VERSION ""

NS_ :

BS_:

BU_: AHLM ASBS CADM CBC DIAGNOST DPDM DTCM ECM EHPS ESC ESL ESM ETM EVCU2 GPF IC IRCM LTM OCM ORC PTS RF_HUB SCCM SGW TBM TCM

BO_ 315 HCP_C1: 8 EVCU2
 SG_ MIL_OnRq_HCP : 6|1@1+ (1,0) [0|0] ""  ECM,ETM,SGW,TBM
 SG_ HybSysEmsMlfAtv : 7|1@1+ (1,0) [0|0] ""  SGW
 SG_ HCPPopUpMessage1 : 8|1@1+ (1,0) [0|0] ""  IC,SGW
 SG_ HCPPopUpMessage2 : 9|1@1+ (1,0) [0|0] ""  IC,SGW
 SG_ HCPPopUpMessage3 : 10|1@1+ (1,0) [0|0] ""  IC,SGW
 SG_ HCPPopUpMessage4 : 11|1@1+ (1,0) [0|0] ""  IC,SGW
 SG_ HCPPopUpMessage5 : 12|1@1+ (1,0) [0|0] ""  IC,SGW
 SG_ HCPPopUpMessage6 : 13|1@1+ (1,0) [0|0] ""  IC,SGW
 SG_ HCPPopUpMessage7 : 14|1@1+ (1,0) [0|0] ""  IC,SGW
 SG_ HCPOutputPwrV : 29|1@1+ (1,0) [0|0] ""  IC,SGW
 SG_ HCPCoachDispV : 30|1@1+ (1,0) [0|0] ""  IC,SGW
 SG_ HCPOutputPwr : 32|8@1+ (1,-100) [-100|100] "%"  IC,SGW
 SG_ HCPCoachDisp : 40|8@1+ (1,-100) [-100|100] "%"  IC,SGW
 SG_ HCPPopUpMessage8 : 15|1@1+ (1,0) [0|0] ""  IC,SGW
 SG_ HCPPopUpMessage9 : 0|1@1+ (1,0) [0|0] ""  IC,SGW
 SG_ HCPPopUpMessage10 : 24|1@1+ (1,0) [0|0] ""  IC,SGW
 SG_ DriveMdstat : 48|4@1+ (1,0) [0|0] ""  CBC,ECM,ETM,IC,LTM,SGW
 SG_ DrvMode_PopUpRqst : 25|4@1+ (1,0) [0|0] ""  IC,SGW
 SG_ GrShiftIndication : 1|2@1+ (1,0) [0|0] ""  IC,SGW
 SG_ HCPPopUpMessage12 : 3|2@1+ (1,0) [0|0] ""  IC,SGW
 SG_ MaxRegenTelltale : 16|2@1+ (1,0) [0|0] ""  IC,SGW
 SG_ MC_HCP_C1 : 52|4@1+ (1,0) [0|15] ""  ECM,IC,SGW,TCM
 SG_ CRC_HCP_C1 : 56|8@1+ (1,0) [0|0] ""  ECM,IC,SGW,TCM
 SG_ ThermalRunaway_LampReq : 18|1@1+ (1,0) [0|0] ""  IC,SGW

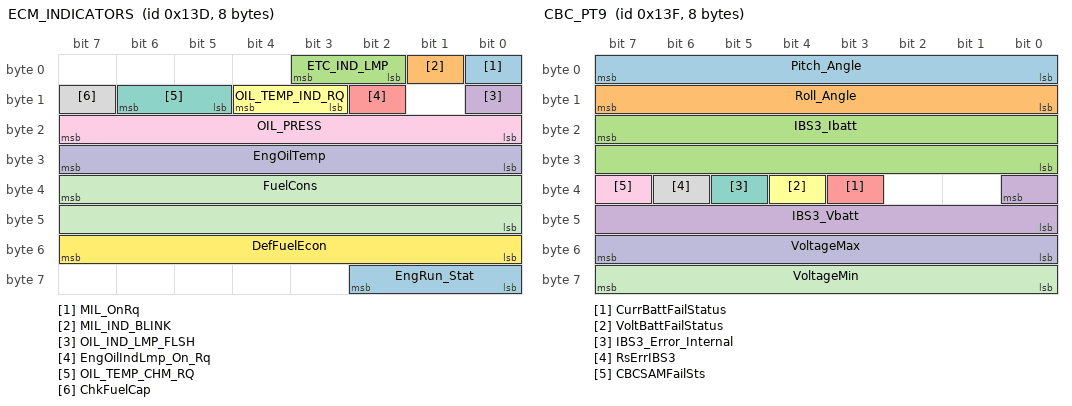
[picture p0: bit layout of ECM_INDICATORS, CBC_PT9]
BO_ 317 ECM_INDICATORS: 8 ECM
 SG_ MIL_OnRq : 0|1@1+ (1,0) [0|0] ""  CBC,ETM,EVCU2,IC,ORC,SGW,TBM
 SG_ MIL_IND_BLINK : 1|1@1+ (1,0) [0|0] ""  CBC,EVCU2,IC,ORC,SGW
 SG_ ETC_IND_LMP : 2|2@1+ (1,0) [0|0] ""  CBC,ETM,IC,SGW,TBM
 SG_ OIL_IND_LMP_FLSH : 8|1@1+ (1,0) [0|0] ""  ETM,IC,SGW,TBM
 SG_ EngOilIndLmp_On_Rq : 10|1@1+ (1,0) [0|0] ""  CBC,ETM,IC,SGW,TBM
 SG_ OIL_TEMP_IND_RQ : 11|2@1+ (1,0) [0|0] ""  ETM,IC,SGW,TBM
 SG_ OIL_TEMP_CHM_RQ : 13|2@1+ (1,0) [0|0] ""  SGW
 SG_ ChkFuelCap : 15|1@1+ (1,0) [0|0] ""  ETM,IC,SGW,TBM
 SG_ OIL_PRESS : 16|8@1+ (4,0) [0|1016] "kPaG"  ETM,IC,SGW,TBM
 SG_ EngOilTemp : 24|8@1+ (1,-40) [-40|160] "∞C"  ETM,IC,SGW,TBM,TCM
 SG_ FuelCons : 39|16@0+ (0.21668,0) [0|14200] "µl/100ms"  ETM,EVCU2,IC,SGW,TBM
 SG_ DefFuelEcon : 48|8@1+ (0.2,0) [0|50] "kmpl"  ETM,IC,SGW,TBM
 SG_ EngRun_Stat : 56|3@1+ (1,0) [0|0] ""  CBC,DTCM,ESC,EVCU2,IC,RF_HUB,SGW,TCM

BO_ 319 CBC_PT9: 8 CBC
 SG_ Pitch_Angle : 0|8@1+ (1,-90) [-90|90] "∞"  IC,SGW
 SG_ Roll_Angle : 8|8@1+ (1,-90) [-90|90] "∞"  IC,SGW
 SG_ IBS3_Ibatt : 23|16@0+ (0.02,-1000) [-1000|310.68] "A"  ECM,ETM,EVCU2,SGW,TBM
 SG_ IBS3_Vbatt : 32|9@0+ (0.025,5) [5|17.75] "V"  ECM,ETM,EVCU2,ORC,SGW,TBM
 SG_ CurrBattFailStatus : 35|1@1+ (1,0) [0|0] ""  ECM,EVCU2,SGW
 SG_ VoltBattFailStatus : 36|1@1+ (1,0) [0|0] ""  ECM,EVCU2,SGW
 SG_ IBS3_Error_Internal : 37|1@1+ (1,0) [0|0] ""  ECM,SGW
 SG_ RsErrIBS3 : 38|1@1+ (1,0) [0|0] ""  ECM,SGW
 SG_ CBCSAMFailSts : 39|1@1+ (1,0) [0|0] ""  ECM,SGW
 SG_ VoltageMax : 48|8@1+ (0.025,10.6) [10.6|16.975] "Volts"  ECM,SGW
 SG_ VoltageMin : 56|8@1+ (0.025,10.6) [10.6|16.975] "Volts"  ECM,SGW

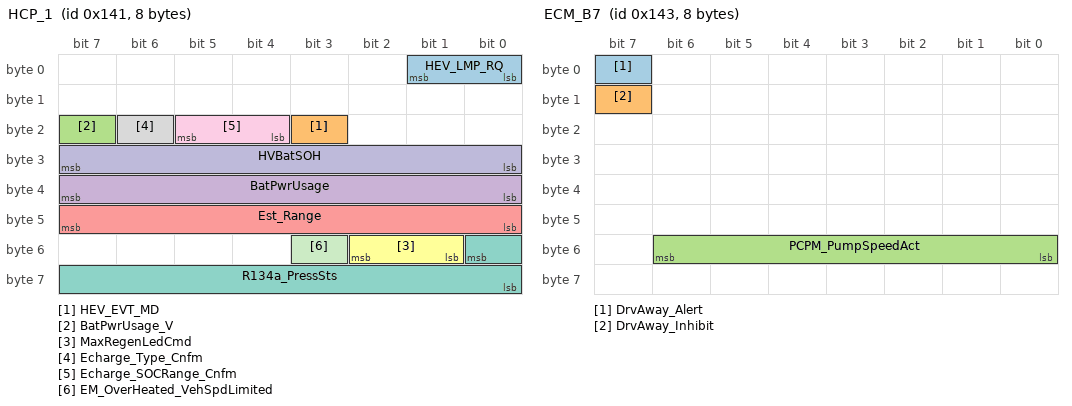
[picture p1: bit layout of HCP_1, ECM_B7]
BO_ 321 HCP_1: 8 EVCU2
 SG_ HEV_LMP_RQ : 0|2@1+ (1,0) [0|0] ""  ETM,IC,ORC,SGW,TBM
 SG_ HEV_EVT_MD : 19|1@1+ (1,0) [0|0] ""  CADM,CBC,ETM,IC,IRCM,SGW,TBM
 SG_ BatPwrUsage_V : 23|1@1+ (1,0) [0|0] ""  SGW
 SG_ BatPwrUsage : 32|8@1+ (1,-125) [-125|130] "kW"  IC,SGW
 SG_ Est_Range : 40|8@1+ (1,0) [0|254] "km"  ETM,IC,SGW,TBM
 SG_ MaxRegenLedCmd : 49|2@1+ (1,0) [0|0] ""  CBC,SGW
 SG_ R134a_PressSts : 48|9@0+ (0.1,0) [0|40] "bar"  CBC,SGW
 SG_ Echarge_Type_Cnfm : 22|1@1+ (1,0) [0|0] ""  CBC,SGW
 SG_ Echarge_SOCRange_Cnfm : 20|2@1+ (1,0) [0|0] ""  CBC,SGW
 SG_ HVBatSOH : 24|8@1+ (0.2,50) [50|100] "%"  ETM,SGW,TBM
 SG_ EM_OverHeated_VehSpdLimited : 51|1@1+ (1,0) [0|0] ""  IC,SGW

BO_ 323 ECM_B7: 8 ECM
 SG_ DrvAway_Alert : 7|1@1+ (1,0) [0|0] ""  IC,ORC,SGW
 SG_ DrvAway_Inhibit : 15|1@1+ (1,0) [0|0] ""  IC,PTS,SGW
 SG_ PCPM_PumpSpeedAct : 48|7@1+ (1,0) [0|100] "%"  SGW

BO_ 327 ESP_B2: 8 ESC
 SG_ MIL_OnRq_ESC : 2|1@1+ (1,0) [0|0] ""  ECM,ETM,SGW,TBM
 SG_ ESCSysEmsMlfAtv : 18|1@1+ (1,0) [0|0] ""  EVCU2,SGW

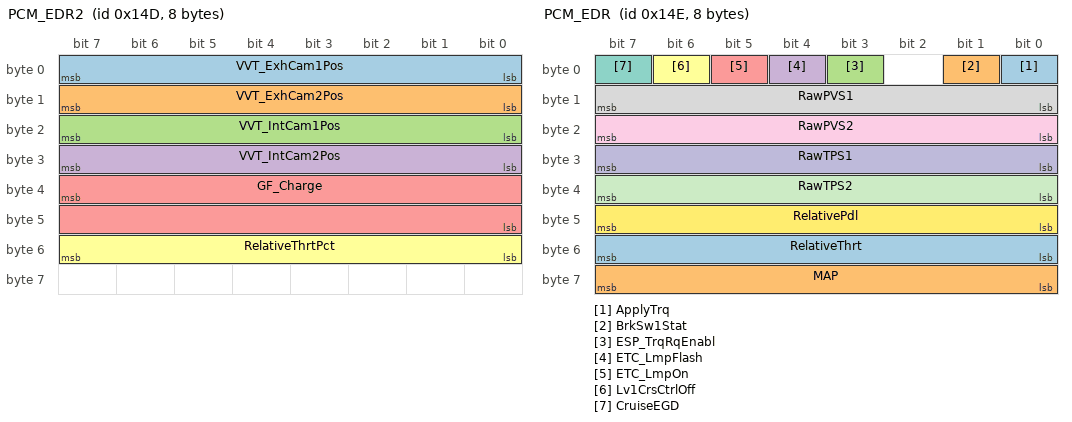
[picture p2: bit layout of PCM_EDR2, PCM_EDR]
BO_ 333 PCM_EDR2: 8 ECM
 SG_ VVT_ExhCam1Pos : 0|8@1+ (1,0) [1|255] "Degrees"  SGW
 SG_ VVT_ExhCam2Pos : 8|8@1+ (1,0) [1|255] "Degrees"  SGW
 SG_ VVT_IntCam1Pos : 16|8@1+ (1,0) [1|255] "Degrees"  SGW
 SG_ VVT_IntCam2Pos : 24|8@1+ (1,0) [1|255] "Degrees"  SGW
 SG_ GF_Charge : 39|16@0+ (0.2,0) [0|13106.8] "mg/cycle/cyl"  ETM,ORC,SGW,TBM
 SG_ RelativeThrtPct : 48|8@1+ (0.4,0) [0|100] "%"  ORC,SGW

BO_ 334 PCM_EDR: 8 ECM
 SG_ ApplyTrq : 0|1@1+ (1,0) [0|0] ""  SGW
 SG_ BrkSw1Stat : 1|1@1+ (1,0) [0|0] ""  ETM,SGW,TBM
 SG_ ESP_TrqRqEnabl : 3|1@1+ (1,0) [0|0] ""  ORC,SGW
 SG_ ETC_LmpFlash : 4|1@1+ (1,0) [0|0] ""  ORC,SGW
 SG_ ETC_LmpOn : 5|1@1+ (1,0) [0|0] ""  ORC,SGW
 SG_ Lv1CrsCtrlOff : 6|1@1+ (1,0) [0|0] ""  ORC,SGW
 SG_ CruiseEGD : 7|1@1+ (1,0) [0|0] ""  SGW
 SG_ RawPVS1 : 8|8@1+ (0.019607843,0) [0|4.98] "Volts"  ORC,SGW
 SG_ RawPVS2 : 16|8@1+ (0.019607843,0) [0|4.98] "Volts"  ORC,SGW
 SG_ RawTPS1 : 24|8@1+ (0.019607843,0) [0|4.98] "Volts"  ORC,SGW
 SG_ RawTPS2 : 32|8@1+ (0.019607843,0) [0|4.98] "Volts"  ORC,SGW
 SG_ RelativePdl : 40|8@1+ (0.019607843,0) [0|4.98] "Volts"  SGW
 SG_ RelativeThrt : 48|8@1+ (0.019607843,0) [0|4.98] "Volts"  SGW
 SG_ MAP : 56|8@1+ (0.8,0) [0|203.2] "kPa"  ESC,SGW

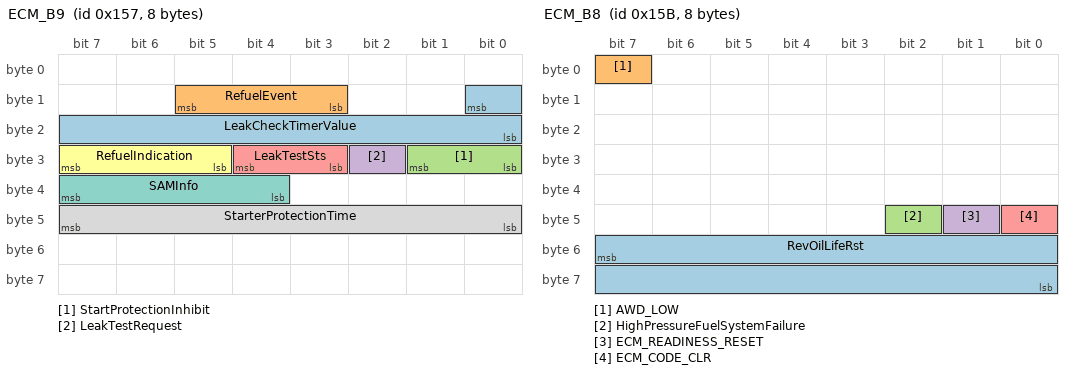
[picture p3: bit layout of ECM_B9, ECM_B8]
BO_ 343 ECM_B9: 8 ECM
 SG_ LeakCheckTimerValue : 8|9@0+ (1,0) [0|510] "min"  CBC,SGW
 SG_ RefuelEvent : 11|3@1+ (1,0) [0|0] ""  CBC,SGW
 SG_ StartProtectionInhibit : 24|2@1+ (1,0) [0|0] ""  IC,SGW
 SG_ LeakTestRequest : 26|1@1+ (1,0) [0|0] ""  CBC,SGW
 SG_ LeakTestSts : 27|2@1+ (1,0) [0|0] ""  CBC,SGW
 SG_ RefuelIndication : 29|3@1+ (1,0) [0|0] ""  IC,SGW
 SG_ SAMInfo : 36|4@1+ (1,0) [0|0] ""  CBC,SGW
 SG_ StarterProtectionTime : 40|8@1+ (1,0) [0|254] "sec"  IC,SGW

BO_ 347 ECM_B8: 8 ECM
 SG_ RevOilLifeRst : 55|16@0+ (1000,0) [0|65534000] "Rev's"  CBC,SGW
 SG_ AWD_LOW : 7|1@1+ (1,0) [0|0] ""  SGW
 SG_ HighPressureFuelSystemFailure : 42|1@1+ (1,0) [0|0] ""  IC,SGW
 SG_ ECM_READINESS_RESET : 41|1@1+ (1,0) [0|0] ""  ESC,EVCU2,SGW,TCM
 SG_ ECM_CODE_CLR : 40|1@1+ (1,0) [0|0] ""  ESC,EVCU2,SGW,TCM

BO_ 423 STATUS_C_ESL: 2 ESL
 SG_ ESLSts : 12|3@1+ (1,0) [0|0] ""  SGW
 SG_ KeyOffWithHighSpeedSts : 15|1@1+ (1,0) [0|0] ""  CBC,SGW

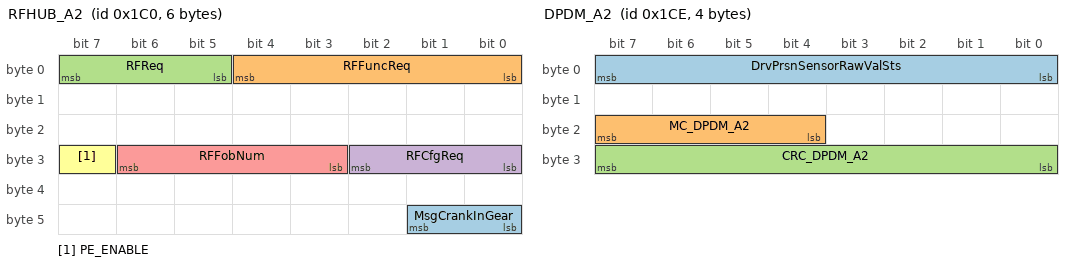
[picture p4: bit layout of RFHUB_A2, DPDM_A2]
BO_ 448 RFHUB_A2: 6 RF_HUB
 SG_ MsgCrankInGear : 40|2@1+ (1,0) [0|0] ""  IC,SGW
 SG_ RFFuncReq : 0|5@1+ (1,0) [0|0] ""  CBC,IC,SGW,TBM
 SG_ RFReq : 5|3@1+ (1,0) [0|0] ""  CBC,ETM,IC,SGW,TBM
 SG_ RFCfgReq : 24|3@1+ (1,0) [0|0] ""  CBC,SGW
 SG_ RFFobNum : 27|4@1+ (1,0) [0|0] ""  CBC,SGW
 SG_ PE_ENABLE : 31|1@1+ (1,0) [0|0] ""  CBC,SGW

BO_ 456 CBC_VTA: 4 CBC
 SG_ VTA_STAT : 0|3@1+ (1,0) [0|0] ""  ETM,RF_HUB,SGW,TBM
 SG_ FOA_Msg_Req : 24|3@1+ (1,0) [0|0] ""  IC,SGW

BO_ 462 DPDM_A2: 4 DPDM
 SG_ DrvPrsnSensorRawValSts : 0|8@1+ (1,0) [0|255] ""  ECM,SGW
 SG_ MC_DPDM_A2 : 20|4@1+ (1,0) [0|15] ""  ECM,SGW
 SG_ CRC_DPDM_A2 : 24|8@1+ (1,0) [0|0] ""  ECM,SGW

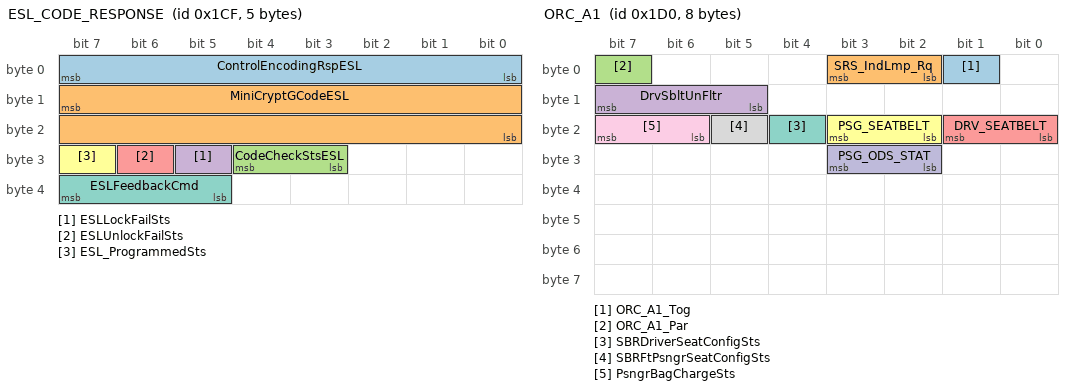
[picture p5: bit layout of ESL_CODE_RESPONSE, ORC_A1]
BO_ 463 ESL_CODE_RESPONSE: 5 ESL
 SG_ ControlEncodingRspESL : 0|8@1+ (1,0) [0|0] ""  CBC,SGW
 SG_ MiniCryptGCodeESL : 15|16@0+ (1,0) [0|0] ""  CBC,SGW
 SG_ CodeCheckStsESL : 27|2@1+ (1,0) [0|0] ""  CBC,SGW
 SG_ ESLLockFailSts : 29|1@1+ (1,0) [0|0] ""  CBC,SGW
 SG_ ESLUnlockFailSts : 30|1@1+ (1,0) [0|0] ""  CBC,SGW
 SG_ ESL_ProgrammedSts : 31|1@1+ (1,0) [0|0] ""  SGW
 SG_ ESLFeedbackCmd : 37|3@1+ (1,0) [0|0] ""  CBC,SGW

BO_ 464 ORC_A1: 8 ORC
 SG_ ORC_A1_Tog : 1|1@1+ (1,0) [0|0] ""  CADM,IRCM,SGW
 SG_ SRS_IndLmp_Rq : 2|2@1+ (1,0) [0|0] ""  ETM,IC,SGW,TBM
 SG_ ORC_A1_Par : 7|1@1+ (1,0) [0|0] ""  CADM,IRCM,SGW
 SG_ DrvSbltUnFltr : 13|3@1+ (1,0) [0|0] ""  ECM,SGW,TCM
 SG_ DRV_SEATBELT : 16|2@1+ (1,0) [0|0] ""  CADM,ECM,ESC,ETM,EVCU2,IC,IRCM,SGW,TBM
 SG_ PSG_SEATBELT : 18|2@1+ (1,0) [0|0] ""  ESC,ETM,IC,OCM,SGW,TBM
 SG_ SBRDriverSeatConfigSts : 20|1@1+ (1,0) [0|0] ""  IC,SGW
 SG_ SBRFtPsngrSeatConfigSts : 21|1@1+ (1,0) [0|0] ""  IC,SGW
 SG_ PsngrBagChargeSts : 22|2@1+ (1,0) [0|0] ""  IC,SGW
 SG_ PSG_ODS_STAT : 26|2@1+ (1,0) [0|0] ""  ETM,IC,RF_HUB,SGW,TBM

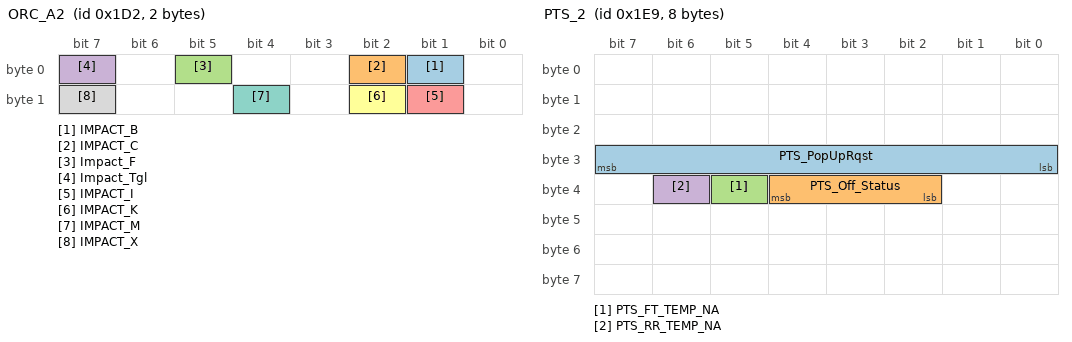
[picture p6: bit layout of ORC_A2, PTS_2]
BO_ 466 ORC_A2: 2 ORC
 SG_ IMPACT_B : 1|1@1+ (1,0) [0|0] ""  ETM,SGW,TBM
 SG_ IMPACT_C : 2|1@1+ (1,0) [0|0] ""  ETM,SGW,TBM
 SG_ Impact_F : 5|1@1+ (1,0) [0|0] ""  ETM,SGW,TBM
 SG_ Impact_Tgl : 7|1@1+ (1,0) [0|0] ""  CBC,ECM,ETM,EVCU2,OCM,SGW,TBM
 SG_ IMPACT_I : 9|1@1+ (1,0) [0|0] ""  ETM,SGW,TBM
 SG_ IMPACT_K : 10|1@1+ (1,0) [0|0] ""  ETM,SGW,TBM
 SG_ IMPACT_M : 12|1@1+ (1,0) [0|0] ""  ETM,SGW,TBM
 SG_ IMPACT_X : 15|1@1+ (1,0) [0|0] ""  CBC,ECM,ETM,EVCU2,OCM,SGW,TBM

BO_ 469 ORC_A4: 8 ORC
 SG_ ORC_Health : 23|1@1+ (1,0) [0|0] ""  EVCU2,SGW

BO_ 489 PTS_2: 8 PTS
 SG_ PTS_PopUpRqst : 24|8@1+ (1,0) [0|0] ""  IC,SGW
 SG_ PTS_Off_Status : 34|3@1+ (1,0) [0|0] ""  IC,SGW
 SG_ PTS_FT_TEMP_NA : 37|1@1+ (1,0) [0|0] ""  IC,SGW
 SG_ PTS_RR_TEMP_NA : 38|1@1+ (1,0) [0|0] ""  IC,SGW

BO_ 491 STATUS_C_PTS: 8 PTS
 SG_ PTS_DBD : 16|1@1+ (1,0) [0|0] ""  IC,SGW

BO_ 502 PTS_1: 8 PTS
 SG_ PTS_CFG_STAT : 1|2@1+ (1,0) [0|0] ""  CBC,SGW
 SG_ PTS_FT_NA : 3|1@1+ (1,0) [0|0] ""  IC,SGW
 SG_ PTS_RR_NA : 4|1@1+ (1,0) [0|0] ""  IC,SGW
 SG_ PTS_SRV_RQ : 5|1@1+ (1,0) [0|0] ""  IC,SGW
 SG_ PTS_AlrFL : 8|4@1+ (1,0) [0|0] ""  IC,SGW
 SG_ PTS_GraphicFL : 14|2@1+ (1,0) [0|0] ""  IC,SGW
 SG_ PTS_AlrFR : 16|4@1+ (1,0) [0|0] ""  IC,SGW
 SG_ PTS_GraphicFR : 22|2@1+ (1,0) [0|0] ""  IC,SGW
 SG_ PTS_AlrRL : 24|4@1+ (1,0) [0|0] ""  CBC,IC,SGW
 SG_ PTS_GraphicRL : 30|2@1+ (1,0) [0|0] ""  IC,SGW
 SG_ PTS_AlrRR : 32|4@1+ (1,0) [0|0] ""  CBC,IC,SGW
 SG_ PTS_GraphicRR : 38|2@1+ (1,0) [0|0] ""  IC,SGW
 SG_ PTS_AlrFC : 40|4@1+ (1,0) [0|0] ""  IC,SGW
 SG_ PTS_GraphicFC : 46|2@1+ (1,0) [0|0] ""  IC,SGW
 SG_ PTS_AlrRC : 48|4@1+ (1,0) [0|0] ""  CBC,IC,SGW
 SG_ PTS_GraphicRC : 54|2@1+ (1,0) [0|0] ""  IC,SGW
 SG_ PTS_FT_SRV : 58|1@1+ (1,0) [0|0] ""  ETM,IC,SGW,TBM
 SG_ PTS_RR_SRV : 59|1@1+ (1,0) [0|0] ""  ETM,IC,SGW,TBM
 SG_ PTS_STAT : 60|2@1+ (1,0) [0|0] ""  CBC,SGW

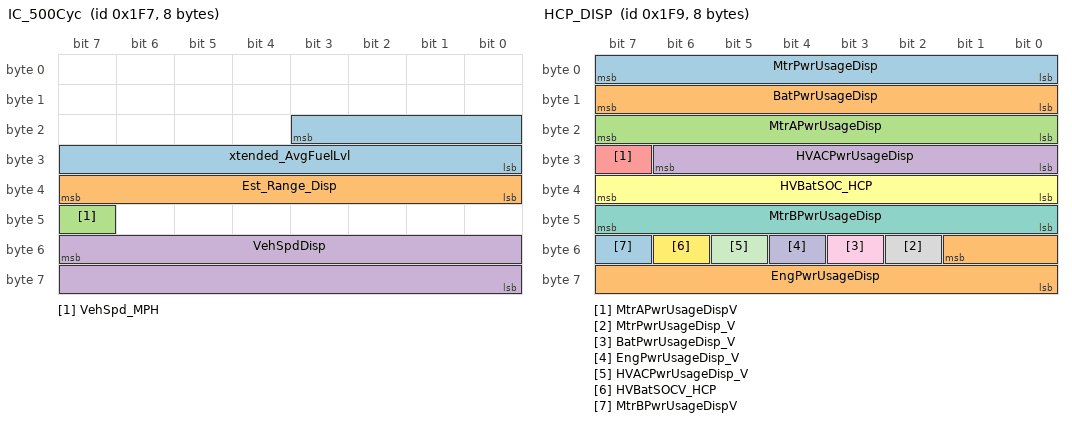
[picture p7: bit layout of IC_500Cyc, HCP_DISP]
BO_ 503 IC_500Cyc: 8 IC
 SG_ xtended_AvgFuelLvl : 19|12@0+ (0.5,0) [0|2047] "liters"  CBC,ECM,SGW
 SG_ Est_Range_Disp : 32|8@1+ (1,0) [0|254] ""  CBC,ETM,SGW,TBM
 SG_ VehSpd_MPH : 47|1@1+ (1,0) [0|0] ""  CBC,SGW
 SG_ VehSpdDisp : 55|16@0+ (1,0) [0|65534] ""  CBC,SGW

BO_ 505 HCP_DISP: 8 EVCU2
 SG_ MtrPwrUsageDisp : 0|8@1+ (1,-125) [-125|130] "kW"  IC,SGW
 SG_ BatPwrUsageDisp : 8|8@1+ (1,-125) [-125|130] "kW"  CBC,ETM,SGW,TBM
 SG_ MtrAPwrUsageDisp : 16|8@1+ (1,-125) [-125|130] "kW"  CBC,ETM,SGW
 SG_ HVACPwrUsageDisp : 24|7@1+ (1,0) [0|127] "kW"  CBC,ETM,SGW,TBM
 SG_ MtrAPwrUsageDispV : 31|1@1+ (1,0) [0|0] ""  CBC,ETM,SGW
 SG_ HVBatSOC_HCP : 32|8@1+ (0.3922,0) [0|100] "%"  CBC,ETM,IC,SGW,TBM
 SG_ MtrBPwrUsageDisp : 40|8@1+ (1,-125) [-125|130] "kW"  CBC,ETM,SGW
 SG_ MtrPwrUsageDisp_V : 50|1@1+ (1,0) [0|0] ""  IC,SGW
 SG_ BatPwrUsageDisp_V : 51|1@1+ (1,0) [0|0] ""  CBC,ETM,SGW
 SG_ EngPwrUsageDisp_V : 52|1@1+ (1,0) [0|0] ""  CBC,ETM,IC,SGW
 SG_ HVACPwrUsageDisp_V : 53|1@1+ (1,0) [0|0] ""  CBC,ETM,SGW
 SG_ HVBatSOCV_HCP : 54|1@1+ (1,0) [0|0] ""  CBC,ETM,IC,SGW,TBM
 SG_ MtrBPwrUsageDispV : 55|1@1+ (1,0) [0|0] ""  CBC,ETM,SGW
 SG_ EngPwrUsageDisp : 49|10@0+ (1,0) [0|1023] "kW"  CBC,ETM,IC,SGW

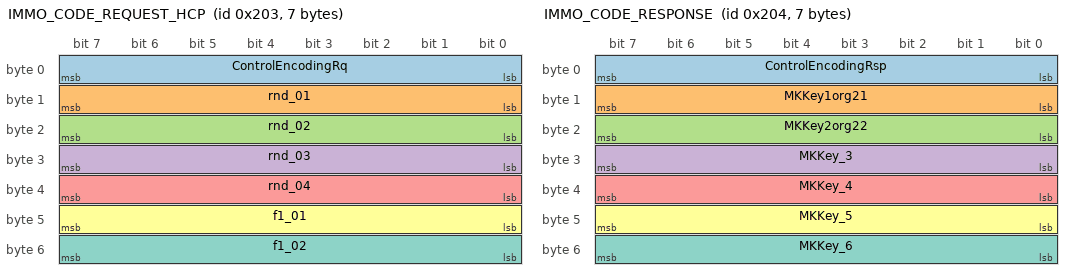
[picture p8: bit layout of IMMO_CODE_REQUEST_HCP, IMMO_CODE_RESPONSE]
BO_ 515 IMMO_CODE_REQUEST_HCP: 7 EVCU2
 SG_ ControlEncodingRq : 0|8@1+ (1,0) [0|0] ""  CBC,SGW
 SG_ rnd_01 : 8|8@1+ (1,0) [0|255] ""  CBC,SGW
 SG_ rnd_02 : 16|8@1+ (1,0) [0|255] ""  CBC,SGW
 SG_ rnd_03 : 24|8@1+ (1,0) [0|255] ""  CBC,SGW
 SG_ rnd_04 : 32|8@1+ (1,0) [0|255] ""  CBC,SGW
 SG_ f1_01 : 40|8@1+ (1,0) [0|255] ""  CBC,SGW
 SG_ f1_02 : 48|8@1+ (1,0) [0|255] ""  CBC,SGW

BO_ 516 IMMO_CODE_RESPONSE: 7 CBC
 SG_ ControlEncodingRsp : 0|8@1+ (1,0) [0|0] ""  ECM,SGW
 SG_ MKKey1org21 : 8|8@1+ (1,0) [0|255] ""  ECM,SGW
 SG_ MKKey2org22 : 16|8@1+ (1,0) [0|255] ""  ECM,SGW
 SG_ MKKey_3 : 24|8@1+ (1,0) [0|255] ""  ECM,SGW
 SG_ MKKey_4 : 32|8@1+ (1,0) [0|255] ""  ECM,SGW
 SG_ MKKey_5 : 40|8@1+ (1,0) [0|255] ""  ECM,SGW
 SG_ MKKey_6 : 48|8@1+ (1,0) [0|255] ""  ECM,SGW

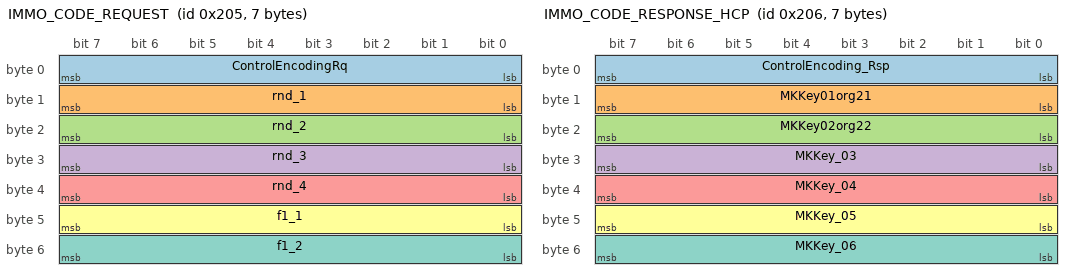
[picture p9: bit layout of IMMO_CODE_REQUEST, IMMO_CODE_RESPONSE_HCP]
BO_ 517 IMMO_CODE_REQUEST: 7 ECM
 SG_ ControlEncodingRq : 0|8@1+ (1,0) [0|0] ""  CBC,SGW
 SG_ rnd_1 : 8|8@1+ (1,0) [0|255] ""  CBC,SGW
 SG_ rnd_2 : 16|8@1+ (1,0) [0|255] ""  CBC,SGW
 SG_ rnd_3 : 24|8@1+ (1,0) [0|255] ""  CBC,SGW
 SG_ rnd_4 : 32|8@1+ (1,0) [0|255] ""  CBC,SGW
 SG_ f1_1 : 40|8@1+ (1,0) [0|255] ""  CBC,SGW
 SG_ f1_2 : 48|8@1+ (1,0) [0|255] ""  CBC,SGW

BO_ 518 IMMO_CODE_RESPONSE_HCP: 7 CBC
 SG_ ControlEncoding_Rsp : 0|8@1+ (1,0) [0|0] ""  EVCU2,SGW
 SG_ MKKey01org21 : 8|8@1+ (1,0) [0|255] ""  EVCU2,SGW
 SG_ MKKey02org22 : 16|8@1+ (1,0) [0|255] ""  EVCU2,SGW
 SG_ MKKey_03 : 24|8@1+ (1,0) [0|255] ""  EVCU2,SGW
 SG_ MKKey_04 : 32|8@1+ (1,0) [0|255] ""  EVCU2,SGW
 SG_ MKKey_05 : 40|8@1+ (1,0) [0|255] ""  EVCU2,SGW
 SG_ MKKey_06 : 48|8@1+ (1,0) [0|255] ""  EVCU2,SGW

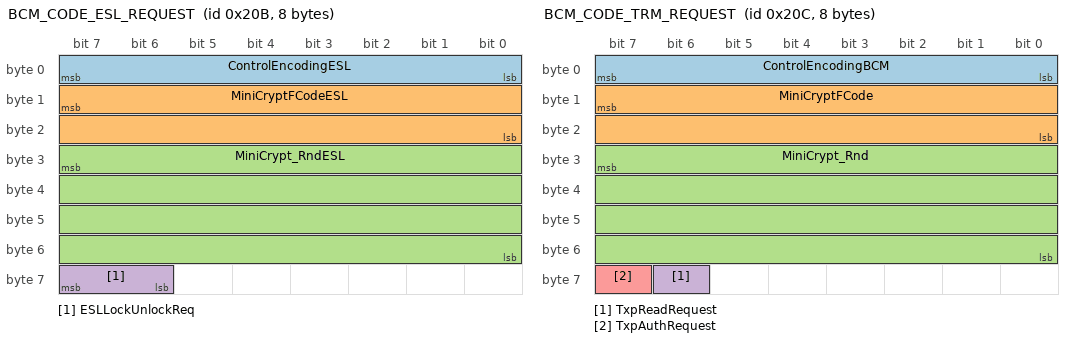
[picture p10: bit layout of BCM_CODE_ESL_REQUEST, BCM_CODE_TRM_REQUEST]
BO_ 523 BCM_CODE_ESL_REQUEST: 8 CBC
 SG_ ControlEncodingESL : 0|8@1+ (1,0) [0|0] ""  ESL,SGW
 SG_ MiniCryptFCodeESL : 15|16@0+ (1,0) [0|0] ""  ESL,SGW
 SG_ MiniCrypt_RndESL : 31|32@0+ (1,0) [0|0] ""  ESL,SGW
 SG_ ESLLockUnlockReq : 62|2@1+ (1,0) [0|0] ""  ESL,SGW

BO_ 524 BCM_CODE_TRM_REQUEST: 8 CBC
 SG_ ControlEncodingBCM : 0|8@1+ (1,0) [0|0] ""  RF_HUB,SGW
 SG_ MiniCryptFCode : 15|16@0+ (1,0) [0|0] ""  RF_HUB,SGW
 SG_ MiniCrypt_Rnd : 31|32@0+ (1,0) [0|0] ""  RF_HUB,SGW
 SG_ TxpReadRequest : 62|1@1+ (1,0) [0|0] ""  RF_HUB,SGW
 SG_ TxpAuthRequest : 63|1@1+ (1,0) [0|0] ""  RF_HUB,SGW

BO_ 525 BCM_MINICRYPT_ACK: 1 CBC
 SG_ MinicryptReceptionSts : 7|1@1+ (1,0) [0|0] ""  RF_HUB,SGW

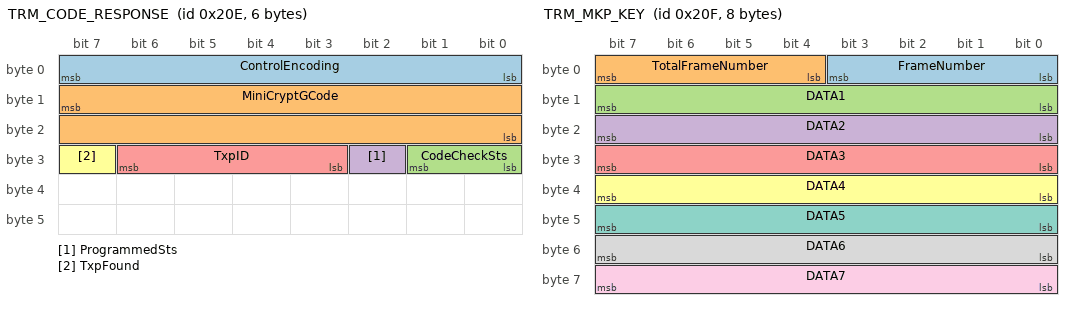
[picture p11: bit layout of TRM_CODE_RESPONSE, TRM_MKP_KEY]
BO_ 526 TRM_CODE_RESPONSE: 6 RF_HUB
 SG_ ControlEncoding : 0|8@1+ (1,0) [0|0] ""  CBC,SGW
 SG_ MiniCryptGCode : 15|16@0+ (1,0) [0|0] ""  CBC,SGW
 SG_ CodeCheckSts : 24|2@1+ (1,0) [0|0] ""  CBC,SGW
 SG_ ProgrammedSts : 26|1@1+ (1,0) [0|0] ""  CBC,SGW
 SG_ TxpID : 27|4@1+ (1,0) [0|0] ""  CBC,SGW
 SG_ TxpFound : 31|1@1+ (1,0) [0|0] ""  CBC,SGW

BO_ 527 TRM_MKP_KEY: 8 RF_HUB
 SG_ FrameNumber : 0|4@1+ (1,0) [0|0] ""  CBC,SGW
 SG_ TotalFrameNumber : 4|4@1+ (1,0) [0|0] ""  CBC,SGW
 SG_ DATA1 : 8|8@1+ (1,0) [0|0] ""  CBC,SGW
 SG_ DATA2 : 16|8@1+ (1,0) [0|0] ""  CBC,SGW
 SG_ DATA3 : 24|8@1+ (1,0) [0|0] ""  CBC,SGW
 SG_ DATA4 : 32|8@1+ (1,0) [0|0] ""  CBC,SGW
 SG_ DATA5 : 40|8@1+ (1,0) [0|0] ""  CBC,SGW
 SG_ DATA6 : 48|8@1+ (1,0) [0|0] ""  CBC,SGW
 SG_ DATA7 : 56|8@1+ (1,0) [0|0] ""  CBC,SGW

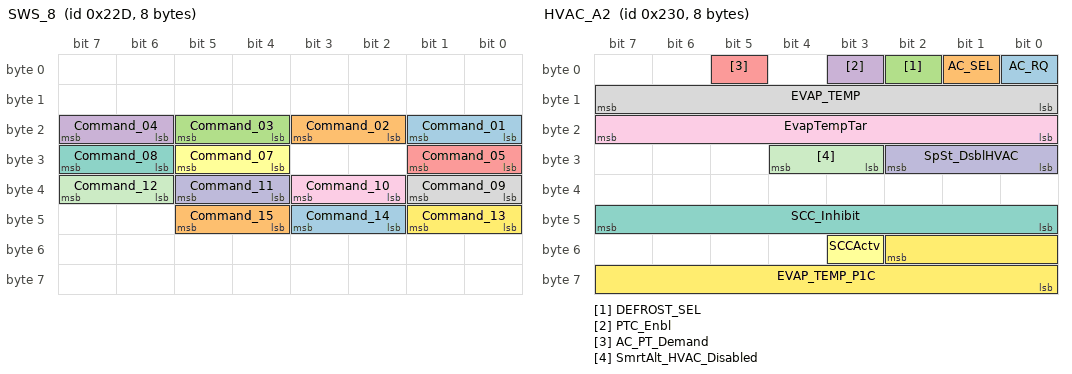
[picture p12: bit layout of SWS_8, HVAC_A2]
BO_ 557 SWS_8: 8 CBC
 SG_ Command_01 : 16|2@1+ (1,0) [0|0] ""  CADM,SGW
 SG_ Command_02 : 18|2@1+ (1,0) [0|0] ""  CADM,SGW
 SG_ Command_03 : 20|2@1+ (1,0) [0|0] ""  CADM,SGW
 SG_ Command_04 : 22|2@1+ (1,0) [0|0] ""  CADM,SGW
 SG_ Command_05 : 24|2@1+ (1,0) [0|0] ""  CADM,SGW
 SG_ Command_07 : 28|2@1+ (1,0) [0|0] ""  CADM,SGW
 SG_ Command_08 : 30|2@1+ (1,0) [0|0] ""  CADM,SGW
 SG_ Command_09 : 32|2@1+ (1,0) [0|0] ""  CADM,SGW
 SG_ Command_10 : 34|2@1+ (1,0) [0|0] ""  CADM,SGW
 SG_ Command_11 : 36|2@1+ (1,0) [0|0] ""  CADM,ETM,IC,SGW,TBM
 SG_ Command_12 : 38|2@1+ (1,0) [0|0] ""  CADM,ETM,IC,SGW,TBM
 SG_ Command_13 : 40|2@1+ (1,0) [0|0] ""  CADM,ETM,IC,SGW,TBM
 SG_ Command_14 : 42|2@1+ (1,0) [0|0] ""  CADM,ETM,IC,SGW,TBM
 SG_ Command_15 : 44|2@1+ (1,0) [0|0] ""  CADM,ETM,IC,SGW,TBM

BO_ 560 HVAC_A2: 8 CBC
 SG_ AC_RQ : 0|1@1+ (1,0) [0|0] ""  ECM,EVCU2,SGW
 SG_ AC_SEL : 1|1@1+ (1,0) [0|0] ""  ECM,SGW
 SG_ DEFROST_SEL : 2|1@1+ (1,0) [0|0] ""  ECM,EVCU2,SGW
 SG_ PTC_Enbl : 3|1@1+ (1,0) [0|0] ""  ECM,SGW
 SG_ AC_PT_Demand : 5|1@1+ (1,0) [0|0] ""  ECM,SGW
 SG_ SCCActv : 51|1@1+ (1,0) [0|0] ""  EVCU2,IC,SGW
 SG_ SCC_Inhibit : 40|8@1+ (1,0) [0|0] ""  IC,SGW
 SG_ EVAP_TEMP : 8|8@1+ (0.5,-20) [-20|107] "∞C"  ECM,SGW
 SG_ EvapTempTar : 16|8@1+ (0.5,-20) [-20|107] "∞C"  ECM,EVCU2,SGW
 SG_ SpSt_DsblHVAC : 24|3@1+ (1,0) [0|0] ""  ECM,SGW
 SG_ SmrtAlt_HVAC_Disabled : 27|2@1+ (1,0) [0|0] ""  SGW
 SG_ EVAP_TEMP_P1C : 50|11@0+ (0.1,-40) [-40|85] "∞C"  EVCU2,SGW

BO_ 584 PN14_STAT: 8 CBC
 SG_ PN14_LS_Actv : 0|1@1+ (1,0) [0|0] ""  IC,SGW
 SG_ Batt_ST_Crit : 42|1@1+ (1,0) [0|0] ""  IC,SGW

CM_ SG_ 584 Batt_ST_Crit "Battery reached critical state";
BA_DEF_ BO_  "App-Botschaft" ENUM  "nein","ja";
BA_DEF_ BO_  "CanMsgMinLen" INT 0 8;
BA_DEF_ BO_  "DiagRequest" ENUM  "nein","ja";
BA_DEF_ BO_  "DiagResponse" ENUM  "nein","ja";
BA_DEF_ BO_  "DiagState" ENUM  "nein","ja";
BA_DEF_ BO_  "GenMsgCycleTime" INT 0 65535;
BA_DEF_ BO_  "GenMsgCycleTimeActive" INT 0 65535;
BA_DEF_ BO_  "GenMsgDelayTime" INT 0 65535;
BA_DEF_ BO_  "GenMsgNrOfRepetitions" INT 0 65535;
BA_DEF_ BO_  "GenMsgSendType" ENUM  "cyclicX","spontanX","cyclicIfActiveX","spontanWithDelay","cyclicAndSpontanX","cyclicAndSpontanWithDelay","spontanWithRepitition","cyclicIfActiveAndSpontanWD","cyclicIfActiveFast","cyclicWithRepeatOnDemand","none";
BA_DEF_ BO_  "GenMsgStartDelayTime" INT 0 65535;
BA_DEF_ BO_  "GenMsgStartValue" STRING ;
BA_DEF_ BO_  "NWM-Botschaft" ENUM  "nein","ja";
BA_DEF_ BO_  "TpTxIndex" INT 0 99;
BA_DEF_ SG_  "FlexKomComment" STRING ;
BA_DEF_ SG_  "FlexKomIsMotorola" ENUM  "nein","ja";
BA_DEF_ SG_  "FlexKomSID" INT 0 2147483647;
BA_DEF_ SG_  "FlexKomSigLaenge" INT 0 64;
BA_DEF_ SG_  "FlexKomSigName" STRING ;
BA_DEF_ SG_  "FlexKomSigStartPos" INT 0 63;
BA_DEF_ SG_  "FlexKomSigStartValue" STRING ;
BA_DEF_ SG_  "GenSigCycleTime" INT 0 65535;
BA_DEF_ SG_  "GenSigCycleTimeActive" INT 0 65535;
BA_DEF_ SG_  "GenSigSendType" ENUM  "cyclicX","spontanX","cyclicIfActiveX","spontanWithDelay","cyclicAndSpontanX","cyclicAndSpontanWithDelay","spontanWithRepitition","cyclicIfActiveAndSpontanWD","cyclicIfActiveFast","cyclicWithRepeatOnDemand","none";
BA_DEF_ SG_  "GenSigSNA" STRING ;
BA_DEF_ SG_  "GenSigStartValue" HEX 0 2147483648;
BA_DEF_ SG_  "GenSigTimeout_AHLM" INT 0 65535;
BA_DEF_ SG_  "GenSigTimeout_ASBS" INT 0 65535;
BA_DEF_ SG_  "GenSigTimeout_CBC" INT 0 65535;
BA_DEF_ SG_  "GenSigTimeout_DPDM" INT 0 65535;
BA_DEF_ SG_  "GenSigTimeout_DTCM" INT 0 65535;
BA_DEF_ SG_  "GenSigTimeout_EHPS" INT 0 65535;
BA_DEF_ SG_  "GenSigTimeout_ESC" INT 0 65535;
BA_DEF_ SG_  "GenSigTimeout_ESL" INT 0 65535;
BA_DEF_ SG_  "GenSigTimeout_ESM" INT 0 65535;
BA_DEF_ SG_  "GenSigTimeout_ETM" INT 0 65535;
BA_DEF_ SG_  "GenSigTimeout_IC" INT 0 65535;
BA_DEF_ SG_  "GenSigTimeout_OCM" INT 0 65535;
BA_DEF_ SG_  "GenSigTimeout_ORC" INT 0 65535;
BA_DEF_ SG_  "GenSigTimeout_PTS" INT 0 65535;
BA_DEF_ SG_  "GenSigTimeout_RF_HUB" INT 0 65535;
BA_DEF_ SG_  "GenSigTimeout_SCCM" INT 0 65535;
BA_DEF_ SG_  "GenSigTimeout_TBM" INT 0 65535;
BA_DEF_ SG_  "GenSigTimeout_TCM" INT 0 65535;
BA_DEF_ SG_  "GenSigTimeout_TPM" INT 0 65535;
BA_DEF_ SG_  "RID" STRING ;
BA_DEF_ SG_  "SystemSignalLongSymbol" STRING ;
BA_DEF_DEF_  "App-Botschaft" "nein";
BA_DEF_DEF_  "CanMsgMinLen" 0;
BA_DEF_DEF_  "DiagRequest" "nein";
BA_DEF_DEF_  "DiagResponse" "nein";
BA_DEF_DEF_  "DiagState" "nein";
BA_DEF_DEF_  "GenMsgCycleTime" 0;
BA_DEF_DEF_  "GenMsgCycleTimeActive" 0;
BA_DEF_DEF_  "GenMsgDelayTime" 0;
BA_DEF_DEF_  "GenMsgNrOfRepetitions" 0;
BA_DEF_DEF_  "GenMsgSendType" "cyclicX";
BA_DEF_DEF_  "GenMsgStartDelayTime" 0;
BA_DEF_DEF_  "GenMsgStartValue" "";
BA_DEF_DEF_  "NWM-Botschaft" "nein";
BA_DEF_DEF_  "TpTxIndex" 0;
BA_DEF_DEF_  "FlexKomComment" "";
BA_DEF_DEF_  "FlexKomIsMotorola" "nein";
BA_DEF_DEF_  "FlexKomSID" 0;
BA_DEF_DEF_  "FlexKomSigLaenge" 0;
BA_DEF_DEF_  "FlexKomSigName" "";
BA_DEF_DEF_  "FlexKomSigStartPos" 0;
BA_DEF_DEF_  "FlexKomSigStartValue" "";
BA_DEF_DEF_  "GenSigCycleTime" 0;
BA_DEF_DEF_  "GenSigCycleTimeActive" 0;
BA_DEF_DEF_  "GenSigSendType" "cyclicX";
BA_DEF_DEF_  "GenSigSNA" "";
BA_DEF_DEF_  "GenSigStartValue" 0;
BA_DEF_DEF_  "GenSigTimeout_AHLM" 0;
BA_DEF_DEF_  "GenSigTimeout_ASBS" 0;
BA_DEF_DEF_  "GenSigTimeout_CBC" 0;
BA_DEF_DEF_  "GenSigTimeout_DPDM" 0;
BA_DEF_DEF_  "GenSigTimeout_DTCM" 0;
BA_DEF_DEF_  "GenSigTimeout_EHPS" 0;
BA_DEF_DEF_  "GenSigTimeout_ESC" 0;
BA_DEF_DEF_  "GenSigTimeout_ESL" 0;
BA_DEF_DEF_  "GenSigTimeout_ESM" 0;
BA_DEF_DEF_  "GenSigTimeout_ETM" 0;
BA_DEF_DEF_  "GenSigTimeout_IC" 0;
BA_DEF_DEF_  "GenSigTimeout_OCM" 0;
BA_DEF_DEF_  "GenSigTimeout_ORC" 0;
BA_DEF_DEF_  "GenSigTimeout_PTS" 0;
BA_DEF_DEF_  "GenSigTimeout_RF_HUB" 0;
BA_DEF_DEF_  "GenSigTimeout_SCCM" 0;
BA_DEF_DEF_  "GenSigTimeout_TBM" 0;
BA_DEF_DEF_  "GenSigTimeout_TCM" 0;
BA_DEF_DEF_  "GenSigTimeout_TPM" 0;
BA_DEF_DEF_  "RID" "";
BA_DEF_DEF_  "SystemSignalLongSymbol" "";
BA_ "GenMsgStartValue" BO_ 315 "00000000646400FFh";
BA_ "GenMsgNrOfRepetitions" BO_ 315 2;
BA_ "GenMsgDelayTime" BO_ 315 20;
BA_ "GenMsgCycleTime" BO_ 315 100;
BA_ "GenMsgStartValue" BO_ 317 "6000FFFFFFFFFF07h";
BA_ "GenMsgNrOfRepetitions" BO_ 317 2;
BA_ "GenMsgDelayTime" BO_ 317 20;
BA_ "GenMsgCycleTime" BO_ 317 100;
BA_ "GenMsgStartValue" BO_ 319 "5A5AFFFF01FF0000h";
BA_ "GenMsgStartDelayTime" BO_ 319 30;
BA_ "GenMsgNrOfRepetitions" BO_ 319 2;
BA_ "GenMsgDelayTime" BO_ 319 20;
BA_ "GenMsgCycleTime" BO_ 319 100;
BA_ "GenMsgStartValue" BO_ 321 "03000E0000FF01FFh";
BA_ "GenMsgNrOfRepetitions" BO_ 321 2;
BA_ "GenMsgDelayTime" BO_ 321 20;
BA_ "GenMsgCycleTime" BO_ 321 100;
BA_ "GenMsgStartValue" BO_ 323 "7F0FFF0000000000h";
BA_ "GenMsgNrOfRepetitions" BO_ 323 2;
BA_ "GenMsgDelayTime" BO_ 323 20;
BA_ "GenMsgCycleTime" BO_ 323 100;
BA_ "GenMsgStartValue" BO_ 327 "C1FE01FE00000000h";
BA_ "GenMsgNrOfRepetitions" BO_ 327 2;
BA_ "GenMsgDelayTime" BO_ 327 20;
BA_ "GenMsgCycleTime" BO_ 327 100;
BA_ "GenMsgStartValue" BO_ 333 "FFFFFFFF0000FF00h";
BA_ "GenMsgNrOfRepetitions" BO_ 333 2;
BA_ "GenMsgDelayTime" BO_ 333 20;
BA_ "GenMsgCycleTime" BO_ 333 100;
BA_ "GenMsgStartValue" BO_ 334 "00FFFFFFFFFFFFFFh";
BA_ "GenMsgNrOfRepetitions" BO_ 334 2;
BA_ "GenMsgDelayTime" BO_ 334 20;
BA_ "GenMsgCycleTime" BO_ 334 100;
BA_ "GenMsgStartValue" BO_ 343 "00000000F00000FFh";
BA_ "GenMsgNrOfRepetitions" BO_ 343 2;
BA_ "GenMsgDelayTime" BO_ 343 20;
BA_ "GenMsgCycleTime" BO_ 343 100;
BA_ "GenMsgStartValue" BO_ 347 "000000000000FFFFh";
BA_ "GenMsgNrOfRepetitions" BO_ 347 2;
BA_ "GenMsgDelayTime" BO_ 347 20;
BA_ "GenMsgCycleTime" BO_ 347 100;
BA_ "GenMsgStartValue" BO_ 423 "0000h";
BA_ "GenMsgNrOfRepetitions" BO_ 423 2;
BA_ "GenMsgDelayTime" BO_ 423 20;
BA_ "GenMsgCycleTime" BO_ 423 250;
BA_ "GenMsgStartValue" BO_ 448 "000000000000h";
BA_ "GenMsgSendType" BO_ 448 5;
BA_ "GenMsgNrOfRepetitions" BO_ 448 2;
BA_ "GenMsgDelayTime" BO_ 448 20;
BA_ "GenMsgCycleTime" BO_ 448 200;
BA_ "GenMsgStartValue" BO_ 456 "00000000h";
BA_ "GenMsgStartDelayTime" BO_ 456 30;
BA_ "GenMsgSendType" BO_ 456 5;
BA_ "GenMsgNrOfRepetitions" BO_ 456 2;
BA_ "GenMsgDelayTime" BO_ 456 20;
BA_ "GenMsgCycleTime" BO_ 456 500;
BA_ "GenMsgStartValue" BO_ 462 "FF0000FFh";
BA_ "GenMsgNrOfRepetitions" BO_ 462 2;
BA_ "GenMsgDelayTime" BO_ 462 20;
BA_ "GenMsgCycleTime" BO_ 462 50;
BA_ "GenMsgStartValue" BO_ 463 "0000000000h";
BA_ "GenMsgSendType" BO_ 463 1;
BA_ "GenMsgNrOfRepetitions" BO_ 463 2;
BA_ "GenMsgDelayTime" BO_ 463 20;
BA_ "GenMsgStartValue" BO_ 464 "44E70F0F00070000h";
BA_ "GenMsgSendType" BO_ 464 5;
BA_ "GenMsgNrOfRepetitions" BO_ 464 2;
BA_ "GenMsgDelayTime" BO_ 464 20;
BA_ "GenMsgCycleTime" BO_ 464 1000;
BA_ "GenMsgStartValue" BO_ 466 "0000h";
BA_ "GenMsgSendType" BO_ 466 2;
BA_ "GenMsgNrOfRepetitions" BO_ 466 2;
BA_ "GenMsgDelayTime" BO_ 466 20;
BA_ "GenMsgCycleTimeActive" BO_ 466 20;
BA_ "GenMsgStartValue" BO_ 469 "0000000000000000h";
BA_ "GenMsgSendType" BO_ 469 5;
BA_ "GenMsgNrOfRepetitions" BO_ 469 2;
BA_ "GenMsgDelayTime" BO_ 469 20;
BA_ "GenMsgCycleTime" BO_ 469 250;
BA_ "GenMsgStartValue" BO_ 489 "FF001400000004FFh";
BA_ "GenMsgSendType" BO_ 489 5;
BA_ "GenMsgNrOfRepetitions" BO_ 489 2;
BA_ "GenMsgDelayTime" BO_ 489 20;
BA_ "GenMsgCycleTime" BO_ 489 500;
BA_ "GenMsgStartValue" BO_ 491 "0000000000000000h";
BA_ "GenMsgSendType" BO_ 491 5;
BA_ "GenMsgNrOfRepetitions" BO_ 491 2;
BA_ "GenMsgDelayTime" BO_ 491 20;
BA_ "GenMsgCycleTime" BO_ 491 500;
BA_ "GenMsgStartValue" BO_ 502 "00F0F0F0F0F0F000h";
BA_ "GenMsgSendType" BO_ 502 5;
BA_ "GenMsgNrOfRepetitions" BO_ 502 2;
BA_ "GenMsgDelayTime" BO_ 502 20;
BA_ "GenMsgCycleTime" BO_ 502 500;
BA_ "GenMsgStartValue" BO_ 503 "FFFF0FFF0000FFFFh";
BA_ "GenMsgNrOfRepetitions" BO_ 503 2;
BA_ "GenMsgDelayTime" BO_ 503 20;
BA_ "GenMsgCycleTime" BO_ 503 500;
BA_ "GenMsgStartValue" BO_ 505 "0000000000000000h";
BA_ "GenMsgNrOfRepetitions" BO_ 505 2;
BA_ "GenMsgDelayTime" BO_ 505 20;
BA_ "GenMsgCycleTime" BO_ 505 500;
BA_ "GenMsgStartValue" BO_ 515 "00000000000000h";
BA_ "GenMsgSendType" BO_ 515 1;
BA_ "GenMsgNrOfRepetitions" BO_ 515 2;
BA_ "GenMsgDelayTime" BO_ 515 20;
BA_ "GenMsgStartValue" BO_ 516 "00000000000000h";
BA_ "GenMsgSendType" BO_ 516 1;
BA_ "GenMsgNrOfRepetitions" BO_ 516 2;
BA_ "GenMsgDelayTime" BO_ 516 20;
BA_ "GenMsgStartValue" BO_ 517 "00000000000000h";
BA_ "GenMsgSendType" BO_ 517 1;
BA_ "GenMsgNrOfRepetitions" BO_ 517 2;
BA_ "GenMsgDelayTime" BO_ 517 20;
BA_ "GenMsgStartValue" BO_ 518 "00000000000000h";
BA_ "GenMsgSendType" BO_ 518 1;
BA_ "GenMsgNrOfRepetitions" BO_ 518 2;
BA_ "GenMsgDelayTime" BO_ 518 20;
BA_ "GenMsgStartValue" BO_ 523 "0000000000000000h";
BA_ "GenMsgSendType" BO_ 523 1;
BA_ "GenMsgNrOfRepetitions" BO_ 523 2;
BA_ "GenMsgDelayTime" BO_ 523 20;
BA_ "GenMsgStartValue" BO_ 524 "0000000000000000h";
BA_ "GenMsgSendType" BO_ 524 1;
BA_ "GenMsgNrOfRepetitions" BO_ 524 2;
BA_ "GenMsgDelayTime" BO_ 524 20;
BA_ "GenMsgStartValue" BO_ 525 "00h";
BA_ "GenMsgSendType" BO_ 525 1;
BA_ "GenMsgNrOfRepetitions" BO_ 525 2;
BA_ "GenMsgDelayTime" BO_ 525 20;
BA_ "GenMsgStartValue" BO_ 526 "000000800000h";
BA_ "GenMsgSendType" BO_ 526 1;
BA_ "GenMsgNrOfRepetitions" BO_ 526 2;
BA_ "GenMsgDelayTime" BO_ 526 20;
BA_ "GenMsgStartValue" BO_ 527 "0000000000000000h";
BA_ "GenMsgSendType" BO_ 527 1;
BA_ "GenMsgNrOfRepetitions" BO_ 527 2;
BA_ "GenMsgDelayTime" BO_ 527 20;
BA_ "GenMsgStartValue" BO_ 557 "FF0000000000FF00h";
BA_ "GenMsgStartDelayTime" BO_ 557 110;
BA_ "GenMsgSendType" BO_ 557 5;
BA_ "GenMsgNrOfRepetitions" BO_ 557 2;
BA_ "GenMsgDelayTime" BO_ 557 20;
BA_ "GenMsgCycleTime" BO_ 557 1000;
BA_ "GenMsgStartValue" BO_ 560 "0800000000000000h";
BA_ "GenMsgSendType" BO_ 560 5;
BA_ "GenMsgNrOfRepetitions" BO_ 560 2;
BA_ "GenMsgDelayTime" BO_ 560 20;
BA_ "GenMsgCycleTime" BO_ 560 500;
BA_ "GenMsgStartValue" BO_ 584 "0000FFFFFF03FFFFh";
BA_ "GenMsgStartDelayTime" BO_ 584 70;
BA_ "GenMsgSendType" BO_ 584 5;
BA_ "GenMsgNrOfRepetitions" BO_ 584 2;
BA_ "GenMsgDelayTime" BO_ 584 20;
BA_ "GenMsgCycleTime" BO_ 584 500;
BA_ "GenSigSNA" SG_ 315 MIL_OnRq_HCP "0h";
BA_ "GenSigCycleTime" SG_ 315 MIL_OnRq_HCP 100;
BA_ "FlexKomSigStartValue" SG_ 315 MIL_OnRq_HCP "00000000646400FFh";
BA_ "FlexKomSigStartPos" SG_ 315 MIL_OnRq_HCP 7;
BA_ "FlexKomSigName" SG_ 315 MIL_OnRq_HCP "HCP_C1_Pkt";
BA_ "FlexKomSigLaenge" SG_ 315 MIL_OnRq_HCP 64;
BA_ "FlexKomSID" SG_ 315 MIL_OnRq_HCP 2374;
BA_ "FlexKomIsMotorola" SG_ 315 MIL_OnRq_HCP 1;
BA_ "FlexKomComment" SG_ 315 MIL_OnRq_HCP "HCP_C1_Pkt message packet";
BA_ "GenSigSNA" SG_ 315 HybSysEmsMlfAtv "0h";
BA_ "GenSigCycleTime" SG_ 315 HybSysEmsMlfAtv 100;
BA_ "FlexKomSigStartValue" SG_ 315 HybSysEmsMlfAtv "00000000646400FFh";
BA_ "FlexKomSigStartPos" SG_ 315 HybSysEmsMlfAtv 7;
BA_ "FlexKomSigName" SG_ 315 HybSysEmsMlfAtv "HCP_C1_Pkt";
BA_ "FlexKomSigLaenge" SG_ 315 HybSysEmsMlfAtv 64;
BA_ "FlexKomSID" SG_ 315 HybSysEmsMlfAtv 2374;
BA_ "FlexKomIsMotorola" SG_ 315 HybSysEmsMlfAtv 1;
BA_ "FlexKomComment" SG_ 315 HybSysEmsMlfAtv "HCP_C1_Pkt message packet";
BA_ "GenSigTimeout_IC" SG_ 315 HCPPopUpMessage1 1050;
BA_ "GenSigSNA" SG_ 315 HCPPopUpMessage1 "0h";
BA_ "GenSigCycleTime" SG_ 315 HCPPopUpMessage1 100;
BA_ "FlexKomSigStartValue" SG_ 315 HCPPopUpMessage1 "00000000646400FFh";
BA_ "FlexKomSigStartPos" SG_ 315 HCPPopUpMessage1 7;
BA_ "FlexKomSigName" SG_ 315 HCPPopUpMessage1 "HCP_C1_Pkt";
BA_ "FlexKomSigLaenge" SG_ 315 HCPPopUpMessage1 64;
BA_ "FlexKomSID" SG_ 315 HCPPopUpMessage1 2374;
BA_ "FlexKomIsMotorola" SG_ 315 HCPPopUpMessage1 1;
BA_ "FlexKomComment" SG_ 315 HCPPopUpMessage1 "HCP_C1_Pkt message packet";
BA_ "GenSigTimeout_IC" SG_ 315 HCPPopUpMessage2 1050;
BA_ "GenSigSNA" SG_ 315 HCPPopUpMessage2 "0h";
BA_ "GenSigCycleTime" SG_ 315 HCPPopUpMessage2 100;
BA_ "FlexKomSigStartValue" SG_ 315 HCPPopUpMessage2 "00000000646400FFh";
BA_ "FlexKomSigStartPos" SG_ 315 HCPPopUpMessage2 7;
BA_ "FlexKomSigName" SG_ 315 HCPPopUpMessage2 "HCP_C1_Pkt";
BA_ "FlexKomSigLaenge" SG_ 315 HCPPopUpMessage2 64;
BA_ "FlexKomSID" SG_ 315 HCPPopUpMessage2 2374;
BA_ "FlexKomIsMotorola" SG_ 315 HCPPopUpMessage2 1;
BA_ "FlexKomComment" SG_ 315 HCPPopUpMessage2 "HCP_C1_Pkt message packet";
BA_ "GenSigTimeout_IC" SG_ 315 HCPPopUpMessage3 1050;
BA_ "GenSigSNA" SG_ 315 HCPPopUpMessage3 "0h";
BA_ "GenSigCycleTime" SG_ 315 HCPPopUpMessage3 100;
BA_ "FlexKomSigStartValue" SG_ 315 HCPPopUpMessage3 "00000000646400FFh";
BA_ "FlexKomSigStartPos" SG_ 315 HCPPopUpMessage3 7;
BA_ "FlexKomSigName" SG_ 315 HCPPopUpMessage3 "HCP_C1_Pkt";
BA_ "FlexKomSigLaenge" SG_ 315 HCPPopUpMessage3 64;
BA_ "FlexKomSID" SG_ 315 HCPPopUpMessage3 2374;
BA_ "FlexKomIsMotorola" SG_ 315 HCPPopUpMessage3 1;
BA_ "FlexKomComment" SG_ 315 HCPPopUpMessage3 "HCP_C1_Pkt message packet";
BA_ "GenSigTimeout_IC" SG_ 315 HCPPopUpMessage4 1050;
BA_ "GenSigSNA" SG_ 315 HCPPopUpMessage4 "0h";
BA_ "GenSigCycleTime" SG_ 315 HCPPopUpMessage4 100;
BA_ "FlexKomSigStartValue" SG_ 315 HCPPopUpMessage4 "00000000646400FFh";
BA_ "FlexKomSigStartPos" SG_ 315 HCPPopUpMessage4 7;
BA_ "FlexKomSigName" SG_ 315 HCPPopUpMessage4 "HCP_C1_Pkt";
BA_ "FlexKomSigLaenge" SG_ 315 HCPPopUpMessage4 64;
BA_ "FlexKomSID" SG_ 315 HCPPopUpMessage4 2374;
BA_ "FlexKomIsMotorola" SG_ 315 HCPPopUpMessage4 1;
BA_ "FlexKomComment" SG_ 315 HCPPopUpMessage4 "HCP_C1_Pkt message packet";
BA_ "GenSigTimeout_IC" SG_ 315 HCPPopUpMessage5 1050;
BA_ "GenSigSNA" SG_ 315 HCPPopUpMessage5 "0h";
BA_ "GenSigCycleTime" SG_ 315 HCPPopUpMessage5 100;
BA_ "FlexKomSigStartValue" SG_ 315 HCPPopUpMessage5 "00000000646400FFh";
BA_ "FlexKomSigStartPos" SG_ 315 HCPPopUpMessage5 7;
BA_ "FlexKomSigName" SG_ 315 HCPPopUpMessage5 "HCP_C1_Pkt";
BA_ "FlexKomSigLaenge" SG_ 315 HCPPopUpMessage5 64;
BA_ "FlexKomSID" SG_ 315 HCPPopUpMessage5 2374;
BA_ "FlexKomIsMotorola" SG_ 315 HCPPopUpMessage5 1;
BA_ "FlexKomComment" SG_ 315 HCPPopUpMessage5 "HCP_C1_Pkt message packet";
BA_ "GenSigTimeout_IC" SG_ 315 HCPPopUpMessage6 1050;
BA_ "GenSigSNA" SG_ 315 HCPPopUpMessage6 "0h";
BA_ "GenSigCycleTime" SG_ 315 HCPPopUpMessage6 100;
BA_ "FlexKomSigStartValue" SG_ 315 HCPPopUpMessage6 "00000000646400FFh";
BA_ "FlexKomSigStartPos" SG_ 315 HCPPopUpMessage6 7;
BA_ "FlexKomSigName" SG_ 315 HCPPopUpMessage6 "HCP_C1_Pkt";
BA_ "FlexKomSigLaenge" SG_ 315 HCPPopUpMessage6 64;
BA_ "FlexKomSID" SG_ 315 HCPPopUpMessage6 2374;
BA_ "FlexKomIsMotorola" SG_ 315 HCPPopUpMessage6 1;
BA_ "FlexKomComment" SG_ 315 HCPPopUpMessage6 "HCP_C1_Pkt message packet";
BA_ "GenSigTimeout_IC" SG_ 315 HCPPopUpMessage7 1050;
BA_ "GenSigSNA" SG_ 315 HCPPopUpMessage7 "0h";
BA_ "GenSigCycleTime" SG_ 315 HCPPopUpMessage7 100;
BA_ "FlexKomSigStartValue" SG_ 315 HCPPopUpMessage7 "00000000646400FFh";
BA_ "FlexKomSigStartPos" SG_ 315 HCPPopUpMessage7 7;
BA_ "FlexKomSigName" SG_ 315 HCPPopUpMessage7 "HCP_C1_Pkt";
BA_ "FlexKomSigLaenge" SG_ 315 HCPPopUpMessage7 64;
BA_ "FlexKomSID" SG_ 315 HCPPopUpMessage7 2374;
BA_ "FlexKomIsMotorola" SG_ 315 HCPPopUpMessage7 1;
BA_ "FlexKomComment" SG_ 315 HCPPopUpMessage7 "HCP_C1_Pkt message packet";
BA_ "GenSigTimeout_IC" SG_ 315 HCPOutputPwrV 1050;
BA_ "GenSigSNA" SG_ 315 HCPOutputPwrV "0h";
BA_ "GenSigCycleTime" SG_ 315 HCPOutputPwrV 100;
BA_ "FlexKomSigStartValue" SG_ 315 HCPOutputPwrV "00000000646400FFh";
BA_ "FlexKomSigStartPos" SG_ 315 HCPOutputPwrV 7;
BA_ "FlexKomSigName" SG_ 315 HCPOutputPwrV "HCP_C1_Pkt";
BA_ "FlexKomSigLaenge" SG_ 315 HCPOutputPwrV 64;
BA_ "FlexKomSID" SG_ 315 HCPOutputPwrV 2374;
BA_ "FlexKomIsMotorola" SG_ 315 HCPOutputPwrV 1;
BA_ "FlexKomComment" SG_ 315 HCPOutputPwrV "HCP_C1_Pkt message packet";
BA_ "GenSigTimeout_IC" SG_ 315 HCPCoachDispV 1050;
BA_ "GenSigSNA" SG_ 315 HCPCoachDispV "0h";
BA_ "GenSigCycleTime" SG_ 315 HCPCoachDispV 100;
BA_ "FlexKomSigStartValue" SG_ 315 HCPCoachDispV "00000000646400FFh";
BA_ "FlexKomSigStartPos" SG_ 315 HCPCoachDispV 7;
BA_ "FlexKomSigName" SG_ 315 HCPCoachDispV "HCP_C1_Pkt";
BA_ "FlexKomSigLaenge" SG_ 315 HCPCoachDispV 64;
BA_ "FlexKomSID" SG_ 315 HCPCoachDispV 2374;
BA_ "FlexKomIsMotorola" SG_ 315 HCPCoachDispV 1;
BA_ "FlexKomComment" SG_ 315 HCPCoachDispV "HCP_C1_Pkt message packet";
BA_ "GenSigTimeout_IC" SG_ 315 HCPOutputPwr 1050;
BA_ "GenSigStartValue" SG_ 315 HCPOutputPwr 100;
BA_ "GenSigSNA" SG_ 315 HCPOutputPwr "64h";
BA_ "GenSigCycleTime" SG_ 315 HCPOutputPwr 100;
BA_ "FlexKomSigStartValue" SG_ 315 HCPOutputPwr "00000000646400FFh";
BA_ "FlexKomSigStartPos" SG_ 315 HCPOutputPwr 7;
BA_ "FlexKomSigName" SG_ 315 HCPOutputPwr "HCP_C1_Pkt";
BA_ "FlexKomSigLaenge" SG_ 315 HCPOutputPwr 64;
BA_ "FlexKomSID" SG_ 315 HCPOutputPwr 2374;
BA_ "FlexKomIsMotorola" SG_ 315 HCPOutputPwr 1;
BA_ "FlexKomComment" SG_ 315 HCPOutputPwr "HCP_C1_Pkt message packet";
BA_ "GenSigTimeout_IC" SG_ 315 HCPCoachDisp 1050;
BA_ "GenSigStartValue" SG_ 315 HCPCoachDisp 100;
BA_ "GenSigSNA" SG_ 315 HCPCoachDisp "64h";
BA_ "GenSigCycleTime" SG_ 315 HCPCoachDisp 100;
BA_ "FlexKomSigStartValue" SG_ 315 HCPCoachDisp "00000000646400FFh";
BA_ "FlexKomSigStartPos" SG_ 315 HCPCoachDisp 7;
BA_ "FlexKomSigName" SG_ 315 HCPCoachDisp "HCP_C1_Pkt";
BA_ "FlexKomSigLaenge" SG_ 315 HCPCoachDisp 64;
BA_ "FlexKomSID" SG_ 315 HCPCoachDisp 2374;
BA_ "FlexKomIsMotorola" SG_ 315 HCPCoachDisp 1;
BA_ "FlexKomComment" SG_ 315 HCPCoachDisp "HCP_C1_Pkt message packet";
BA_ "GenSigTimeout_IC" SG_ 315 HCPPopUpMessage8 1050;
BA_ "GenSigSNA" SG_ 315 HCPPopUpMessage8 "0h";
BA_ "GenSigCycleTime" SG_ 315 HCPPopUpMessage8 100;
BA_ "FlexKomSigStartValue" SG_ 315 HCPPopUpMessage8 "00000000646400FFh";
BA_ "FlexKomSigStartPos" SG_ 315 HCPPopUpMessage8 7;
BA_ "FlexKomSigName" SG_ 315 HCPPopUpMessage8 "HCP_C1_Pkt";
BA_ "FlexKomSigLaenge" SG_ 315 HCPPopUpMessage8 64;
BA_ "FlexKomSID" SG_ 315 HCPPopUpMessage8 2374;
BA_ "FlexKomIsMotorola" SG_ 315 HCPPopUpMessage8 1;
BA_ "FlexKomComment" SG_ 315 HCPPopUpMessage8 "HCP_C1_Pkt message packet";
BA_ "GenSigTimeout_IC" SG_ 315 HCPPopUpMessage9 1050;
BA_ "GenSigSNA" SG_ 315 HCPPopUpMessage9 "0h";
BA_ "GenSigCycleTime" SG_ 315 HCPPopUpMessage9 100;
BA_ "FlexKomSigStartValue" SG_ 315 HCPPopUpMessage9 "00000000646400FFh";
BA_ "FlexKomSigStartPos" SG_ 315 HCPPopUpMessage9 7;
BA_ "FlexKomSigName" SG_ 315 HCPPopUpMessage9 "HCP_C1_Pkt";
BA_ "FlexKomSigLaenge" SG_ 315 HCPPopUpMessage9 64;
BA_ "FlexKomSID" SG_ 315 HCPPopUpMessage9 2374;
BA_ "FlexKomIsMotorola" SG_ 315 HCPPopUpMessage9 1;
BA_ "FlexKomComment" SG_ 315 HCPPopUpMessage9 "HCP_C1_Pkt message packet";
BA_ "GenSigTimeout_IC" SG_ 315 HCPPopUpMessage10 1050;
BA_ "GenSigSNA" SG_ 315 HCPPopUpMessage10 "0h";
BA_ "GenSigCycleTime" SG_ 315 HCPPopUpMessage10 100;
BA_ "FlexKomSigStartValue" SG_ 315 HCPPopUpMessage10 "00000000646400FFh";
BA_ "FlexKomSigStartPos" SG_ 315 HCPPopUpMessage10 7;
BA_ "FlexKomSigName" SG_ 315 HCPPopUpMessage10 "HCP_C1_Pkt";
BA_ "FlexKomSigLaenge" SG_ 315 HCPPopUpMessage10 64;
BA_ "FlexKomSID" SG_ 315 HCPPopUpMessage10 2374;
BA_ "FlexKomIsMotorola" SG_ 315 HCPPopUpMessage10 1;
BA_ "FlexKomComment" SG_ 315 HCPPopUpMessage10 "HCP_C1_Pkt message packet";
BA_ "GenSigTimeout_IC" SG_ 315 DriveMdstat 1050;
BA_ "GenSigTimeout_CBC" SG_ 315 DriveMdstat 1050;
BA_ "GenSigSNA" SG_ 315 DriveMdstat "Fh";
BA_ "GenSigCycleTime" SG_ 315 DriveMdstat 100;
BA_ "FlexKomSigStartValue" SG_ 315 DriveMdstat "00000000646400FFh";
BA_ "FlexKomSigStartPos" SG_ 315 DriveMdstat 7;
BA_ "FlexKomSigName" SG_ 315 DriveMdstat "HCP_C1_Pkt";
BA_ "FlexKomSigLaenge" SG_ 315 DriveMdstat 64;
BA_ "FlexKomSID" SG_ 315 DriveMdstat 2374;
BA_ "FlexKomIsMotorola" SG_ 315 DriveMdstat 1;
BA_ "FlexKomComment" SG_ 315 DriveMdstat "HCP_C1_Pkt message packet";
BA_ "GenSigTimeout_IC" SG_ 315 DrvMode_PopUpRqst 1050;
BA_ "GenSigTimeout_CBC" SG_ 315 DrvMode_PopUpRqst 1050;
BA_ "GenSigSNA" SG_ 315 DrvMode_PopUpRqst "Fh";
BA_ "GenSigCycleTime" SG_ 315 DrvMode_PopUpRqst 100;
BA_ "FlexKomSigStartValue" SG_ 315 DrvMode_PopUpRqst "00000000646400FFh";
BA_ "FlexKomSigStartPos" SG_ 315 DrvMode_PopUpRqst 7;
BA_ "FlexKomSigName" SG_ 315 DrvMode_PopUpRqst "HCP_C1_Pkt";
BA_ "FlexKomSigLaenge" SG_ 315 DrvMode_PopUpRqst 64;
BA_ "FlexKomSID" SG_ 315 DrvMode_PopUpRqst 2374;
BA_ "FlexKomIsMotorola" SG_ 315 DrvMode_PopUpRqst 1;
BA_ "FlexKomComment" SG_ 315 DrvMode_PopUpRqst "HCP_C1_Pkt message packet";
BA_ "GenSigSNA" SG_ 315 GrShiftIndication "3h";
BA_ "GenSigCycleTime" SG_ 315 GrShiftIndication 100;
BA_ "FlexKomSigStartValue" SG_ 315 GrShiftIndication "00000000646400FFh";
BA_ "FlexKomSigStartPos" SG_ 315 GrShiftIndication 7;
BA_ "FlexKomSigName" SG_ 315 GrShiftIndication "HCP_C1_Pkt";
BA_ "FlexKomSigLaenge" SG_ 315 GrShiftIndication 64;
BA_ "FlexKomSID" SG_ 315 GrShiftIndication 2374;
BA_ "FlexKomIsMotorola" SG_ 315 GrShiftIndication 1;
BA_ "FlexKomComment" SG_ 315 GrShiftIndication "HCP_C1_Pkt message packet";
BA_ "GenSigTimeout_IC" SG_ 315 HCPPopUpMessage12 1050;
BA_ "GenSigSNA" SG_ 315 HCPPopUpMessage12 "0h";
BA_ "GenSigCycleTime" SG_ 315 HCPPopUpMessage12 100;
BA_ "FlexKomSigStartValue" SG_ 315 HCPPopUpMessage12 "00000000646400FFh";
BA_ "FlexKomSigStartPos" SG_ 315 HCPPopUpMessage12 7;
BA_ "FlexKomSigName" SG_ 315 HCPPopUpMessage12 "HCP_C1_Pkt";
BA_ "FlexKomSigLaenge" SG_ 315 HCPPopUpMessage12 64;
BA_ "FlexKomSID" SG_ 315 HCPPopUpMessage12 2374;
BA_ "FlexKomIsMotorola" SG_ 315 HCPPopUpMessage12 1;
BA_ "FlexKomComment" SG_ 315 HCPPopUpMessage12 "HCP_C1_Pkt message packet";
BA_ "GenSigSNA" SG_ 315 MaxRegenTelltale "0h";
BA_ "GenSigCycleTime" SG_ 315 MaxRegenTelltale 100;
BA_ "FlexKomSigStartValue" SG_ 315 MaxRegenTelltale "00000000646400FFh";
BA_ "FlexKomSigStartPos" SG_ 315 MaxRegenTelltale 7;
BA_ "FlexKomSigName" SG_ 315 MaxRegenTelltale "HCP_C1_Pkt";
BA_ "FlexKomSigLaenge" SG_ 315 MaxRegenTelltale 64;
BA_ "FlexKomSID" SG_ 315 MaxRegenTelltale 2374;
BA_ "FlexKomIsMotorola" SG_ 315 MaxRegenTelltale 1;
BA_ "FlexKomComment" SG_ 315 MaxRegenTelltale "HCP_C1_Pkt message packet";
BA_ "GenSigSNA" SG_ 315 MC_HCP_C1 "0h";
BA_ "GenSigCycleTime" SG_ 315 MC_HCP_C1 100;
BA_ "FlexKomSigStartValue" SG_ 315 MC_HCP_C1 "00000000646400FFh";
BA_ "FlexKomSigStartPos" SG_ 315 MC_HCP_C1 7;
BA_ "FlexKomSigName" SG_ 315 MC_HCP_C1 "HCP_C1_Pkt";
BA_ "FlexKomSigLaenge" SG_ 315 MC_HCP_C1 64;
BA_ "FlexKomSID" SG_ 315 MC_HCP_C1 2374;
BA_ "FlexKomIsMotorola" SG_ 315 MC_HCP_C1 1;
BA_ "FlexKomComment" SG_ 315 MC_HCP_C1 "HCP_C1_Pkt message packet";
BA_ "GenSigStartValue" SG_ 315 CRC_HCP_C1 255;
BA_ "GenSigSNA" SG_ 315 CRC_HCP_C1 "FFh";
BA_ "GenSigCycleTime" SG_ 315 CRC_HCP_C1 100;
BA_ "FlexKomSigStartValue" SG_ 315 CRC_HCP_C1 "00000000646400FFh";
BA_ "FlexKomSigStartPos" SG_ 315 CRC_HCP_C1 7;
BA_ "FlexKomSigName" SG_ 315 CRC_HCP_C1 "HCP_C1_Pkt";
BA_ "FlexKomSigLaenge" SG_ 315 CRC_HCP_C1 64;
BA_ "FlexKomSID" SG_ 315 CRC_HCP_C1 2374;
BA_ "FlexKomIsMotorola" SG_ 315 CRC_HCP_C1 1;
BA_ "FlexKomComment" SG_ 315 CRC_HCP_C1 "HCP_C1_Pkt message packet";
BA_ "GenSigSNA" SG_ 315 ThermalRunaway_LampReq "0h";
BA_ "GenSigCycleTime" SG_ 315 ThermalRunaway_LampReq 100;
BA_ "FlexKomSigStartValue" SG_ 315 ThermalRunaway_LampReq "00000000646400FFh";
BA_ "FlexKomSigStartPos" SG_ 315 ThermalRunaway_LampReq 7;
BA_ "FlexKomSigName" SG_ 315 ThermalRunaway_LampReq "HCP_C1_Pkt";
BA_ "FlexKomSigLaenge" SG_ 315 ThermalRunaway_LampReq 64;
BA_ "FlexKomSID" SG_ 315 ThermalRunaway_LampReq 2374;
BA_ "FlexKomIsMotorola" SG_ 315 ThermalRunaway_LampReq 1;
BA_ "FlexKomComment" SG_ 315 ThermalRunaway_LampReq "HCP_C1_Pkt message packet";
BA_ "RID" SG_ 317 MIL_OnRq "1210 6543";
BA_ "GenSigTimeout_ORC" SG_ 317 MIL_OnRq 350;
BA_ "GenSigTimeout_IC" SG_ 317 MIL_OnRq 1050;
BA_ "GenSigSNA" SG_ 317 MIL_OnRq "0h";
BA_ "GenSigCycleTime" SG_ 317 MIL_OnRq 100;
BA_ "FlexKomSigStartValue" SG_ 317 MIL_OnRq "00h";
BA_ "FlexKomSigName" SG_ 317 MIL_OnRq "MIL_OnRq";
BA_ "FlexKomSigLaenge" SG_ 317 MIL_OnRq 1;
BA_ "FlexKomSID" SG_ 317 MIL_OnRq 714;
BA_ "FlexKomIsMotorola" SG_ 317 MIL_OnRq 1;
BA_ "FlexKomComment" SG_ 317 MIL_OnRq "MIL on request from the engine";
BA_ "GenSigTimeout_ORC" SG_ 317 MIL_IND_BLINK 350;
BA_ "GenSigTimeout_IC" SG_ 317 MIL_IND_BLINK 1050;
BA_ "GenSigSNA" SG_ 317 MIL_IND_BLINK "0h";
BA_ "GenSigCycleTime" SG_ 317 MIL_IND_BLINK 100;
BA_ "FlexKomSigStartValue" SG_ 317 MIL_IND_BLINK "00h";
BA_ "FlexKomSigStartPos" SG_ 317 MIL_IND_BLINK 1;
BA_ "FlexKomSigName" SG_ 317 MIL_IND_BLINK "MIL_IND_BLINK";
BA_ "FlexKomSigLaenge" SG_ 317 MIL_IND_BLINK 1;
BA_ "FlexKomSID" SG_ 317 MIL_IND_BLINK 713;
BA_ "FlexKomIsMotorola" SG_ 317 MIL_IND_BLINK 1;
BA_ "FlexKomComment" SG_ 317 MIL_IND_BLINK "Request MIL blink (OBD II)";
BA_ "RID" SG_ 317 ETC_IND_LMP "6544";
BA_ "GenSigTimeout_TBM" SG_ 317 ETC_IND_LMP 1050;
BA_ "GenSigTimeout_IC" SG_ 317 ETC_IND_LMP 1050;
BA_ "GenSigTimeout_ETM" SG_ 317 ETC_IND_LMP 1050;
BA_ "GenSigSNA" SG_ 317 ETC_IND_LMP "3h";
BA_ "GenSigCycleTime" SG_ 317 ETC_IND_LMP 100;
BA_ "FlexKomSigStartValue" SG_ 317 ETC_IND_LMP "00h";
BA_ "FlexKomSigStartPos" SG_ 317 ETC_IND_LMP 3;
BA_ "FlexKomSigName" SG_ 317 ETC_IND_LMP "ETC_IND_LMP";
BA_ "FlexKomSigLaenge" SG_ 317 ETC_IND_LMP 2;
BA_ "FlexKomSID" SG_ 317 ETC_IND_LMP 712;
BA_ "FlexKomIsMotorola" SG_ 317 ETC_IND_LMP 1;
BA_ "FlexKomComment" SG_ 317 ETC_IND_LMP "ETC faulty, indicator lamp request";
BA_ "GenSigTimeout_IC" SG_ 317 OIL_IND_LMP_FLSH 1050;
BA_ "GenSigSNA" SG_ 317 OIL_IND_LMP_FLSH "0h";
BA_ "GenSigCycleTime" SG_ 317 OIL_IND_LMP_FLSH 100;
BA_ "FlexKomSigStartValue" SG_ 317 OIL_IND_LMP_FLSH "00h";
BA_ "FlexKomSigStartPos" SG_ 317 OIL_IND_LMP_FLSH 8;
BA_ "FlexKomSigName" SG_ 317 OIL_IND_LMP_FLSH "OIL_IND_LMP_FLSH";
BA_ "FlexKomSigLaenge" SG_ 317 OIL_IND_LMP_FLSH 1;
BA_ "FlexKomSID" SG_ 317 OIL_IND_LMP_FLSH 716;
BA_ "FlexKomIsMotorola" SG_ 317 OIL_IND_LMP_FLSH 1;
BA_ "FlexKomComment" SG_ 317 OIL_IND_LMP_FLSH "Oil indicator lamp flash (for in plant use)";
BA_ "RID" SG_ 317 EngOilIndLmp_On_Rq "6552";
BA_ "GenSigTimeout_TBM" SG_ 317 EngOilIndLmp_On_Rq 1050;
BA_ "GenSigTimeout_IC" SG_ 317 EngOilIndLmp_On_Rq 1050;
BA_ "GenSigTimeout_ETM" SG_ 317 EngOilIndLmp_On_Rq 1050;
BA_ "GenSigSNA" SG_ 317 EngOilIndLmp_On_Rq "1h";
BA_ "GenSigCycleTime" SG_ 317 EngOilIndLmp_On_Rq 100;
BA_ "FlexKomSigStartValue" SG_ 317 EngOilIndLmp_On_Rq "00h";
BA_ "FlexKomSigStartPos" SG_ 317 EngOilIndLmp_On_Rq 10;
BA_ "FlexKomSigName" SG_ 317 EngOilIndLmp_On_Rq "EngOilIndLmp_On_Rq";
BA_ "FlexKomSigLaenge" SG_ 317 EngOilIndLmp_On_Rq 1;
BA_ "FlexKomSID" SG_ 317 EngOilIndLmp_On_Rq 1080;
BA_ "FlexKomIsMotorola" SG_ 317 EngOilIndLmp_On_Rq 1;
BA_ "FlexKomComment" SG_ 317 EngOilIndLmp_On_Rq "Request oil level/oil pressure indicator lamp";
BA_ "RID" SG_ 317 OIL_TEMP_IND_RQ "6551";
BA_ "GenSigTimeout_TBM" SG_ 317 OIL_TEMP_IND_RQ 1050;
BA_ "GenSigTimeout_IC" SG_ 317 OIL_TEMP_IND_RQ 1050;
BA_ "GenSigTimeout_ETM" SG_ 317 OIL_TEMP_IND_RQ 1050;
BA_ "GenSigSNA" SG_ 317 OIL_TEMP_IND_RQ "3h";
BA_ "GenSigCycleTime" SG_ 317 OIL_TEMP_IND_RQ 100;
BA_ "FlexKomSigStartValue" SG_ 317 OIL_TEMP_IND_RQ "00h";
BA_ "FlexKomSigStartPos" SG_ 317 OIL_TEMP_IND_RQ 14;
BA_ "FlexKomSigName" SG_ 317 OIL_TEMP_IND_RQ "OIL_TEMP_RQ";
BA_ "FlexKomSigLaenge" SG_ 317 OIL_TEMP_IND_RQ 4;
BA_ "FlexKomSID" SG_ 317 OIL_TEMP_IND_RQ 718;
BA_ "FlexKomIsMotorola" SG_ 317 OIL_TEMP_IND_RQ 1;
BA_ "FlexKomComment" SG_ 317 OIL_TEMP_IND_RQ "Engine oil overtemp. indicator/chime request";
BA_ "GenSigTimeout_IC" SG_ 317 OIL_TEMP_CHM_RQ 1050;
BA_ "GenSigSNA" SG_ 317 OIL_TEMP_CHM_RQ "0h";
BA_ "GenSigCycleTime" SG_ 317 OIL_TEMP_CHM_RQ 100;
BA_ "FlexKomSigStartValue" SG_ 317 OIL_TEMP_CHM_RQ "00h";
BA_ "FlexKomSigStartPos" SG_ 317 OIL_TEMP_CHM_RQ 14;
BA_ "FlexKomSigName" SG_ 317 OIL_TEMP_CHM_RQ "OIL_TEMP_RQ";
BA_ "FlexKomSigLaenge" SG_ 317 OIL_TEMP_CHM_RQ 4;
BA_ "FlexKomSID" SG_ 317 OIL_TEMP_CHM_RQ 718;
BA_ "FlexKomIsMotorola" SG_ 317 OIL_TEMP_CHM_RQ 1;
BA_ "FlexKomComment" SG_ 317 OIL_TEMP_CHM_RQ "Engine oil overtemp. indicator/chime request";
BA_ "RID" SG_ 317 ChkFuelCap "6545";
BA_ "GenSigTimeout_TBM" SG_ 317 ChkFuelCap 1050;
BA_ "GenSigTimeout_IC" SG_ 317 ChkFuelCap 1050;
BA_ "GenSigTimeout_ETM" SG_ 317 ChkFuelCap 1050;
BA_ "GenSigSNA" SG_ 317 ChkFuelCap "0h";
BA_ "GenSigCycleTime" SG_ 317 ChkFuelCap 100;
BA_ "FlexKomSigStartValue" SG_ 317 ChkFuelCap "00h";
BA_ "FlexKomSigStartPos" SG_ 317 ChkFuelCap 15;
BA_ "FlexKomSigName" SG_ 317 ChkFuelCap "ChkFuelCap";
BA_ "FlexKomSigLaenge" SG_ 317 ChkFuelCap 1;
BA_ "FlexKomSID" SG_ 317 ChkFuelCap 1082;
BA_ "FlexKomIsMotorola" SG_ 317 ChkFuelCap 1;
BA_ "FlexKomComment" SG_ 317 ChkFuelCap "Check fuel cap";
BA_ "RID" SG_ 317 OIL_PRESS "1183";
BA_ "GenSigTimeout_TBM" SG_ 317 OIL_PRESS 1050;
BA_ "GenSigTimeout_IC" SG_ 317 OIL_PRESS 1050;
BA_ "GenSigTimeout_CBC" SG_ 317 OIL_PRESS 1050;
BA_ "GenSigStartValue" SG_ 317 OIL_PRESS 255;
BA_ "GenSigSNA" SG_ 317 OIL_PRESS "FFh";
BA_ "GenSigCycleTime" SG_ 317 OIL_PRESS 100;
BA_ "FlexKomSigStartValue" SG_ 317 OIL_PRESS "FFh";
BA_ "FlexKomSigStartPos" SG_ 317 OIL_PRESS 23;
BA_ "FlexKomSigName" SG_ 317 OIL_PRESS "OIL_PRESS";
BA_ "FlexKomSigLaenge" SG_ 317 OIL_PRESS 8;
BA_ "FlexKomSID" SG_ 317 OIL_PRESS 717;
BA_ "FlexKomIsMotorola" SG_ 317 OIL_PRESS 1;
BA_ "FlexKomComment" SG_ 317 OIL_PRESS "Oil pressure";
BA_ "RID" SG_ 317 EngOilTemp "1200";
BA_ "GenSigTimeout_TBM" SG_ 317 EngOilTemp 1050;
BA_ "GenSigTimeout_IC" SG_ 317 EngOilTemp 1050;
BA_ "GenSigTimeout_CBC" SG_ 317 EngOilTemp 1050;
BA_ "GenSigStartValue" SG_ 317 EngOilTemp 255;
BA_ "GenSigSNA" SG_ 317 EngOilTemp "FFh";
BA_ "GenSigCycleTime" SG_ 317 EngOilTemp 100;
BA_ "FlexKomSigStartValue" SG_ 317 EngOilTemp "FFh";
BA_ "FlexKomSigStartPos" SG_ 317 EngOilTemp 31;
BA_ "FlexKomSigName" SG_ 317 EngOilTemp "EngOilTemp";
BA_ "FlexKomSigLaenge" SG_ 317 EngOilTemp 8;
BA_ "FlexKomSID" SG_ 317 EngOilTemp 440;
BA_ "FlexKomIsMotorola" SG_ 317 EngOilTemp 1;
BA_ "FlexKomComment" SG_ 317 EngOilTemp "Oil temperature";
BA_ "RID" SG_ 317 FuelCons "1818";
BA_ "GenSigTimeout_IC" SG_ 317 FuelCons 1050;
BA_ "GenSigTimeout_CBC" SG_ 317 FuelCons 1050;
BA_ "GenSigStartValue" SG_ 317 FuelCons 65535;
BA_ "GenSigSNA" SG_ 317 FuelCons "FFFFh";
BA_ "GenSigCycleTime" SG_ 317 FuelCons 100;
BA_ "FlexKomSigStartValue" SG_ 317 FuelCons "FFFFh";
BA_ "FlexKomSigStartPos" SG_ 317 FuelCons 39;
BA_ "FlexKomSigName" SG_ 317 FuelCons "FuelCons";
BA_ "FlexKomSigLaenge" SG_ 317 FuelCons 16;
BA_ "FlexKomSID" SG_ 317 FuelCons 443;
BA_ "FlexKomIsMotorola" SG_ 317 FuelCons 1;
BA_ "FlexKomComment" SG_ 317 FuelCons "Fuel consumption";
BA_ "GenSigTimeout_IC" SG_ 317 DefFuelEcon 1050;
BA_ "GenSigStartValue" SG_ 317 DefFuelEcon 255;
BA_ "GenSigSNA" SG_ 317 DefFuelEcon "FFh";
BA_ "GenSigCycleTime" SG_ 317 DefFuelEcon 100;
BA_ "FlexKomSigStartValue" SG_ 317 DefFuelEcon "FFh";
BA_ "FlexKomSigStartPos" SG_ 317 DefFuelEcon 55;
BA_ "FlexKomSigName" SG_ 317 DefFuelEcon "DefFuelEcon";
BA_ "FlexKomSigLaenge" SG_ 317 DefFuelEcon 8;
BA_ "FlexKomSID" SG_ 317 DefFuelEcon 709;
BA_ "FlexKomIsMotorola" SG_ 317 DefFuelEcon 1;
BA_ "FlexKomComment" SG_ 317 DefFuelEcon "Default fuel economy";
BA_ "RID" SG_ 317 EngRun_Stat "2093";
BA_ "GenSigTimeout_IC" SG_ 317 EngRun_Stat 1050;
BA_ "GenSigTimeout_DTCM" SG_ 317 EngRun_Stat 1050;
BA_ "GenSigTimeout_CBC" SG_ 317 EngRun_Stat 1050;
BA_ "GenSigStartValue" SG_ 317 EngRun_Stat 7;
BA_ "GenSigSNA" SG_ 317 EngRun_Stat "7h";
BA_ "GenSigCycleTime" SG_ 317 EngRun_Stat 100;
BA_ "FlexKomSigStartValue" SG_ 317 EngRun_Stat "07h";
BA_ "FlexKomSigStartPos" SG_ 317 EngRun_Stat 58;
BA_ "FlexKomSigName" SG_ 317 EngRun_Stat "EngRun_Stat";
BA_ "FlexKomSigLaenge" SG_ 317 EngRun_Stat 3;
BA_ "FlexKomSID" SG_ 317 EngRun_Stat 1081;
BA_ "FlexKomIsMotorola" SG_ 317 EngRun_Stat 1;
BA_ "FlexKomComment" SG_ 317 EngRun_Stat "Engine running state";
BA_ "GenSigTimeout_IC" SG_ 319 Pitch_Angle 1050;
BA_ "GenSigStartValue" SG_ 319 Pitch_Angle 90;
BA_ "GenSigSNA" SG_ 319 Pitch_Angle "FFh";
BA_ "GenSigCycleTime" SG_ 319 Pitch_Angle 100;
BA_ "FlexKomSigStartValue" SG_ 319 Pitch_Angle "5Ah";
BA_ "FlexKomSigStartPos" SG_ 319 Pitch_Angle 7;
BA_ "FlexKomSigName" SG_ 319 Pitch_Angle "Pitch_Angle";
BA_ "FlexKomSigLaenge" SG_ 319 Pitch_Angle 8;
BA_ "FlexKomSID" SG_ 319 Pitch_Angle 1963;
BA_ "FlexKomIsMotorola" SG_ 319 Pitch_Angle 1;
BA_ "FlexKomComment" SG_ 319 Pitch_Angle "Pitch angle; Disable = [FE]";
BA_ "GenSigTimeout_IC" SG_ 319 Roll_Angle 1050;
BA_ "GenSigStartValue" SG_ 319 Roll_Angle 90;
BA_ "GenSigSNA" SG_ 319 Roll_Angle "FFh";
BA_ "GenSigCycleTime" SG_ 319 Roll_Angle 100;
BA_ "FlexKomSigStartValue" SG_ 319 Roll_Angle "5Ah";
BA_ "FlexKomSigStartPos" SG_ 319 Roll_Angle 15;
BA_ "FlexKomSigName" SG_ 319 Roll_Angle "Roll_Angle";
BA_ "FlexKomSigLaenge" SG_ 319 Roll_Angle 8;
BA_ "FlexKomSID" SG_ 319 Roll_Angle 1962;
BA_ "FlexKomIsMotorola" SG_ 319 Roll_Angle 1;
BA_ "FlexKomComment" SG_ 319 Roll_Angle "Roll angle";
BA_ "RID" SG_ 319 IBS3_Ibatt "5110";
BA_ "GenSigStartValue" SG_ 319 IBS3_Ibatt 65535;
BA_ "GenSigSNA" SG_ 319 IBS3_Ibatt "FFFFh";
BA_ "GenSigCycleTime" SG_ 319 IBS3_Ibatt 100;
BA_ "FlexKomSigStartValue" SG_ 319 IBS3_Ibatt "FFFFh";
BA_ "FlexKomSigStartPos" SG_ 319 IBS3_Ibatt 23;
BA_ "FlexKomSigName" SG_ 319 IBS3_Ibatt "IBS3_Ibatt";
BA_ "FlexKomSigLaenge" SG_ 319 IBS3_Ibatt 16;
BA_ "FlexKomSID" SG_ 319 IBS3_Ibatt 2650;
BA_ "FlexKomIsMotorola" SG_ 319 IBS3_Ibatt 1;
BA_ "FlexKomComment" SG_ 319 IBS3_Ibatt "Battery current";
BA_ "RID" SG_ 319 IBS3_Vbatt "5106";
BA_ "GenSigStartValue" SG_ 319 IBS3_Vbatt 511;
BA_ "GenSigSNA" SG_ 319 IBS3_Vbatt "1FFh";
BA_ "GenSigCycleTime" SG_ 319 IBS3_Vbatt 100;
BA_ "FlexKomSigStartValue" SG_ 319 IBS3_Vbatt "01FFh";
BA_ "FlexKomSigStartPos" SG_ 319 IBS3_Vbatt 39;
BA_ "FlexKomSigName" SG_ 319 IBS3_Vbatt "IBS3_Vbatt";
BA_ "FlexKomSigLaenge" SG_ 319 IBS3_Vbatt 16;
BA_ "FlexKomSID" SG_ 319 IBS3_Vbatt 2651;
BA_ "FlexKomIsMotorola" SG_ 319 IBS3_Vbatt 1;
BA_ "FlexKomComment" SG_ 319 IBS3_Vbatt "Battery voltage measured at the terminals";
BA_ "RID" SG_ 319 CurrBattFailStatus "5107";
BA_ "GenSigSNA" SG_ 319 CurrBattFailStatus "0h";
BA_ "GenSigCycleTime" SG_ 319 CurrBattFailStatus 100;
BA_ "FlexKomSigStartValue" SG_ 319 CurrBattFailStatus "00h";
BA_ "FlexKomSigStartPos" SG_ 319 CurrBattFailStatus 35;
BA_ "FlexKomSigName" SG_ 319 CurrBattFailStatus "CurrBattFailStatus";
BA_ "FlexKomSigLaenge" SG_ 319 CurrBattFailStatus 1;
BA_ "FlexKomSID" SG_ 319 CurrBattFailStatus 2655;
BA_ "FlexKomIsMotorola" SG_ 319 CurrBattFailStatus 1;
BA_ "FlexKomComment" SG_ 319 CurrBattFailStatus "Failure Status of Current meas. (internal defect)";
BA_ "RID" SG_ 319 VoltBattFailStatus "5083";
BA_ "GenSigSNA" SG_ 319 VoltBattFailStatus "0h";
BA_ "GenSigCycleTime" SG_ 319 VoltBattFailStatus 100;
BA_ "FlexKomSigStartValue" SG_ 319 VoltBattFailStatus "00h";
BA_ "FlexKomSigStartPos" SG_ 319 VoltBattFailStatus 36;
BA_ "FlexKomSigName" SG_ 319 VoltBattFailStatus "VoltBattFailStatus";
BA_ "FlexKomSigLaenge" SG_ 319 VoltBattFailStatus 1;
BA_ "FlexKomSID" SG_ 319 VoltBattFailStatus 2654;
BA_ "FlexKomIsMotorola" SG_ 319 VoltBattFailStatus 1;
BA_ "FlexKomComment" SG_ 319 VoltBattFailStatus "Failure Status of Voltage meas. (internal defect)";
BA_ "RID" SG_ 319 IBS3_Error_Internal "5130";
BA_ "GenSigSNA" SG_ 319 IBS3_Error_Internal "0h";
BA_ "GenSigCycleTime" SG_ 319 IBS3_Error_Internal 100;
BA_ "FlexKomSigStartValue" SG_ 319 IBS3_Error_Internal "00h";
BA_ "FlexKomSigStartPos" SG_ 319 IBS3_Error_Internal 37;
BA_ "FlexKomSigName" SG_ 319 IBS3_Error_Internal "IBS3_Error_Internal";
BA_ "FlexKomSigLaenge" SG_ 319 IBS3_Error_Internal 1;
BA_ "FlexKomSID" SG_ 319 IBS3_Error_Internal 2653;
BA_ "FlexKomIsMotorola" SG_ 319 IBS3_Error_Internal 1;
BA_ "FlexKomComment" SG_ 319 IBS3_Error_Internal "Error in IBS calibration data; No Error = [0], Err";
BA_ "RID" SG_ 319 RsErrIBS3 "5135";
BA_ "GenSigSNA" SG_ 319 RsErrIBS3 "0h";
BA_ "GenSigCycleTime" SG_ 319 RsErrIBS3 100;
BA_ "FlexKomSigStartValue" SG_ 319 RsErrIBS3 "00h";
BA_ "FlexKomSigStartPos" SG_ 319 RsErrIBS3 38;
BA_ "FlexKomSigName" SG_ 319 RsErrIBS3 "RsErrIBS3";
BA_ "FlexKomSigLaenge" SG_ 319 RsErrIBS3 1;
BA_ "FlexKomSID" SG_ 319 RsErrIBS3 2652;
BA_ "FlexKomIsMotorola" SG_ 319 RsErrIBS3 1;
BA_ "FlexKomComment" SG_ 319 RsErrIBS3 "Response Error IBS; Error=[1]";
BA_ "GenSigSNA" SG_ 319 CBCSAMFailSts "0h";
BA_ "GenSigCycleTime" SG_ 319 CBCSAMFailSts 100;
BA_ "FlexKomSigStartValue" SG_ 319 CBCSAMFailSts "00h";
BA_ "FlexKomSigStartPos" SG_ 319 CBCSAMFailSts 39;
BA_ "FlexKomSigName" SG_ 319 CBCSAMFailSts "CBCSAMFailSts";
BA_ "FlexKomSigLaenge" SG_ 319 CBCSAMFailSts 1;
BA_ "FlexKomSID" SG_ 319 CBCSAMFailSts 2648;
BA_ "FlexKomIsMotorola" SG_ 319 CBCSAMFailSts 1;
BA_ "FlexKomComment" SG_ 319 CBCSAMFailSts "Fault present in BCM related to the SAM strategy";
BA_ "GenSigSNA" SG_ 319 VoltageMax "0h";
BA_ "GenSigCycleTime" SG_ 319 VoltageMax 100;
BA_ "FlexKomSigStartValue" SG_ 319 VoltageMax "0000h";
BA_ "FlexKomSigStartPos" SG_ 319 VoltageMax 55;
BA_ "FlexKomSigName" SG_ 319 VoltageMax "VoltageRange";
BA_ "FlexKomSigLaenge" SG_ 319 VoltageMax 16;
BA_ "FlexKomSID" SG_ 319 VoltageMax 2647;
BA_ "FlexKomIsMotorola" SG_ 319 VoltageMax 1;
BA_ "FlexKomComment" SG_ 319 VoltageMax "Voltage range packet related to SAM strategy";
BA_ "GenSigSNA" SG_ 319 VoltageMin "0h";
BA_ "GenSigCycleTime" SG_ 319 VoltageMin 100;
BA_ "FlexKomSigStartValue" SG_ 319 VoltageMin "0000h";
BA_ "FlexKomSigStartPos" SG_ 319 VoltageMin 55;
BA_ "FlexKomSigName" SG_ 319 VoltageMin "VoltageRange";
BA_ "FlexKomSigLaenge" SG_ 319 VoltageMin 16;
BA_ "FlexKomSID" SG_ 319 VoltageMin 2647;
BA_ "FlexKomIsMotorola" SG_ 319 VoltageMin 1;
BA_ "FlexKomComment" SG_ 319 VoltageMin "Voltage range packet related to SAM strategy";
BA_ "GenSigTimeout_IC" SG_ 321 HEV_LMP_RQ 1050;
BA_ "GenSigStartValue" SG_ 321 HEV_LMP_RQ 3;
BA_ "GenSigSNA" SG_ 321 HEV_LMP_RQ "3h";
BA_ "GenSigCycleTime" SG_ 321 HEV_LMP_RQ 100;
BA_ "FlexKomSigStartValue" SG_ 321 HEV_LMP_RQ "03000EFA00FF01FFh";
BA_ "FlexKomSigStartPos" SG_ 321 HEV_LMP_RQ 7;
BA_ "FlexKomSigName" SG_ 321 HEV_LMP_RQ "HCP_1";
BA_ "FlexKomSigLaenge" SG_ 321 HEV_LMP_RQ 64;
BA_ "FlexKomSID" SG_ 321 HEV_LMP_RQ 2198;
BA_ "FlexKomIsMotorola" SG_ 321 HEV_LMP_RQ 1;
BA_ "FlexKomComment" SG_ 321 HEV_LMP_RQ "HCP message 1 packet";
BA_ "RID" SG_ 321 HEV_EVT_MD "6517";
BA_ "GenSigTimeout_IC" SG_ 321 HEV_EVT_MD 1050;
BA_ "GenSigTimeout_CBC" SG_ 321 HEV_EVT_MD 10500;
BA_ "GenSigStartValue" SG_ 321 HEV_EVT_MD 1;
BA_ "GenSigSNA" SG_ 321 HEV_EVT_MD "1h";
BA_ "GenSigCycleTime" SG_ 321 HEV_EVT_MD 100;
BA_ "FlexKomSigStartValue" SG_ 321 HEV_EVT_MD "03000EFA00FF01FFh";
BA_ "FlexKomSigStartPos" SG_ 321 HEV_EVT_MD 7;
BA_ "FlexKomSigName" SG_ 321 HEV_EVT_MD "HCP_1";
BA_ "FlexKomSigLaenge" SG_ 321 HEV_EVT_MD 64;
BA_ "FlexKomSID" SG_ 321 HEV_EVT_MD 2198;
BA_ "FlexKomIsMotorola" SG_ 321 HEV_EVT_MD 1;
BA_ "FlexKomComment" SG_ 321 HEV_EVT_MD "HCP message 1 packet";
BA_ "GenSigTimeout_IC" SG_ 321 BatPwrUsage_V 1050;
BA_ "GenSigSNA" SG_ 321 BatPwrUsage_V "0h";
BA_ "GenSigCycleTime" SG_ 321 BatPwrUsage_V 100;
BA_ "FlexKomSigStartValue" SG_ 321 BatPwrUsage_V "03000EFA00FF01FFh";
BA_ "FlexKomSigStartPos" SG_ 321 BatPwrUsage_V 7;
BA_ "FlexKomSigName" SG_ 321 BatPwrUsage_V "HCP_1";
BA_ "FlexKomSigLaenge" SG_ 321 BatPwrUsage_V 64;
BA_ "FlexKomSID" SG_ 321 BatPwrUsage_V 2198;
BA_ "FlexKomIsMotorola" SG_ 321 BatPwrUsage_V 1;
BA_ "FlexKomComment" SG_ 321 BatPwrUsage_V "HCP message 1 packet";
BA_ "GenSigTimeout_IC" SG_ 321 BatPwrUsage 1050;
BA_ "GenSigSNA" SG_ 321 BatPwrUsage "0h";
BA_ "GenSigCycleTime" SG_ 321 BatPwrUsage 100;
BA_ "FlexKomSigStartValue" SG_ 321 BatPwrUsage "03000EFA00FF01FFh";
BA_ "FlexKomSigStartPos" SG_ 321 BatPwrUsage 7;
BA_ "FlexKomSigName" SG_ 321 BatPwrUsage "HCP_1";
BA_ "FlexKomSigLaenge" SG_ 321 BatPwrUsage 64;
BA_ "FlexKomSID" SG_ 321 BatPwrUsage 2198;
BA_ "FlexKomIsMotorola" SG_ 321 BatPwrUsage 1;
BA_ "FlexKomComment" SG_ 321 BatPwrUsage "HCP message 1 packet";
BA_ "GenSigTimeout_IC" SG_ 321 Est_Range 1050;
BA_ "GenSigStartValue" SG_ 321 Est_Range 255;
BA_ "GenSigSNA" SG_ 321 Est_Range "FFh";
BA_ "GenSigCycleTime" SG_ 321 Est_Range 100;
BA_ "FlexKomSigStartValue" SG_ 321 Est_Range "03000EFA00FF01FFh";
BA_ "FlexKomSigStartPos" SG_ 321 Est_Range 7;
BA_ "FlexKomSigName" SG_ 321 Est_Range "HCP_1";
BA_ "FlexKomSigLaenge" SG_ 321 Est_Range 64;
BA_ "FlexKomSID" SG_ 321 Est_Range 2198;
BA_ "FlexKomIsMotorola" SG_ 321 Est_Range 1;
BA_ "FlexKomComment" SG_ 321 Est_Range "HCP message 1 packet";
BA_ "GenSigSNA" SG_ 321 MaxRegenLedCmd "3h";
BA_ "GenSigCycleTime" SG_ 321 MaxRegenLedCmd 100;
BA_ "FlexKomSigStartValue" SG_ 321 MaxRegenLedCmd "03000EFA00FF01FFh";
BA_ "FlexKomSigStartPos" SG_ 321 MaxRegenLedCmd 7;
BA_ "FlexKomSigName" SG_ 321 MaxRegenLedCmd "HCP_1";
BA_ "FlexKomSigLaenge" SG_ 321 MaxRegenLedCmd 64;
BA_ "FlexKomSID" SG_ 321 MaxRegenLedCmd 2198;
BA_ "FlexKomIsMotorola" SG_ 321 MaxRegenLedCmd 1;
BA_ "FlexKomComment" SG_ 321 MaxRegenLedCmd "HCP message 1 packet";
BA_ "RID" SG_ 321 R134a_PressSts "5059";
BA_ "GenSigTimeout_CBC" SG_ 321 R134a_PressSts 1050;
BA_ "GenSigStartValue" SG_ 321 R134a_PressSts 511;
BA_ "GenSigSNA" SG_ 321 R134a_PressSts "1FFh";
BA_ "GenSigCycleTime" SG_ 321 R134a_PressSts 100;
BA_ "FlexKomSigStartValue" SG_ 321 R134a_PressSts "03000EFA00FF01FFh";
BA_ "FlexKomSigStartPos" SG_ 321 R134a_PressSts 7;
BA_ "FlexKomSigName" SG_ 321 R134a_PressSts "HCP_1";
BA_ "FlexKomSigLaenge" SG_ 321 R134a_PressSts 64;
BA_ "FlexKomSID" SG_ 321 R134a_PressSts 2198;
BA_ "FlexKomIsMotorola" SG_ 321 R134a_PressSts 1;
BA_ "FlexKomComment" SG_ 321 R134a_PressSts "HCP message 1 packet";
BA_ "RID" SG_ 321 Echarge_Type_Cnfm "6559";
BA_ "GenSigSNA" SG_ 321 Echarge_Type_Cnfm "0h";
BA_ "GenSigCycleTime" SG_ 321 Echarge_Type_Cnfm 100;
BA_ "FlexKomSigStartValue" SG_ 321 Echarge_Type_Cnfm "03000EFA00FF01FFh";
BA_ "FlexKomSigStartPos" SG_ 321 Echarge_Type_Cnfm 7;
BA_ "FlexKomSigName" SG_ 321 Echarge_Type_Cnfm "HCP_1";
BA_ "FlexKomSigLaenge" SG_ 321 Echarge_Type_Cnfm 64;
BA_ "FlexKomSID" SG_ 321 Echarge_Type_Cnfm 2198;
BA_ "FlexKomIsMotorola" SG_ 321 Echarge_Type_Cnfm 1;
BA_ "FlexKomComment" SG_ 321 Echarge_Type_Cnfm "HCP message 1 packet";
BA_ "RID" SG_ 321 Echarge_SOCRange_Cnfm "6558";
BA_ "GenSigSNA" SG_ 321 Echarge_SOCRange_Cnfm "0h";
BA_ "GenSigCycleTime" SG_ 321 Echarge_SOCRange_Cnfm 100;
BA_ "FlexKomSigStartValue" SG_ 321 Echarge_SOCRange_Cnfm "03000EFA00FF01FFh";
BA_ "FlexKomSigStartPos" SG_ 321 Echarge_SOCRange_Cnfm 7;
BA_ "FlexKomSigName" SG_ 321 Echarge_SOCRange_Cnfm "HCP_1";
BA_ "FlexKomSigLaenge" SG_ 321 Echarge_SOCRange_Cnfm 64;
BA_ "FlexKomSID" SG_ 321 Echarge_SOCRange_Cnfm 2198;
BA_ "FlexKomIsMotorola" SG_ 321 Echarge_SOCRange_Cnfm 1;
BA_ "FlexKomComment" SG_ 321 Echarge_SOCRange_Cnfm "HCP message 1 packet";
BA_ "GenSigStartValue" SG_ 321 HVBatSOH 100;
BA_ "GenSigSNA" SG_ 321 HVBatSOH "FFh";
BA_ "GenSigCycleTime" SG_ 321 HVBatSOH 100;
BA_ "FlexKomSigStartValue" SG_ 321 HVBatSOH "03000EFA00FF01FFh";
BA_ "FlexKomSigStartPos" SG_ 321 HVBatSOH 7;
BA_ "FlexKomSigName" SG_ 321 HVBatSOH "HCP_1";
BA_ "FlexKomSigLaenge" SG_ 321 HVBatSOH 64;
BA_ "FlexKomSID" SG_ 321 HVBatSOH 2198;
BA_ "FlexKomIsMotorola" SG_ 321 HVBatSOH 1;
BA_ "FlexKomComment" SG_ 321 HVBatSOH "HCP message 1 packet";
BA_ "GenSigSNA" SG_ 321 EM_OverHeated_VehSpdLimited "0h";
BA_ "GenSigCycleTime" SG_ 321 EM_OverHeated_VehSpdLimited 100;
BA_ "FlexKomSigStartValue" SG_ 321 EM_OverHeated_VehSpdLimited "03000EFA00FF01FFh";
BA_ "FlexKomSigStartPos" SG_ 321 EM_OverHeated_VehSpdLimited 7;
BA_ "FlexKomSigName" SG_ 321 EM_OverHeated_VehSpdLimited "HCP_1";
BA_ "FlexKomSigLaenge" SG_ 321 EM_OverHeated_VehSpdLimited 64;
BA_ "FlexKomSID" SG_ 321 EM_OverHeated_VehSpdLimited 2198;
BA_ "FlexKomIsMotorola" SG_ 321 EM_OverHeated_VehSpdLimited 1;
BA_ "FlexKomComment" SG_ 321 EM_OverHeated_VehSpdLimited "HCP message 1 packet";
BA_ "GenSigTimeout_IC" SG_ 323 DrvAway_Alert 1050;
BA_ "GenSigSNA" SG_ 323 DrvAway_Alert "0h";
BA_ "GenSigCycleTime" SG_ 323 DrvAway_Alert 100;
BA_ "FlexKomSigStartValue" SG_ 323 DrvAway_Alert "00h";
BA_ "FlexKomSigStartPos" SG_ 323 DrvAway_Alert 7;
BA_ "FlexKomSigName" SG_ 323 DrvAway_Alert "DrvAway_Alert";
BA_ "FlexKomSigLaenge" SG_ 323 DrvAway_Alert 1;
BA_ "FlexKomSID" SG_ 323 DrvAway_Alert 2390;
BA_ "FlexKomIsMotorola" SG_ 323 DrvAway_Alert 1;
BA_ "FlexKomComment" SG_ 323 DrvAway_Alert "Drive Away Alert; True = [1]";
BA_ "GenSigTimeout_IC" SG_ 323 DrvAway_Inhibit 1050;
BA_ "GenSigSNA" SG_ 323 DrvAway_Inhibit "0h";
BA_ "GenSigCycleTime" SG_ 323 DrvAway_Inhibit 100;
BA_ "FlexKomSigStartValue" SG_ 323 DrvAway_Inhibit "00h";
BA_ "FlexKomSigStartPos" SG_ 323 DrvAway_Inhibit 15;
BA_ "FlexKomSigName" SG_ 323 DrvAway_Inhibit "DrvAway_Inhibit";
BA_ "FlexKomSigLaenge" SG_ 323 DrvAway_Inhibit 1;
BA_ "FlexKomSID" SG_ 323 DrvAway_Inhibit 2391;
BA_ "FlexKomIsMotorola" SG_ 323 DrvAway_Inhibit 1;
BA_ "FlexKomComment" SG_ 323 DrvAway_Inhibit "Drive Away Inhibit; True = [1]";
BA_ "GenSigSNA" SG_ 323 PCPM_PumpSpeedAct "7Fh";
BA_ "GenSigCycleTime" SG_ 323 PCPM_PumpSpeedAct 100;
BA_ "FlexKomSigStartValue" SG_ 323 PCPM_PumpSpeedAct "00h";
BA_ "FlexKomSigStartPos" SG_ 323 PCPM_PumpSpeedAct 54;
BA_ "FlexKomSigName" SG_ 323 PCPM_PumpSpeedAct "PCPM_PumpSpeedAct_PKT";
BA_ "FlexKomSigLaenge" SG_ 323 PCPM_PumpSpeedAct 7;
BA_ "FlexKomSID" SG_ 323 PCPM_PumpSpeedAct 3468;
BA_ "FlexKomIsMotorola" SG_ 323 PCPM_PumpSpeedAct 1;
BA_ "FlexKomComment" SG_ 323 PCPM_PumpSpeedAct "PCPM_PumpSpeedAct_PKT";
BA_ "GenSigSNA" SG_ 327 MIL_OnRq_ESC "0h";
BA_ "GenSigCycleTime" SG_ 327 MIL_OnRq_ESC 100;
BA_ "FlexKomSigStartValue" SG_ 327 MIL_OnRq_ESC "00h";
BA_ "FlexKomSigStartPos" SG_ 327 MIL_OnRq_ESC 2;
BA_ "FlexKomSigName" SG_ 327 MIL_OnRq_ESC "MIL_OnRq_ESC";
BA_ "FlexKomSigLaenge" SG_ 327 MIL_OnRq_ESC 1;
BA_ "FlexKomSID" SG_ 327 MIL_OnRq_ESC 2375;
BA_ "FlexKomIsMotorola" SG_ 327 MIL_OnRq_ESC 1;
BA_ "FlexKomComment" SG_ 327 MIL_OnRq_ESC "MIL on request from the ESC";
BA_ "GenSigSNA" SG_ 327 ESCSysEmsMlfAtv "0h";
BA_ "GenSigCycleTime" SG_ 327 ESCSysEmsMlfAtv 100;
BA_ "FlexKomSigStartValue" SG_ 327 ESCSysEmsMlfAtv "00h";
BA_ "FlexKomSigStartPos" SG_ 327 ESCSysEmsMlfAtv 18;
BA_ "FlexKomSigName" SG_ 327 ESCSysEmsMlfAtv "ESCSysEmsMlfAtv";
BA_ "FlexKomSigLaenge" SG_ 327 ESCSysEmsMlfAtv 1;
BA_ "FlexKomSID" SG_ 327 ESCSysEmsMlfAtv 2376;
BA_ "FlexKomIsMotorola" SG_ 327 ESCSysEmsMlfAtv 1;
BA_ "FlexKomComment" SG_ 327 ESCSysEmsMlfAtv "ESC emissions related malfunction active";
BA_ "GenSigTimeout_ORC" SG_ 333 VVT_ExhCam1Pos 350;
BA_ "GenSigStartValue" SG_ 333 VVT_ExhCam1Pos 255;
BA_ "GenSigSNA" SG_ 333 VVT_ExhCam1Pos "0h";
BA_ "GenSigCycleTime" SG_ 333 VVT_ExhCam1Pos 100;
BA_ "FlexKomSigStartValue" SG_ 333 VVT_ExhCam1Pos "FFFFFFFF0000FF00h";
BA_ "FlexKomSigStartPos" SG_ 333 VVT_ExhCam1Pos 7;
BA_ "FlexKomSigName" SG_ 333 VVT_ExhCam1Pos "EDR2_Pkt";
BA_ "FlexKomSigLaenge" SG_ 333 VVT_ExhCam1Pos 64;
BA_ "FlexKomSID" SG_ 333 VVT_ExhCam1Pos 1093;
BA_ "FlexKomIsMotorola" SG_ 333 VVT_ExhCam1Pos 1;
BA_ "FlexKomComment" SG_ 333 VVT_ExhCam1Pos "EDR2 information packet only";
BA_ "GenSigTimeout_ORC" SG_ 333 VVT_ExhCam2Pos 350;
BA_ "GenSigStartValue" SG_ 333 VVT_ExhCam2Pos 255;
BA_ "GenSigSNA" SG_ 333 VVT_ExhCam2Pos "0h";
BA_ "GenSigCycleTime" SG_ 333 VVT_ExhCam2Pos 100;
BA_ "FlexKomSigStartValue" SG_ 333 VVT_ExhCam2Pos "FFFFFFFF0000FF00h";
BA_ "FlexKomSigStartPos" SG_ 333 VVT_ExhCam2Pos 7;
BA_ "FlexKomSigName" SG_ 333 VVT_ExhCam2Pos "EDR2_Pkt";
BA_ "FlexKomSigLaenge" SG_ 333 VVT_ExhCam2Pos 64;
BA_ "FlexKomSID" SG_ 333 VVT_ExhCam2Pos 1093;
BA_ "FlexKomIsMotorola" SG_ 333 VVT_ExhCam2Pos 1;
BA_ "FlexKomComment" SG_ 333 VVT_ExhCam2Pos "EDR2 information packet only";
BA_ "GenSigTimeout_ORC" SG_ 333 VVT_IntCam1Pos 350;
BA_ "GenSigStartValue" SG_ 333 VVT_IntCam1Pos 255;
BA_ "GenSigSNA" SG_ 333 VVT_IntCam1Pos "0h";
BA_ "GenSigCycleTime" SG_ 333 VVT_IntCam1Pos 100;
BA_ "FlexKomSigStartValue" SG_ 333 VVT_IntCam1Pos "FFFFFFFF0000FF00h";
BA_ "FlexKomSigStartPos" SG_ 333 VVT_IntCam1Pos 7;
BA_ "FlexKomSigName" SG_ 333 VVT_IntCam1Pos "EDR2_Pkt";
BA_ "FlexKomSigLaenge" SG_ 333 VVT_IntCam1Pos 64;
BA_ "FlexKomSID" SG_ 333 VVT_IntCam1Pos 1093;
BA_ "FlexKomIsMotorola" SG_ 333 VVT_IntCam1Pos 1;
BA_ "FlexKomComment" SG_ 333 VVT_IntCam1Pos "EDR2 information packet only";
BA_ "GenSigTimeout_ORC" SG_ 333 VVT_IntCam2Pos 350;
BA_ "GenSigStartValue" SG_ 333 VVT_IntCam2Pos 255;
BA_ "GenSigSNA" SG_ 333 VVT_IntCam2Pos "0h";
BA_ "GenSigCycleTime" SG_ 333 VVT_IntCam2Pos 100;
BA_ "FlexKomSigStartValue" SG_ 333 VVT_IntCam2Pos "FFFFFFFF0000FF00h";
BA_ "FlexKomSigStartPos" SG_ 333 VVT_IntCam2Pos 7;
BA_ "FlexKomSigName" SG_ 333 VVT_IntCam2Pos "EDR2_Pkt";
BA_ "FlexKomSigLaenge" SG_ 333 VVT_IntCam2Pos 64;
BA_ "FlexKomSID" SG_ 333 VVT_IntCam2Pos 1093;
BA_ "FlexKomIsMotorola" SG_ 333 VVT_IntCam2Pos 1;
BA_ "FlexKomComment" SG_ 333 VVT_IntCam2Pos "EDR2 information packet only";
BA_ "GenSigTimeout_ORC" SG_ 333 GF_Charge 350;
BA_ "GenSigSNA" SG_ 333 GF_Charge "FFFFh";
BA_ "GenSigCycleTime" SG_ 333 GF_Charge 100;
BA_ "FlexKomSigStartValue" SG_ 333 GF_Charge "FFFFFFFF0000FF00h";
BA_ "FlexKomSigStartPos" SG_ 333 GF_Charge 7;
BA_ "FlexKomSigName" SG_ 333 GF_Charge "EDR2_Pkt";
BA_ "FlexKomSigLaenge" SG_ 333 GF_Charge 64;
BA_ "FlexKomSID" SG_ 333 GF_Charge 1093;
BA_ "FlexKomIsMotorola" SG_ 333 GF_Charge 1;
BA_ "FlexKomComment" SG_ 333 GF_Charge "EDR2 information packet only";
BA_ "GenSigTimeout_ORC" SG_ 333 RelativeThrtPct 350;
BA_ "GenSigStartValue" SG_ 333 RelativeThrtPct 255;
BA_ "GenSigSNA" SG_ 333 RelativeThrtPct "FFh";
BA_ "GenSigCycleTime" SG_ 333 RelativeThrtPct 100;
BA_ "FlexKomSigStartValue" SG_ 333 RelativeThrtPct "FFFFFFFF0000FF00h";
BA_ "FlexKomSigStartPos" SG_ 333 RelativeThrtPct 7;
BA_ "FlexKomSigName" SG_ 333 RelativeThrtPct "EDR2_Pkt";
BA_ "FlexKomSigLaenge" SG_ 333 RelativeThrtPct 64;
BA_ "FlexKomSID" SG_ 333 RelativeThrtPct 1093;
BA_ "FlexKomIsMotorola" SG_ 333 RelativeThrtPct 1;
BA_ "FlexKomComment" SG_ 333 RelativeThrtPct "EDR2 information packet only";
BA_ "GenSigTimeout_ORC" SG_ 334 ApplyTrq 350;
BA_ "GenSigSNA" SG_ 334 ApplyTrq "0h";
BA_ "GenSigCycleTime" SG_ 334 ApplyTrq 100;
BA_ "FlexKomSigStartValue" SG_ 334 ApplyTrq "00FFFFFFFFFFFFFFh";
BA_ "FlexKomSigStartPos" SG_ 334 ApplyTrq 7;
BA_ "FlexKomSigName" SG_ 334 ApplyTrq "EDR_Pkt";
BA_ "FlexKomSigLaenge" SG_ 334 ApplyTrq 64;
BA_ "FlexKomSID" SG_ 334 ApplyTrq 762;
BA_ "FlexKomIsMotorola" SG_ 334 ApplyTrq 1;
BA_ "FlexKomComment" SG_ 334 ApplyTrq "EDR Only information packet";
BA_ "GenSigSNA" SG_ 334 BrkSw1Stat "0h";
BA_ "GenSigCycleTime" SG_ 334 BrkSw1Stat 100;
BA_ "FlexKomSigStartValue" SG_ 334 BrkSw1Stat "00FFFFFFFFFFFFFFh";
BA_ "FlexKomSigStartPos" SG_ 334 BrkSw1Stat 7;
BA_ "FlexKomSigName" SG_ 334 BrkSw1Stat "EDR_Pkt";
BA_ "FlexKomSigLaenge" SG_ 334 BrkSw1Stat 64;
BA_ "FlexKomSID" SG_ 334 BrkSw1Stat 762;
BA_ "FlexKomIsMotorola" SG_ 334 BrkSw1Stat 1;
BA_ "FlexKomComment" SG_ 334 BrkSw1Stat "EDR Only information packet";
BA_ "GenSigTimeout_ORC" SG_ 334 ESP_TrqRqEnabl 350;
BA_ "GenSigSNA" SG_ 334 ESP_TrqRqEnabl "0h";
BA_ "GenSigCycleTime" SG_ 334 ESP_TrqRqEnabl 100;
BA_ "FlexKomSigStartValue" SG_ 334 ESP_TrqRqEnabl "00FFFFFFFFFFFFFFh";
BA_ "FlexKomSigStartPos" SG_ 334 ESP_TrqRqEnabl 7;
BA_ "FlexKomSigName" SG_ 334 ESP_TrqRqEnabl "EDR_Pkt";
BA_ "FlexKomSigLaenge" SG_ 334 ESP_TrqRqEnabl 64;
BA_ "FlexKomSID" SG_ 334 ESP_TrqRqEnabl 762;
BA_ "FlexKomIsMotorola" SG_ 334 ESP_TrqRqEnabl 1;
BA_ "FlexKomComment" SG_ 334 ESP_TrqRqEnabl "EDR Only information packet";
BA_ "GenSigTimeout_ORC" SG_ 334 ETC_LmpFlash 350;
BA_ "GenSigSNA" SG_ 334 ETC_LmpFlash "0h";
BA_ "GenSigCycleTime" SG_ 334 ETC_LmpFlash 100;
BA_ "FlexKomSigStartValue" SG_ 334 ETC_LmpFlash "00FFFFFFFFFFFFFFh";
BA_ "FlexKomSigStartPos" SG_ 334 ETC_LmpFlash 7;
BA_ "FlexKomSigName" SG_ 334 ETC_LmpFlash "EDR_Pkt";
BA_ "FlexKomSigLaenge" SG_ 334 ETC_LmpFlash 64;
BA_ "FlexKomSID" SG_ 334 ETC_LmpFlash 762;
BA_ "FlexKomIsMotorola" SG_ 334 ETC_LmpFlash 1;
BA_ "FlexKomComment" SG_ 334 ETC_LmpFlash "EDR Only information packet";
BA_ "GenSigTimeout_ORC" SG_ 334 ETC_LmpOn 350;
BA_ "GenSigSNA" SG_ 334 ETC_LmpOn "0h";
BA_ "GenSigCycleTime" SG_ 334 ETC_LmpOn 100;
BA_ "FlexKomSigStartValue" SG_ 334 ETC_LmpOn "00FFFFFFFFFFFFFFh";
BA_ "FlexKomSigStartPos" SG_ 334 ETC_LmpOn 7;
BA_ "FlexKomSigName" SG_ 334 ETC_LmpOn "EDR_Pkt";
BA_ "FlexKomSigLaenge" SG_ 334 ETC_LmpOn 64;
BA_ "FlexKomSID" SG_ 334 ETC_LmpOn 762;
BA_ "FlexKomIsMotorola" SG_ 334 ETC_LmpOn 1;
BA_ "FlexKomComment" SG_ 334 ETC_LmpOn "EDR Only information packet";
BA_ "GenSigTimeout_ORC" SG_ 334 Lv1CrsCtrlOff 350;
BA_ "GenSigSNA" SG_ 334 Lv1CrsCtrlOff "0h";
BA_ "GenSigCycleTime" SG_ 334 Lv1CrsCtrlOff 100;
BA_ "FlexKomSigStartValue" SG_ 334 Lv1CrsCtrlOff "00FFFFFFFFFFFFFFh";
BA_ "FlexKomSigStartPos" SG_ 334 Lv1CrsCtrlOff 7;
BA_ "FlexKomSigName" SG_ 334 Lv1CrsCtrlOff "EDR_Pkt";
BA_ "FlexKomSigLaenge" SG_ 334 Lv1CrsCtrlOff 64;
BA_ "FlexKomSID" SG_ 334 Lv1CrsCtrlOff 762;
BA_ "FlexKomIsMotorola" SG_ 334 Lv1CrsCtrlOff 1;
BA_ "FlexKomComment" SG_ 334 Lv1CrsCtrlOff "EDR Only information packet";
BA_ "GenSigTimeout_ORC" SG_ 334 CruiseEGD 350;
BA_ "GenSigSNA" SG_ 334 CruiseEGD "0h";
BA_ "GenSigCycleTime" SG_ 334 CruiseEGD 100;
BA_ "FlexKomSigStartValue" SG_ 334 CruiseEGD "00FFFFFFFFFFFFFFh";
BA_ "FlexKomSigStartPos" SG_ 334 CruiseEGD 7;
BA_ "FlexKomSigName" SG_ 334 CruiseEGD "EDR_Pkt";
BA_ "FlexKomSigLaenge" SG_ 334 CruiseEGD 64;
BA_ "FlexKomSID" SG_ 334 CruiseEGD 762;
BA_ "FlexKomIsMotorola" SG_ 334 CruiseEGD 1;
BA_ "FlexKomComment" SG_ 334 CruiseEGD "EDR Only information packet";
BA_ "GenSigTimeout_ORC" SG_ 334 RawPVS1 350;
BA_ "GenSigStartValue" SG_ 334 RawPVS1 255;
BA_ "GenSigSNA" SG_ 334 RawPVS1 "FFh";
BA_ "GenSigCycleTime" SG_ 334 RawPVS1 100;
BA_ "FlexKomSigStartValue" SG_ 334 RawPVS1 "00FFFFFFFFFFFFFFh";
BA_ "FlexKomSigStartPos" SG_ 334 RawPVS1 7;
BA_ "FlexKomSigName" SG_ 334 RawPVS1 "EDR_Pkt";
BA_ "FlexKomSigLaenge" SG_ 334 RawPVS1 64;
BA_ "FlexKomSID" SG_ 334 RawPVS1 762;
BA_ "FlexKomIsMotorola" SG_ 334 RawPVS1 1;
BA_ "FlexKomComment" SG_ 334 RawPVS1 "EDR Only information packet";
BA_ "GenSigTimeout_ORC" SG_ 334 RawPVS2 350;
BA_ "GenSigStartValue" SG_ 334 RawPVS2 255;
BA_ "GenSigSNA" SG_ 334 RawPVS2 "FFh";
BA_ "GenSigCycleTime" SG_ 334 RawPVS2 100;
BA_ "FlexKomSigStartValue" SG_ 334 RawPVS2 "00FFFFFFFFFFFFFFh";
BA_ "FlexKomSigStartPos" SG_ 334 RawPVS2 7;
BA_ "FlexKomSigName" SG_ 334 RawPVS2 "EDR_Pkt";
BA_ "FlexKomSigLaenge" SG_ 334 RawPVS2 64;
BA_ "FlexKomSID" SG_ 334 RawPVS2 762;
BA_ "FlexKomIsMotorola" SG_ 334 RawPVS2 1;
BA_ "FlexKomComment" SG_ 334 RawPVS2 "EDR Only information packet";
BA_ "GenSigTimeout_ORC" SG_ 334 RawTPS1 350;
BA_ "GenSigStartValue" SG_ 334 RawTPS1 255;
BA_ "GenSigSNA" SG_ 334 RawTPS1 "FFh";
BA_ "GenSigCycleTime" SG_ 334 RawTPS1 100;
BA_ "FlexKomSigStartValue" SG_ 334 RawTPS1 "00FFFFFFFFFFFFFFh";
BA_ "FlexKomSigStartPos" SG_ 334 RawTPS1 7;
BA_ "FlexKomSigName" SG_ 334 RawTPS1 "EDR_Pkt";
BA_ "FlexKomSigLaenge" SG_ 334 RawTPS1 64;
BA_ "FlexKomSID" SG_ 334 RawTPS1 762;
BA_ "FlexKomIsMotorola" SG_ 334 RawTPS1 1;
BA_ "FlexKomComment" SG_ 334 RawTPS1 "EDR Only information packet";
BA_ "GenSigTimeout_ORC" SG_ 334 RawTPS2 350;
BA_ "GenSigStartValue" SG_ 334 RawTPS2 255;
BA_ "GenSigSNA" SG_ 334 RawTPS2 "FFh";
BA_ "GenSigCycleTime" SG_ 334 RawTPS2 100;
BA_ "FlexKomSigStartValue" SG_ 334 RawTPS2 "00FFFFFFFFFFFFFFh";
BA_ "FlexKomSigStartPos" SG_ 334 RawTPS2 7;
BA_ "FlexKomSigName" SG_ 334 RawTPS2 "EDR_Pkt";
BA_ "FlexKomSigLaenge" SG_ 334 RawTPS2 64;
BA_ "FlexKomSID" SG_ 334 RawTPS2 762;
BA_ "FlexKomIsMotorola" SG_ 334 RawTPS2 1;
BA_ "FlexKomComment" SG_ 334 RawTPS2 "EDR Only information packet";
BA_ "GenSigTimeout_ORC" SG_ 334 RelativePdl 350;
BA_ "GenSigStartValue" SG_ 334 RelativePdl 255;
BA_ "GenSigSNA" SG_ 334 RelativePdl "FFh";
BA_ "GenSigCycleTime" SG_ 334 RelativePdl 100;
BA_ "FlexKomSigStartValue" SG_ 334 RelativePdl "00FFFFFFFFFFFFFFh";
BA_ "FlexKomSigStartPos" SG_ 334 RelativePdl 7;
BA_ "FlexKomSigName" SG_ 334 RelativePdl "EDR_Pkt";
BA_ "FlexKomSigLaenge" SG_ 334 RelativePdl 64;
BA_ "FlexKomSID" SG_ 334 RelativePdl 762;
BA_ "FlexKomIsMotorola" SG_ 334 RelativePdl 1;
BA_ "FlexKomComment" SG_ 334 RelativePdl "EDR Only information packet";
BA_ "GenSigTimeout_ORC" SG_ 334 RelativeThrt 350;
BA_ "GenSigStartValue" SG_ 334 RelativeThrt 255;
BA_ "GenSigSNA" SG_ 334 RelativeThrt "FFh";
BA_ "GenSigCycleTime" SG_ 334 RelativeThrt 100;
BA_ "FlexKomSigStartValue" SG_ 334 RelativeThrt "00FFFFFFFFFFFFFFh";
BA_ "FlexKomSigStartPos" SG_ 334 RelativeThrt 7;
BA_ "FlexKomSigName" SG_ 334 RelativeThrt "EDR_Pkt";
BA_ "FlexKomSigLaenge" SG_ 334 RelativeThrt 64;
BA_ "FlexKomSID" SG_ 334 RelativeThrt 762;
BA_ "FlexKomIsMotorola" SG_ 334 RelativeThrt 1;
BA_ "FlexKomComment" SG_ 334 RelativeThrt "EDR Only information packet";
BA_ "GenSigTimeout_ORC" SG_ 334 MAP 350;
BA_ "GenSigStartValue" SG_ 334 MAP 255;
BA_ "GenSigSNA" SG_ 334 MAP "FFh";
BA_ "GenSigCycleTime" SG_ 334 MAP 100;
BA_ "FlexKomSigStartValue" SG_ 334 MAP "00FFFFFFFFFFFFFFh";
BA_ "FlexKomSigStartPos" SG_ 334 MAP 7;
BA_ "FlexKomSigName" SG_ 334 MAP "EDR_Pkt";
BA_ "FlexKomSigLaenge" SG_ 334 MAP 64;
BA_ "FlexKomSID" SG_ 334 MAP 762;
BA_ "FlexKomIsMotorola" SG_ 334 MAP 1;
BA_ "FlexKomComment" SG_ 334 MAP "EDR Only information packet";
BA_ "GenSigSNA" SG_ 343 LeakCheckTimerValue "1FFh";
BA_ "GenSigCycleTime" SG_ 343 LeakCheckTimerValue 100;
BA_ "FlexKomSigStartValue" SG_ 343 LeakCheckTimerValue "0000h";
BA_ "FlexKomSigStartPos" SG_ 343 LeakCheckTimerValue 15;
BA_ "FlexKomSigName" SG_ 343 LeakCheckTimerValue "LeakCheckTimerValue";
BA_ "FlexKomSigLaenge" SG_ 343 LeakCheckTimerValue 16;
BA_ "FlexKomSID" SG_ 343 LeakCheckTimerValue 2575;
BA_ "FlexKomIsMotorola" SG_ 343 LeakCheckTimerValue 1;
BA_ "FlexKomComment" SG_ 343 LeakCheckTimerValue "Requested leak test timer value";
BA_ "GenSigSNA" SG_ 343 RefuelEvent "0h";
BA_ "GenSigCycleTime" SG_ 343 RefuelEvent 100;
BA_ "FlexKomSigStartValue" SG_ 343 RefuelEvent "00h";
BA_ "FlexKomSigStartPos" SG_ 343 RefuelEvent 13;
BA_ "FlexKomSigName" SG_ 343 RefuelEvent "RefuelEvent";
BA_ "FlexKomSigLaenge" SG_ 343 RefuelEvent 3;
BA_ "FlexKomSID" SG_ 343 RefuelEvent 2574;
BA_ "FlexKomIsMotorola" SG_ 343 RefuelEvent 1;
BA_ "FlexKomComment" SG_ 343 RefuelEvent "Status of refuel event";
BA_ "GenSigTimeout_IC" SG_ 343 StartProtectionInhibit 1050;
BA_ "GenSigSNA" SG_ 343 StartProtectionInhibit "3h";
BA_ "GenSigCycleTime" SG_ 343 StartProtectionInhibit 100;
BA_ "FlexKomSigStartValue" SG_ 343 StartProtectionInhibit "00h";
BA_ "FlexKomSigStartPos" SG_ 343 StartProtectionInhibit 25;
BA_ "FlexKomSigName" SG_ 343 StartProtectionInhibit "StartProtectionInhibit";
BA_ "FlexKomSigLaenge" SG_ 343 StartProtectionInhibit 2;
BA_ "FlexKomSID" SG_ 343 StartProtectionInhibit 2612;
BA_ "FlexKomIsMotorola" SG_ 343 StartProtectionInhibit 1;
BA_ "FlexKomComment" SG_ 343 StartProtectionInhibit "Starter protection status";
BA_ "GenSigSNA" SG_ 343 LeakTestRequest "0h";
BA_ "GenSigCycleTime" SG_ 343 LeakTestRequest 100;
BA_ "FlexKomSigStartValue" SG_ 343 LeakTestRequest "00h";
BA_ "FlexKomSigStartPos" SG_ 343 LeakTestRequest 26;
BA_ "FlexKomSigName" SG_ 343 LeakTestRequest "LeakTestRequest";
BA_ "FlexKomSigLaenge" SG_ 343 LeakTestRequest 1;
BA_ "FlexKomSID" SG_ 343 LeakTestRequest 2577;
BA_ "FlexKomIsMotorola" SG_ 343 LeakTestRequest 1;
BA_ "FlexKomComment" SG_ 343 LeakTestRequest "Leak test is requested after powerdown; No request";
BA_ "GenSigSNA" SG_ 343 LeakTestSts "0h";
BA_ "GenSigCycleTime" SG_ 343 LeakTestSts 100;
BA_ "FlexKomSigStartValue" SG_ 343 LeakTestSts "00h";
BA_ "FlexKomSigStartPos" SG_ 343 LeakTestSts 28;
BA_ "FlexKomSigName" SG_ 343 LeakTestSts "LeakTestSts";
BA_ "FlexKomSigLaenge" SG_ 343 LeakTestSts 2;
BA_ "FlexKomSID" SG_ 343 LeakTestSts 2576;
BA_ "FlexKomIsMotorola" SG_ 343 LeakTestSts 1;
BA_ "FlexKomComment" SG_ 343 LeakTestSts "Status of leak test";
BA_ "GenSigTimeout_IC" SG_ 343 RefuelIndication 1050;
BA_ "GenSigSNA" SG_ 343 RefuelIndication "0h";
BA_ "GenSigCycleTime" SG_ 343 RefuelIndication 100;
BA_ "FlexKomSigStartValue" SG_ 343 RefuelIndication "00h";
BA_ "FlexKomSigStartPos" SG_ 343 RefuelIndication 31;
BA_ "FlexKomSigName" SG_ 343 RefuelIndication "RefuelIndication";
BA_ "FlexKomSigLaenge" SG_ 343 RefuelIndication 3;
BA_ "FlexKomSID" SG_ 343 RefuelIndication 2578;
BA_ "FlexKomIsMotorola" SG_ 343 RefuelIndication 1;
BA_ "FlexKomComment" SG_ 343 RefuelIndication "Indication to the driver about the status of the r";
BA_ "GenSigTimeout_CBC" SG_ 343 SAMInfo 1050;
BA_ "GenSigStartValue" SG_ 343 SAMInfo 15;
BA_ "GenSigSNA" SG_ 343 SAMInfo "Fh";
BA_ "GenSigCycleTime" SG_ 343 SAMInfo 100;
BA_ "FlexKomSigStartValue" SG_ 343 SAMInfo "0Fh";
BA_ "FlexKomSigStartPos" SG_ 343 SAMInfo 39;
BA_ "FlexKomSigName" SG_ 343 SAMInfo "SAMInfo";
BA_ "FlexKomSigLaenge" SG_ 343 SAMInfo 4;
BA_ "FlexKomSID" SG_ 343 SAMInfo 2649;
BA_ "FlexKomIsMotorola" SG_ 343 SAMInfo 1;
BA_ "FlexKomComment" SG_ 343 SAMInfo "Logic status of the SAM strategy";
BA_ "GenSigTimeout_IC" SG_ 343 StarterProtectionTime 1050;
BA_ "GenSigSNA" SG_ 343 StarterProtectionTime "FFh";
BA_ "GenSigCycleTime" SG_ 343 StarterProtectionTime 100;
BA_ "FlexKomSigStartValue" SG_ 343 StarterProtectionTime "00h";
BA_ "FlexKomSigStartPos" SG_ 343 StarterProtectionTime 47;
BA_ "FlexKomSigName" SG_ 343 StarterProtectionTime "StarterProtectionTime";
BA_ "FlexKomSigLaenge" SG_ 343 StarterProtectionTime 8;
BA_ "FlexKomSID" SG_ 343 StarterProtectionTime 2613;
BA_ "FlexKomIsMotorola" SG_ 343 StarterProtectionTime 1;
BA_ "FlexKomComment" SG_ 343 StarterProtectionTime "Starter protection time";
BA_ "GenSigTimeout_CBC" SG_ 347 RevOilLifeRst 1050;
BA_ "GenSigStartValue" SG_ 347 RevOilLifeRst 65535;
BA_ "GenSigSNA" SG_ 347 RevOilLifeRst "FFFFh";
BA_ "GenSigCycleTime" SG_ 347 RevOilLifeRst 100;
BA_ "FlexKomSigStartValue" SG_ 347 RevOilLifeRst "FFFFh";
BA_ "FlexKomSigStartPos" SG_ 347 RevOilLifeRst 55;
BA_ "FlexKomSigName" SG_ 347 RevOilLifeRst "RevOilLifeRst";
BA_ "FlexKomSigLaenge" SG_ 347 RevOilLifeRst 16;
BA_ "FlexKomSID" SG_ 347 RevOilLifeRst 2109;
BA_ "FlexKomIsMotorola" SG_ 347 RevOilLifeRst 1;
BA_ "FlexKomComment" SG_ 347 RevOilLifeRst "Engine revolutions since last oil life reset";
BA_ "GenSigSNA" SG_ 347 AWD_LOW "0h";
BA_ "GenSigCycleTime" SG_ 347 AWD_LOW 100;
BA_ "FlexKomSigStartValue" SG_ 347 AWD_LOW "00h";
BA_ "FlexKomSigStartPos" SG_ 347 AWD_LOW 7;
BA_ "FlexKomSigName" SG_ 347 AWD_LOW "AWD_LOW";
BA_ "FlexKomSigLaenge" SG_ 347 AWD_LOW 1;
BA_ "FlexKomSID" SG_ 347 AWD_LOW 2977;
BA_ "FlexKomIsMotorola" SG_ 347 AWD_LOW 1;
BA_ "FlexKomComment" SG_ 347 AWD_LOW "AWD LOW status; 0 4LOW_Not_Active 1 4LOW_Active";
BA_ "GenSigSNA" SG_ 347 HighPressureFuelSystemFailure "0h";
BA_ "GenSigCycleTime" SG_ 347 HighPressureFuelSystemFailure 100;
BA_ "FlexKomSigStartValue" SG_ 347 HighPressureFuelSystemFailure "00h";
BA_ "FlexKomSigStartPos" SG_ 347 HighPressureFuelSystemFailure 42;
BA_ "FlexKomSigName" SG_ 347 HighPressureFuelSystemFailure "HighPressureFuelSystemFailure";
BA_ "FlexKomSigLaenge" SG_ 347 HighPressureFuelSystemFailure 1;
BA_ "FlexKomSID" SG_ 347 HighPressureFuelSystemFailure 3099;
BA_ "FlexKomIsMotorola" SG_ 347 HighPressureFuelSystemFailure 1;
BA_ "FlexKomComment" SG_ 347 HighPressureFuelSystemFailure "HighPressureFuelSystemFailure";
BA_ "GenSigSNA" SG_ 347 ECM_READINESS_RESET "0h";
BA_ "GenSigCycleTime" SG_ 347 ECM_READINESS_RESET 100;
BA_ "FlexKomSigStartValue" SG_ 347 ECM_READINESS_RESET "00h";
BA_ "FlexKomSigStartPos" SG_ 347 ECM_READINESS_RESET 41;
BA_ "FlexKomSigName" SG_ 347 ECM_READINESS_RESET "ECM_CODE_READINESS_PDU";
BA_ "FlexKomSigLaenge" SG_ 347 ECM_READINESS_RESET 2;
BA_ "FlexKomSID" SG_ 347 ECM_READINESS_RESET 2963;
BA_ "FlexKomIsMotorola" SG_ 347 ECM_READINESS_RESET 1;
BA_ "FlexKomComment" SG_ 347 ECM_READINESS_RESET "ECM Code Readiness PDU";
BA_ "GenSigSNA" SG_ 347 ECM_CODE_CLR "0h";
BA_ "GenSigCycleTime" SG_ 347 ECM_CODE_CLR 100;
BA_ "FlexKomSigStartValue" SG_ 347 ECM_CODE_CLR "00h";
BA_ "FlexKomSigStartPos" SG_ 347 ECM_CODE_CLR 41;
BA_ "FlexKomSigName" SG_ 347 ECM_CODE_CLR "ECM_CODE_READINESS_PDU";
BA_ "FlexKomSigLaenge" SG_ 347 ECM_CODE_CLR 2;
BA_ "FlexKomSID" SG_ 347 ECM_CODE_CLR 2963;
BA_ "FlexKomIsMotorola" SG_ 347 ECM_CODE_CLR 1;
BA_ "FlexKomComment" SG_ 347 ECM_CODE_CLR "ECM Code Readiness PDU";
BA_ "GenSigSNA" SG_ 423 ESLSts "7h";
BA_ "GenSigCycleTime" SG_ 423 ESLSts 250;
BA_ "FlexKomSigStartValue" SG_ 423 ESLSts "0000h";
BA_ "FlexKomSigStartPos" SG_ 423 ESLSts 7;
BA_ "FlexKomSigName" SG_ 423 ESLSts "StatusESL_Pkt";
BA_ "FlexKomSigLaenge" SG_ 423 ESLSts 16;
BA_ "FlexKomSID" SG_ 423 ESLSts 2368;
BA_ "FlexKomIsMotorola" SG_ 423 ESLSts 1;
BA_ "FlexKomComment" SG_ 423 ESLSts "ESL status packet";
BA_ "GenSigSNA" SG_ 423 KeyOffWithHighSpeedSts "0h";
BA_ "GenSigCycleTime" SG_ 423 KeyOffWithHighSpeedSts 250;
BA_ "FlexKomSigStartValue" SG_ 423 KeyOffWithHighSpeedSts "0000h";
BA_ "FlexKomSigStartPos" SG_ 423 KeyOffWithHighSpeedSts 7;
BA_ "FlexKomSigName" SG_ 423 KeyOffWithHighSpeedSts "StatusESL_Pkt";
BA_ "FlexKomSigLaenge" SG_ 423 KeyOffWithHighSpeedSts 16;
BA_ "FlexKomSID" SG_ 423 KeyOffWithHighSpeedSts 2368;
BA_ "FlexKomIsMotorola" SG_ 423 KeyOffWithHighSpeedSts 1;
BA_ "FlexKomComment" SG_ 423 KeyOffWithHighSpeedSts "ESL status packet";
BA_ "GenSigTimeout_IC" SG_ 448 MsgCrankInGear 2100;
BA_ "GenSigSNA" SG_ 448 MsgCrankInGear "3h";
BA_ "GenSigSendType" SG_ 448 MsgCrankInGear 5;
BA_ "GenSigCycleTime" SG_ 448 MsgCrankInGear 200;
BA_ "FlexKomSigStartValue" SG_ 448 MsgCrankInGear "000000000000h";
BA_ "FlexKomSigStartPos" SG_ 448 MsgCrankInGear 7;
BA_ "FlexKomSigName" SG_ 448 MsgCrankInGear "RFHUB_A2_Pkt";
BA_ "FlexKomSigLaenge" SG_ 448 MsgCrankInGear 48;
BA_ "FlexKomSID" SG_ 448 MsgCrankInGear 1037;
BA_ "FlexKomIsMotorola" SG_ 448 MsgCrankInGear 1;
BA_ "FlexKomComment" SG_ 448 MsgCrankInGear "RFHUB_A2_Pkt";
BA_ "RID" SG_ 448 RFFuncReq "1255";
BA_ "GenSigTimeout_IC" SG_ 448 RFFuncReq 2100;
BA_ "GenSigSNA" SG_ 448 RFFuncReq "1Fh";
BA_ "GenSigSendType" SG_ 448 RFFuncReq 5;
BA_ "GenSigCycleTime" SG_ 448 RFFuncReq 200;
BA_ "FlexKomSigStartValue" SG_ 448 RFFuncReq "000000000000h";
BA_ "FlexKomSigStartPos" SG_ 448 RFFuncReq 7;
BA_ "FlexKomSigName" SG_ 448 RFFuncReq "RFHUB_A2_Pkt";
BA_ "FlexKomSigLaenge" SG_ 448 RFFuncReq 48;
BA_ "FlexKomSID" SG_ 448 RFFuncReq 1037;
BA_ "FlexKomIsMotorola" SG_ 448 RFFuncReq 1;
BA_ "FlexKomComment" SG_ 448 RFFuncReq "RFHUB_A2_Pkt";
BA_ "RID" SG_ 448 RFReq "1288";
BA_ "GenSigSNA" SG_ 448 RFReq "7h";
BA_ "GenSigSendType" SG_ 448 RFReq 5;
BA_ "GenSigCycleTime" SG_ 448 RFReq 200;
BA_ "FlexKomSigStartValue" SG_ 448 RFReq "000000000000h";
BA_ "FlexKomSigStartPos" SG_ 448 RFReq 7;
BA_ "FlexKomSigName" SG_ 448 RFReq "RFHUB_A2_Pkt";
BA_ "FlexKomSigLaenge" SG_ 448 RFReq 48;
BA_ "FlexKomSID" SG_ 448 RFReq 1037;
BA_ "FlexKomIsMotorola" SG_ 448 RFReq 1;
BA_ "FlexKomComment" SG_ 448 RFReq "RFHUB_A2_Pkt";
BA_ "RID" SG_ 448 RFCfgReq "1151";
BA_ "GenSigSNA" SG_ 448 RFCfgReq "7h";
BA_ "GenSigSendType" SG_ 448 RFCfgReq 5;
BA_ "GenSigCycleTime" SG_ 448 RFCfgReq 200;
BA_ "FlexKomSigStartValue" SG_ 448 RFCfgReq "000000000000h";
BA_ "FlexKomSigStartPos" SG_ 448 RFCfgReq 7;
BA_ "FlexKomSigName" SG_ 448 RFCfgReq "RFHUB_A2_Pkt";
BA_ "FlexKomSigLaenge" SG_ 448 RFCfgReq 48;
BA_ "FlexKomSID" SG_ 448 RFCfgReq 1037;
BA_ "FlexKomIsMotorola" SG_ 448 RFCfgReq 1;
BA_ "FlexKomComment" SG_ 448 RFCfgReq "RFHUB_A2_Pkt";
BA_ "RID" SG_ 448 RFFobNum "1157";
BA_ "GenSigSNA" SG_ 448 RFFobNum "Fh";
BA_ "GenSigSendType" SG_ 448 RFFobNum 5;
BA_ "GenSigCycleTime" SG_ 448 RFFobNum 200;
BA_ "FlexKomSigStartValue" SG_ 448 RFFobNum "000000000000h";
BA_ "FlexKomSigStartPos" SG_ 448 RFFobNum 7;
BA_ "FlexKomSigName" SG_ 448 RFFobNum "RFHUB_A2_Pkt";
BA_ "FlexKomSigLaenge" SG_ 448 RFFobNum 48;
BA_ "FlexKomSID" SG_ 448 RFFobNum 1037;
BA_ "FlexKomIsMotorola" SG_ 448 RFFobNum 1;
BA_ "FlexKomComment" SG_ 448 RFFobNum "RFHUB_A2_Pkt";
BA_ "RID" SG_ 448 PE_ENABLE "1166";
BA_ "GenSigTimeout_IC" SG_ 448 PE_ENABLE 2100;
BA_ "GenSigSNA" SG_ 448 PE_ENABLE "0h";
BA_ "GenSigSendType" SG_ 448 PE_ENABLE 5;
BA_ "GenSigCycleTime" SG_ 448 PE_ENABLE 200;
BA_ "FlexKomSigStartValue" SG_ 448 PE_ENABLE "000000000000h";
BA_ "FlexKomSigStartPos" SG_ 448 PE_ENABLE 7;
BA_ "FlexKomSigName" SG_ 448 PE_ENABLE "RFHUB_A2_Pkt";
BA_ "FlexKomSigLaenge" SG_ 448 PE_ENABLE 48;
BA_ "FlexKomSID" SG_ 448 PE_ENABLE 1037;
BA_ "FlexKomIsMotorola" SG_ 448 PE_ENABLE 1;
BA_ "FlexKomComment" SG_ 448 PE_ENABLE "RFHUB_A2_Pkt";
BA_ "GenSigTimeout_TBM" SG_ 456 VTA_STAT 5250;
BA_ "GenSigSNA" SG_ 456 VTA_STAT "7h";
BA_ "GenSigSendType" SG_ 456 VTA_STAT 5;
BA_ "GenSigCycleTime" SG_ 456 VTA_STAT 500;
BA_ "FlexKomSigStartValue" SG_ 456 VTA_STAT "00000000h";
BA_ "FlexKomSigStartPos" SG_ 456 VTA_STAT 7;
BA_ "FlexKomSigName" SG_ 456 VTA_STAT "VTA_PKT";
BA_ "FlexKomSigLaenge" SG_ 456 VTA_STAT 32;
BA_ "FlexKomSID" SG_ 456 VTA_STAT 1207;
BA_ "FlexKomIsMotorola" SG_ 456 VTA_STAT 1;
BA_ "FlexKomComment" SG_ 456 VTA_STAT "Vehicle theft alarm packet";
BA_ "GenSigTimeout_IC" SG_ 456 FOA_Msg_Req 1000;
BA_ "GenSigSNA" SG_ 456 FOA_Msg_Req "7h";
BA_ "GenSigSendType" SG_ 456 FOA_Msg_Req 5;
BA_ "GenSigCycleTime" SG_ 456 FOA_Msg_Req 500;
BA_ "FlexKomSigStartValue" SG_ 456 FOA_Msg_Req "00000000h";
BA_ "FlexKomSigStartPos" SG_ 456 FOA_Msg_Req 7;
BA_ "FlexKomSigName" SG_ 456 FOA_Msg_Req "VTA_PKT";
BA_ "FlexKomSigLaenge" SG_ 456 FOA_Msg_Req 32;
BA_ "FlexKomSID" SG_ 456 FOA_Msg_Req 1207;
BA_ "FlexKomIsMotorola" SG_ 456 FOA_Msg_Req 1;
BA_ "FlexKomComment" SG_ 456 FOA_Msg_Req "Vehicle theft alarm packet";
BA_ "GenSigSNA" SG_ 462 DrvPrsnSensorRawValSts "0h";
BA_ "GenSigCycleTime" SG_ 462 DrvPrsnSensorRawValSts 50;
BA_ "FlexKomSigStartValue" SG_ 462 DrvPrsnSensorRawValSts "000000FFh";
BA_ "FlexKomSigStartPos" SG_ 462 DrvPrsnSensorRawValSts 7;
BA_ "FlexKomSigName" SG_ 462 DrvPrsnSensorRawValSts "DPDM_A2_PKT";
BA_ "FlexKomSigLaenge" SG_ 462 DrvPrsnSensorRawValSts 32;
BA_ "FlexKomSID" SG_ 462 DrvPrsnSensorRawValSts 2683;
BA_ "FlexKomIsMotorola" SG_ 462 DrvPrsnSensorRawValSts 1;
BA_ "FlexKomComment" SG_ 462 DrvPrsnSensorRawValSts "DPDM_A2_PKT";
BA_ "GenSigSNA" SG_ 462 MC_DPDM_A2 "0h";
BA_ "GenSigCycleTime" SG_ 462 MC_DPDM_A2 50;
BA_ "FlexKomSigStartValue" SG_ 462 MC_DPDM_A2 "000000FFh";
BA_ "FlexKomSigStartPos" SG_ 462 MC_DPDM_A2 7;
BA_ "FlexKomSigName" SG_ 462 MC_DPDM_A2 "DPDM_A2_PKT";
BA_ "FlexKomSigLaenge" SG_ 462 MC_DPDM_A2 32;
BA_ "FlexKomSID" SG_ 462 MC_DPDM_A2 2683;
BA_ "FlexKomIsMotorola" SG_ 462 MC_DPDM_A2 1;
BA_ "FlexKomComment" SG_ 462 MC_DPDM_A2 "DPDM_A2_PKT";
BA_ "GenSigStartValue" SG_ 462 CRC_DPDM_A2 255;
BA_ "GenSigSNA" SG_ 462 CRC_DPDM_A2 "FFh";
BA_ "GenSigCycleTime" SG_ 462 CRC_DPDM_A2 50;
BA_ "FlexKomSigStartValue" SG_ 462 CRC_DPDM_A2 "000000FFh";
BA_ "FlexKomSigStartPos" SG_ 462 CRC_DPDM_A2 7;
BA_ "FlexKomSigName" SG_ 462 CRC_DPDM_A2 "DPDM_A2_PKT";
BA_ "FlexKomSigLaenge" SG_ 462 CRC_DPDM_A2 32;
BA_ "FlexKomSID" SG_ 462 CRC_DPDM_A2 2683;
BA_ "FlexKomIsMotorola" SG_ 462 CRC_DPDM_A2 1;
BA_ "FlexKomComment" SG_ 462 CRC_DPDM_A2 "DPDM_A2_PKT";
BA_ "GenSigSNA" SG_ 463 ControlEncodingRspESL "0h";
BA_ "GenSigSendType" SG_ 463 ControlEncodingRspESL 1;
BA_ "FlexKomSigStartValue" SG_ 463 ControlEncodingRspESL "0000000000h";
BA_ "FlexKomSigStartPos" SG_ 463 ControlEncodingRspESL 7;
BA_ "FlexKomSigName" SG_ 463 ControlEncodingRspESL "ESL_CodeRespPkt";
BA_ "FlexKomSigLaenge" SG_ 463 ControlEncodingRspESL 40;
BA_ "FlexKomSID" SG_ 463 ControlEncodingRspESL 2367;
BA_ "FlexKomIsMotorola" SG_ 463 ControlEncodingRspESL 1;
BA_ "FlexKomComment" SG_ 463 ControlEncodingRspESL "ESL code response packet";
BA_ "GenSigSNA" SG_ 463 MiniCryptGCodeESL "0h";
BA_ "GenSigSendType" SG_ 463 MiniCryptGCodeESL 1;
BA_ "FlexKomSigStartValue" SG_ 463 MiniCryptGCodeESL "0000000000h";
BA_ "FlexKomSigStartPos" SG_ 463 MiniCryptGCodeESL 7;
BA_ "FlexKomSigName" SG_ 463 MiniCryptGCodeESL "ESL_CodeRespPkt";
BA_ "FlexKomSigLaenge" SG_ 463 MiniCryptGCodeESL 40;
BA_ "FlexKomSID" SG_ 463 MiniCryptGCodeESL 2367;
BA_ "FlexKomIsMotorola" SG_ 463 MiniCryptGCodeESL 1;
BA_ "FlexKomComment" SG_ 463 MiniCryptGCodeESL "ESL code response packet";
BA_ "GenSigSNA" SG_ 463 CodeCheckStsESL "0h";
BA_ "GenSigSendType" SG_ 463 CodeCheckStsESL 1;
BA_ "FlexKomSigStartValue" SG_ 463 CodeCheckStsESL "0000000000h";
BA_ "FlexKomSigStartPos" SG_ 463 CodeCheckStsESL 7;
BA_ "FlexKomSigName" SG_ 463 CodeCheckStsESL "ESL_CodeRespPkt";
BA_ "FlexKomSigLaenge" SG_ 463 CodeCheckStsESL 40;
BA_ "FlexKomSID" SG_ 463 CodeCheckStsESL 2367;
BA_ "FlexKomIsMotorola" SG_ 463 CodeCheckStsESL 1;
BA_ "FlexKomComment" SG_ 463 CodeCheckStsESL "ESL code response packet";
BA_ "GenSigSNA" SG_ 463 ESLLockFailSts "0h";
BA_ "GenSigSendType" SG_ 463 ESLLockFailSts 1;
BA_ "FlexKomSigStartValue" SG_ 463 ESLLockFailSts "0000000000h";
BA_ "FlexKomSigStartPos" SG_ 463 ESLLockFailSts 7;
BA_ "FlexKomSigName" SG_ 463 ESLLockFailSts "ESL_CodeRespPkt";
BA_ "FlexKomSigLaenge" SG_ 463 ESLLockFailSts 40;
BA_ "FlexKomSID" SG_ 463 ESLLockFailSts 2367;
BA_ "FlexKomIsMotorola" SG_ 463 ESLLockFailSts 1;
BA_ "FlexKomComment" SG_ 463 ESLLockFailSts "ESL code response packet";
BA_ "GenSigSNA" SG_ 463 ESLUnlockFailSts "0h";
BA_ "GenSigSendType" SG_ 463 ESLUnlockFailSts 1;
BA_ "FlexKomSigStartValue" SG_ 463 ESLUnlockFailSts "0000000000h";
BA_ "FlexKomSigStartPos" SG_ 463 ESLUnlockFailSts 7;
BA_ "FlexKomSigName" SG_ 463 ESLUnlockFailSts "ESL_CodeRespPkt";
BA_ "FlexKomSigLaenge" SG_ 463 ESLUnlockFailSts 40;
BA_ "FlexKomSID" SG_ 463 ESLUnlockFailSts 2367;
BA_ "FlexKomIsMotorola" SG_ 463 ESLUnlockFailSts 1;
BA_ "FlexKomComment" SG_ 463 ESLUnlockFailSts "ESL code response packet";
BA_ "GenSigSNA" SG_ 463 ESL_ProgrammedSts "0h";
BA_ "GenSigSendType" SG_ 463 ESL_ProgrammedSts 1;
BA_ "FlexKomSigStartValue" SG_ 463 ESL_ProgrammedSts "0000000000h";
BA_ "FlexKomSigStartPos" SG_ 463 ESL_ProgrammedSts 7;
BA_ "FlexKomSigName" SG_ 463 ESL_ProgrammedSts "ESL_CodeRespPkt";
BA_ "FlexKomSigLaenge" SG_ 463 ESL_ProgrammedSts 40;
BA_ "FlexKomSID" SG_ 463 ESL_ProgrammedSts 2367;
BA_ "FlexKomIsMotorola" SG_ 463 ESL_ProgrammedSts 1;
BA_ "FlexKomComment" SG_ 463 ESL_ProgrammedSts "ESL code response packet";
BA_ "GenSigSNA" SG_ 463 ESLFeedbackCmd "7h";
BA_ "GenSigSendType" SG_ 463 ESLFeedbackCmd 1;
BA_ "FlexKomSigStartValue" SG_ 463 ESLFeedbackCmd "0000000000h";
BA_ "FlexKomSigStartPos" SG_ 463 ESLFeedbackCmd 7;
BA_ "FlexKomSigName" SG_ 463 ESLFeedbackCmd "ESL_CodeRespPkt";
BA_ "FlexKomSigLaenge" SG_ 463 ESLFeedbackCmd 40;
BA_ "FlexKomSID" SG_ 463 ESLFeedbackCmd 2367;
BA_ "FlexKomIsMotorola" SG_ 463 ESLFeedbackCmd 1;
BA_ "FlexKomComment" SG_ 463 ESLFeedbackCmd "ESL code response packet";
BA_ "RID" SG_ 464 ORC_A1_Tog "1970";
BA_ "GenSigSNA" SG_ 464 ORC_A1_Tog "0h";
BA_ "GenSigSendType" SG_ 464 ORC_A1_Tog 5;
BA_ "GenSigCycleTime" SG_ 464 ORC_A1_Tog 1000;
BA_ "FlexKomSigStartValue" SG_ 464 ORC_A1_Tog "00h";
BA_ "FlexKomSigStartPos" SG_ 464 ORC_A1_Tog 1;
BA_ "FlexKomSigName" SG_ 464 ORC_A1_Tog "ORC_A1_Tog";
BA_ "FlexKomSigLaenge" SG_ 464 ORC_A1_Tog 1;
BA_ "FlexKomSID" SG_ 464 ORC_A1_Tog 1902;
BA_ "FlexKomIsMotorola" SG_ 464 ORC_A1_Tog 1;
BA_ "FlexKomComment" SG_ 464 ORC_A1_Tog "ORC_A1 toggle bit";
BA_ "RID" SG_ 464 SRS_IndLmp_Rq "1152 6546";
BA_ "GenSigTimeout_TBM" SG_ 464 SRS_IndLmp_Rq 10500;
BA_ "GenSigTimeout_IC" SG_ 464 SRS_IndLmp_Rq 10500;
BA_ "GenSigTimeout_ETM" SG_ 464 SRS_IndLmp_Rq 10500;
BA_ "GenSigTimeout_CBC" SG_ 464 SRS_IndLmp_Rq 5500;
BA_ "GenSigStartValue" SG_ 464 SRS_IndLmp_Rq 1;
BA_ "GenSigSNA" SG_ 464 SRS_IndLmp_Rq "3h";
BA_ "GenSigSendType" SG_ 464 SRS_IndLmp_Rq 5;
BA_ "GenSigCycleTime" SG_ 464 SRS_IndLmp_Rq 1000;
BA_ "FlexKomSigStartValue" SG_ 464 SRS_IndLmp_Rq "01h";
BA_ "FlexKomSigStartPos" SG_ 464 SRS_IndLmp_Rq 3;
BA_ "FlexKomSigName" SG_ 464 SRS_IndLmp_Rq "SRS_IndLmp_Rq";
BA_ "FlexKomSigLaenge" SG_ 464 SRS_IndLmp_Rq 2;
BA_ "FlexKomSID" SG_ 464 SRS_IndLmp_Rq 329;
BA_ "FlexKomIsMotorola" SG_ 464 SRS_IndLmp_Rq 1;
BA_ "FlexKomComment" SG_ 464 SRS_IndLmp_Rq "SRS indication lamp request";
BA_ "RID" SG_ 464 ORC_A1_Par "1961";
BA_ "GenSigSNA" SG_ 464 ORC_A1_Par "0h";
BA_ "GenSigSendType" SG_ 464 ORC_A1_Par 5;
BA_ "GenSigCycleTime" SG_ 464 ORC_A1_Par 1000;
BA_ "FlexKomSigStartValue" SG_ 464 ORC_A1_Par "00h";
BA_ "FlexKomSigStartPos" SG_ 464 ORC_A1_Par 7;
BA_ "FlexKomSigName" SG_ 464 ORC_A1_Par "ORC_A1_Par";
BA_ "FlexKomSigLaenge" SG_ 464 ORC_A1_Par 1;
BA_ "FlexKomSID" SG_ 464 ORC_A1_Par 1903;
BA_ "FlexKomIsMotorola" SG_ 464 ORC_A1_Par 1;
BA_ "FlexKomComment" SG_ 464 ORC_A1_Par "ORC_A1 even parity bit";
BA_ "RID" SG_ 464 DrvSbltUnFltr "1973";
BA_ "GenSigStartValue" SG_ 464 DrvSbltUnFltr 7;
BA_ "GenSigSNA" SG_ 464 DrvSbltUnFltr "7h";
BA_ "GenSigSendType" SG_ 464 DrvSbltUnFltr 5;
BA_ "GenSigCycleTime" SG_ 464 DrvSbltUnFltr 1000;
BA_ "FlexKomSigStartValue" SG_ 464 DrvSbltUnFltr "07h";
BA_ "FlexKomSigStartPos" SG_ 464 DrvSbltUnFltr 15;
BA_ "FlexKomSigName" SG_ 464 DrvSbltUnFltr "DrvSbltUnFltr";
BA_ "FlexKomSigLaenge" SG_ 464 DrvSbltUnFltr 3;
BA_ "FlexKomSID" SG_ 464 DrvSbltUnFltr 1814;
BA_ "FlexKomIsMotorola" SG_ 464 DrvSbltUnFltr 1;
BA_ "FlexKomComment" SG_ 464 DrvSbltUnFltr "Drivers seat belt fault status - unfiltered";
BA_ "RID" SG_ 464 DRV_SEATBELT "1107";
BA_ "GenSigTimeout_TBM" SG_ 464 DRV_SEATBELT 10500;
BA_ "GenSigTimeout_PTS" SG_ 464 DRV_SEATBELT 10500;
BA_ "GenSigTimeout_IC" SG_ 464 DRV_SEATBELT 10500;
BA_ "GenSigTimeout_ETM" SG_ 464 DRV_SEATBELT 10500;
BA_ "GenSigTimeout_CBC" SG_ 464 DRV_SEATBELT 10500;
BA_ "GenSigStartValue" SG_ 464 DRV_SEATBELT 3;
BA_ "GenSigSNA" SG_ 464 DRV_SEATBELT "3h";
BA_ "GenSigSendType" SG_ 464 DRV_SEATBELT 5;
BA_ "GenSigCycleTime" SG_ 464 DRV_SEATBELT 1000;
BA_ "FlexKomSigStartValue" SG_ 464 DRV_SEATBELT "03h";
BA_ "FlexKomSigStartPos" SG_ 464 DRV_SEATBELT 17;
BA_ "FlexKomSigName" SG_ 464 DRV_SEATBELT "DRV_SEATBELT";
BA_ "FlexKomSigLaenge" SG_ 464 DRV_SEATBELT 2;
BA_ "FlexKomSID" SG_ 464 DRV_SEATBELT 330;
BA_ "FlexKomIsMotorola" SG_ 464 DRV_SEATBELT 1;
BA_ "FlexKomComment" SG_ 464 DRV_SEATBELT "Drivers seat belt status";
BA_ "RID" SG_ 464 PSG_SEATBELT "1160";
BA_ "GenSigTimeout_TBM" SG_ 464 PSG_SEATBELT 10500;
BA_ "GenSigTimeout_IC" SG_ 464 PSG_SEATBELT 10500;
BA_ "GenSigTimeout_ETM" SG_ 464 PSG_SEATBELT 10500;
BA_ "GenSigTimeout_CBC" SG_ 464 PSG_SEATBELT 10500;
BA_ "GenSigStartValue" SG_ 464 PSG_SEATBELT 3;
BA_ "GenSigSNA" SG_ 464 PSG_SEATBELT "3h";
BA_ "GenSigSendType" SG_ 464 PSG_SEATBELT 5;
BA_ "GenSigCycleTime" SG_ 464 PSG_SEATBELT 1000;
BA_ "FlexKomSigStartValue" SG_ 464 PSG_SEATBELT "03h";
BA_ "FlexKomSigStartPos" SG_ 464 PSG_SEATBELT 19;
BA_ "FlexKomSigName" SG_ 464 PSG_SEATBELT "PSG_SEATBELT";
BA_ "FlexKomSigLaenge" SG_ 464 PSG_SEATBELT 2;
BA_ "FlexKomSID" SG_ 464 PSG_SEATBELT 331;
BA_ "FlexKomIsMotorola" SG_ 464 PSG_SEATBELT 1;
BA_ "FlexKomComment" SG_ 464 PSG_SEATBELT "Passengers seat belt status";
BA_ "RID" SG_ 464 SBRDriverSeatConfigSts "1977";
BA_ "GenSigTimeout_IC" SG_ 464 SBRDriverSeatConfigSts 10500;
BA_ "GenSigSNA" SG_ 464 SBRDriverSeatConfigSts "0h";
BA_ "GenSigSendType" SG_ 464 SBRDriverSeatConfigSts 5;
BA_ "GenSigCycleTime" SG_ 464 SBRDriverSeatConfigSts 1000;
BA_ "FlexKomSigStartValue" SG_ 464 SBRDriverSeatConfigSts "00h";
BA_ "FlexKomSigStartPos" SG_ 464 SBRDriverSeatConfigSts 20;
BA_ "FlexKomSigName" SG_ 464 SBRDriverSeatConfigSts "SBRDriverSeatConfigSts";
BA_ "FlexKomSigLaenge" SG_ 464 SBRDriverSeatConfigSts 1;
BA_ "FlexKomSID" SG_ 464 SBRDriverSeatConfigSts 1967;
BA_ "FlexKomIsMotorola" SG_ 464 SBRDriverSeatConfigSts 1;
BA_ "FlexKomComment" SG_ 464 SBRDriverSeatConfigSts "Driver seatbelt switch configuration; seat checked";
BA_ "RID" SG_ 464 SBRFtPsngrSeatConfigSts "1962";
BA_ "GenSigTimeout_IC" SG_ 464 SBRFtPsngrSeatConfigSts 10500;
BA_ "GenSigSNA" SG_ 464 SBRFtPsngrSeatConfigSts "0h";
BA_ "GenSigSendType" SG_ 464 SBRFtPsngrSeatConfigSts 5;
BA_ "GenSigCycleTime" SG_ 464 SBRFtPsngrSeatConfigSts 1000;
BA_ "FlexKomSigStartValue" SG_ 464 SBRFtPsngrSeatConfigSts "00h";
BA_ "FlexKomSigStartPos" SG_ 464 SBRFtPsngrSeatConfigSts 21;
BA_ "FlexKomSigName" SG_ 464 SBRFtPsngrSeatConfigSts "SBRFtPsngrSeatConfigSts";
BA_ "FlexKomSigLaenge" SG_ 464 SBRFtPsngrSeatConfigSts 1;
BA_ "FlexKomSID" SG_ 464 SBRFtPsngrSeatConfigSts 1966;
BA_ "FlexKomIsMotorola" SG_ 464 SBRFtPsngrSeatConfigSts 1;
BA_ "FlexKomComment" SG_ 464 SBRFtPsngrSeatConfigSts "Front passenger seatbelt switch configuration; sea";
BA_ "RID" SG_ 464 PsngrBagChargeSts "5076";
BA_ "GenSigTimeout_IC" SG_ 464 PsngrBagChargeSts 10500;
BA_ "GenSigSNA" SG_ 464 PsngrBagChargeSts "3h";
BA_ "GenSigSendType" SG_ 464 PsngrBagChargeSts 5;
BA_ "GenSigCycleTime" SG_ 464 PsngrBagChargeSts 1000;
BA_ "FlexKomSigStartValue" SG_ 464 PsngrBagChargeSts "00h";
BA_ "FlexKomSigStartPos" SG_ 464 PsngrBagChargeSts 23;
BA_ "FlexKomSigName" SG_ 464 PsngrBagChargeSts "PsngrBagChargeSts";
BA_ "FlexKomSigLaenge" SG_ 464 PsngrBagChargeSts 2;
BA_ "FlexKomSID" SG_ 464 PsngrBagChargeSts 2642;
BA_ "FlexKomIsMotorola" SG_ 464 PsngrBagChargeSts 1;
BA_ "FlexKomComment" SG_ 464 PsngrBagChargeSts "Passenger airbag charge status";
BA_ "RID" SG_ 464 PSG_ODS_STAT "1142";
BA_ "GenSigTimeout_IC" SG_ 464 PSG_ODS_STAT 10500;
BA_ "GenSigTimeout_ETM" SG_ 464 PSG_ODS_STAT 10500;
BA_ "GenSigTimeout_CBC" SG_ 464 PSG_ODS_STAT 10500;
BA_ "GenSigStartValue" SG_ 464 PSG_ODS_STAT 3;
BA_ "GenSigSNA" SG_ 464 PSG_ODS_STAT "3h";
BA_ "GenSigSendType" SG_ 464 PSG_ODS_STAT 5;
BA_ "GenSigCycleTime" SG_ 464 PSG_ODS_STAT 1000;
BA_ "FlexKomSigStartValue" SG_ 464 PSG_ODS_STAT "03h";
BA_ "FlexKomSigStartPos" SG_ 464 PSG_ODS_STAT 27;
BA_ "FlexKomSigName" SG_ 464 PSG_ODS_STAT "PSG_ODS_STAT";
BA_ "FlexKomSigLaenge" SG_ 464 PSG_ODS_STAT 2;
BA_ "FlexKomSID" SG_ 464 PSG_ODS_STAT 426;
BA_ "FlexKomIsMotorola" SG_ 464 PSG_ODS_STAT 1;
BA_ "FlexKomComment" SG_ 464 PSG_ODS_STAT "Passenger Occupant Detection Sensor Status";
BA_ "RID" SG_ 466 IMPACT_B "1278";
BA_ "GenSigSNA" SG_ 466 IMPACT_B "0h";
BA_ "GenSigSendType" SG_ 466 IMPACT_B 2;
BA_ "GenSigCycleTimeActive" SG_ 466 IMPACT_B 20;
BA_ "FlexKomSigStartValue" SG_ 466 IMPACT_B "0000h";
BA_ "FlexKomSigStartPos" SG_ 466 IMPACT_B 7;
BA_ "FlexKomSigName" SG_ 466 IMPACT_B "IMPACT";
BA_ "FlexKomSigLaenge" SG_ 466 IMPACT_B 16;
BA_ "FlexKomSID" SG_ 466 IMPACT_B 325;
BA_ "FlexKomIsMotorola" SG_ 466 IMPACT_B 1;
BA_ "FlexKomComment" SG_ 466 IMPACT_B "Impact events";
BA_ "RID" SG_ 466 IMPACT_C "1032";
BA_ "GenSigSNA" SG_ 466 IMPACT_C "0h";
BA_ "GenSigSendType" SG_ 466 IMPACT_C 2;
BA_ "GenSigCycleTimeActive" SG_ 466 IMPACT_C 20;
BA_ "FlexKomSigStartValue" SG_ 466 IMPACT_C "0000h";
BA_ "FlexKomSigStartPos" SG_ 466 IMPACT_C 7;
BA_ "FlexKomSigName" SG_ 466 IMPACT_C "IMPACT";
BA_ "FlexKomSigLaenge" SG_ 466 IMPACT_C 16;
BA_ "FlexKomSID" SG_ 466 IMPACT_C 325;
BA_ "FlexKomIsMotorola" SG_ 466 IMPACT_C 1;
BA_ "FlexKomComment" SG_ 466 IMPACT_C "Impact events";
BA_ "RID" SG_ 466 Impact_F "1249";
BA_ "GenSigSNA" SG_ 466 Impact_F "0h";
BA_ "GenSigSendType" SG_ 466 Impact_F 2;
BA_ "GenSigCycleTimeActive" SG_ 466 Impact_F 20;
BA_ "FlexKomSigStartValue" SG_ 466 Impact_F "0000h";
BA_ "FlexKomSigStartPos" SG_ 466 Impact_F 7;
BA_ "FlexKomSigName" SG_ 466 Impact_F "IMPACT";
BA_ "FlexKomSigLaenge" SG_ 466 Impact_F 16;
BA_ "FlexKomSID" SG_ 466 Impact_F 325;
BA_ "FlexKomIsMotorola" SG_ 466 Impact_F 1;
BA_ "FlexKomComment" SG_ 466 Impact_F "Impact events";
BA_ "RID" SG_ 466 Impact_Tgl "1060 2149";
BA_ "GenSigSNA" SG_ 466 Impact_Tgl "0h";
BA_ "GenSigSendType" SG_ 466 Impact_Tgl 2;
BA_ "GenSigCycleTimeActive" SG_ 466 Impact_Tgl 20;
BA_ "FlexKomSigStartValue" SG_ 466 Impact_Tgl "0000h";
BA_ "FlexKomSigStartPos" SG_ 466 Impact_Tgl 7;
BA_ "FlexKomSigName" SG_ 466 Impact_Tgl "IMPACT";
BA_ "FlexKomSigLaenge" SG_ 466 Impact_Tgl 16;
BA_ "FlexKomSID" SG_ 466 Impact_Tgl 325;
BA_ "FlexKomIsMotorola" SG_ 466 Impact_Tgl 1;
BA_ "FlexKomComment" SG_ 466 Impact_Tgl "Impact events";
BA_ "RID" SG_ 466 IMPACT_I "1034";
BA_ "GenSigSNA" SG_ 466 IMPACT_I "0h";
BA_ "GenSigSendType" SG_ 466 IMPACT_I 2;
BA_ "GenSigCycleTimeActive" SG_ 466 IMPACT_I 20;
BA_ "FlexKomSigStartValue" SG_ 466 IMPACT_I "0000h";
BA_ "FlexKomSigStartPos" SG_ 466 IMPACT_I 7;
BA_ "FlexKomSigName" SG_ 466 IMPACT_I "IMPACT";
BA_ "FlexKomSigLaenge" SG_ 466 IMPACT_I 16;
BA_ "FlexKomSID" SG_ 466 IMPACT_I 325;
BA_ "FlexKomIsMotorola" SG_ 466 IMPACT_I 1;
BA_ "FlexKomComment" SG_ 466 IMPACT_I "Impact events";
BA_ "RID" SG_ 466 IMPACT_K "1031";
BA_ "GenSigSNA" SG_ 466 IMPACT_K "0h";
BA_ "GenSigSendType" SG_ 466 IMPACT_K 2;
BA_ "GenSigCycleTimeActive" SG_ 466 IMPACT_K 20;
BA_ "FlexKomSigStartValue" SG_ 466 IMPACT_K "0000h";
BA_ "FlexKomSigStartPos" SG_ 466 IMPACT_K 7;
BA_ "FlexKomSigName" SG_ 466 IMPACT_K "IMPACT";
BA_ "FlexKomSigLaenge" SG_ 466 IMPACT_K 16;
BA_ "FlexKomSID" SG_ 466 IMPACT_K 325;
BA_ "FlexKomIsMotorola" SG_ 466 IMPACT_K 1;
BA_ "FlexKomComment" SG_ 466 IMPACT_K "Impact events";
BA_ "RID" SG_ 466 IMPACT_M "1229";
BA_ "GenSigSNA" SG_ 466 IMPACT_M "0h";
BA_ "GenSigSendType" SG_ 466 IMPACT_M 2;
BA_ "GenSigCycleTimeActive" SG_ 466 IMPACT_M 20;
BA_ "FlexKomSigStartValue" SG_ 466 IMPACT_M "0000h";
BA_ "FlexKomSigStartPos" SG_ 466 IMPACT_M 7;
BA_ "FlexKomSigName" SG_ 466 IMPACT_M "IMPACT";
BA_ "FlexKomSigLaenge" SG_ 466 IMPACT_M 16;
BA_ "FlexKomSID" SG_ 466 IMPACT_M 325;
BA_ "FlexKomIsMotorola" SG_ 466 IMPACT_M 1;
BA_ "FlexKomComment" SG_ 466 IMPACT_M "Impact events";
BA_ "RID" SG_ 466 IMPACT_X "1273 2130";
BA_ "GenSigSNA" SG_ 466 IMPACT_X "0h";
BA_ "GenSigSendType" SG_ 466 IMPACT_X 2;
BA_ "GenSigCycleTimeActive" SG_ 466 IMPACT_X 20;
BA_ "FlexKomSigStartValue" SG_ 466 IMPACT_X "0000h";
BA_ "FlexKomSigStartPos" SG_ 466 IMPACT_X 7;
BA_ "FlexKomSigName" SG_ 466 IMPACT_X "IMPACT";
BA_ "FlexKomSigLaenge" SG_ 466 IMPACT_X 16;
BA_ "FlexKomSID" SG_ 466 IMPACT_X 325;
BA_ "FlexKomIsMotorola" SG_ 466 IMPACT_X 1;
BA_ "FlexKomComment" SG_ 466 IMPACT_X "Impact events";
BA_ "GenSigSNA" SG_ 469 ORC_Health "0h";
BA_ "GenSigSendType" SG_ 469 ORC_Health 5;
BA_ "GenSigCycleTime" SG_ 469 ORC_Health 250;
BA_ "FlexKomSigStartValue" SG_ 469 ORC_Health "0000000000000000h";
BA_ "FlexKomSigStartPos" SG_ 469 ORC_Health 7;
BA_ "FlexKomSigName" SG_ 469 ORC_Health "ORC_A4_Pkt";
BA_ "FlexKomSigLaenge" SG_ 469 ORC_Health 64;
BA_ "FlexKomSID" SG_ 469 ORC_Health 2442;
BA_ "FlexKomIsMotorola" SG_ 469 ORC_Health 1;
BA_ "FlexKomComment" SG_ 469 ORC_Health "ORC A4 packet";
BA_ "GenSigTimeout_IC" SG_ 489 PTS_PopUpRqst 5250;
BA_ "GenSigSNA" SG_ 489 PTS_PopUpRqst "FFh";
BA_ "GenSigSendType" SG_ 489 PTS_PopUpRqst 5;
BA_ "GenSigCycleTime" SG_ 489 PTS_PopUpRqst 500;
BA_ "FlexKomSigStartValue" SG_ 489 PTS_PopUpRqst "FF001400000004FFh";
BA_ "FlexKomSigStartPos" SG_ 489 PTS_PopUpRqst 7;
BA_ "FlexKomSigName" SG_ 489 PTS_PopUpRqst "PTS_2_Pkt";
BA_ "FlexKomSigLaenge" SG_ 489 PTS_PopUpRqst 64;
BA_ "FlexKomSID" SG_ 489 PTS_PopUpRqst 1954;
BA_ "FlexKomIsMotorola" SG_ 489 PTS_PopUpRqst 1;
BA_ "FlexKomComment" SG_ 489 PTS_PopUpRqst "PTS 2 message packet";
BA_ "GenSigTimeout_IC" SG_ 489 PTS_Off_Status 5250;
BA_ "GenSigSNA" SG_ 489 PTS_Off_Status "0h";
BA_ "GenSigSendType" SG_ 489 PTS_Off_Status 5;
BA_ "GenSigCycleTime" SG_ 489 PTS_Off_Status 500;
BA_ "FlexKomSigStartValue" SG_ 489 PTS_Off_Status "FF001400000004FFh";
BA_ "FlexKomSigStartPos" SG_ 489 PTS_Off_Status 7;
BA_ "FlexKomSigName" SG_ 489 PTS_Off_Status "PTS_2_Pkt";
BA_ "FlexKomSigLaenge" SG_ 489 PTS_Off_Status 64;
BA_ "FlexKomSID" SG_ 489 PTS_Off_Status 1954;
BA_ "FlexKomIsMotorola" SG_ 489 PTS_Off_Status 1;
BA_ "FlexKomComment" SG_ 489 PTS_Off_Status "PTS 2 message packet";
BA_ "GenSigTimeout_IC" SG_ 489 PTS_FT_TEMP_NA 5250;
BA_ "GenSigSNA" SG_ 489 PTS_FT_TEMP_NA "0h";
BA_ "GenSigSendType" SG_ 489 PTS_FT_TEMP_NA 5;
BA_ "GenSigCycleTime" SG_ 489 PTS_FT_TEMP_NA 500;
BA_ "FlexKomSigStartValue" SG_ 489 PTS_FT_TEMP_NA "FF001400000004FFh";
BA_ "FlexKomSigStartPos" SG_ 489 PTS_FT_TEMP_NA 7;
BA_ "FlexKomSigName" SG_ 489 PTS_FT_TEMP_NA "PTS_2_Pkt";
BA_ "FlexKomSigLaenge" SG_ 489 PTS_FT_TEMP_NA 64;
BA_ "FlexKomSID" SG_ 489 PTS_FT_TEMP_NA 1954;
BA_ "FlexKomIsMotorola" SG_ 489 PTS_FT_TEMP_NA 1;
BA_ "FlexKomComment" SG_ 489 PTS_FT_TEMP_NA "PTS 2 message packet";
BA_ "GenSigTimeout_IC" SG_ 489 PTS_RR_TEMP_NA 5250;
BA_ "GenSigSNA" SG_ 489 PTS_RR_TEMP_NA "0h";
BA_ "GenSigSendType" SG_ 489 PTS_RR_TEMP_NA 5;
BA_ "GenSigCycleTime" SG_ 489 PTS_RR_TEMP_NA 500;
BA_ "FlexKomSigStartValue" SG_ 489 PTS_RR_TEMP_NA "FF001400000004FFh";
BA_ "FlexKomSigStartPos" SG_ 489 PTS_RR_TEMP_NA 7;
BA_ "FlexKomSigName" SG_ 489 PTS_RR_TEMP_NA "PTS_2_Pkt";
BA_ "FlexKomSigLaenge" SG_ 489 PTS_RR_TEMP_NA 64;
BA_ "FlexKomSID" SG_ 489 PTS_RR_TEMP_NA 1954;
BA_ "FlexKomIsMotorola" SG_ 489 PTS_RR_TEMP_NA 1;
BA_ "FlexKomComment" SG_ 489 PTS_RR_TEMP_NA "PTS 2 message packet";
BA_ "GenSigTimeout_IC" SG_ 491 PTS_DBD 5250;
BA_ "GenSigSNA" SG_ 491 PTS_DBD "0h";
BA_ "GenSigSendType" SG_ 491 PTS_DBD 5;
BA_ "GenSigCycleTime" SG_ 491 PTS_DBD 500;
BA_ "FlexKomSigStartValue" SG_ 491 PTS_DBD "00h";
BA_ "FlexKomSigStartPos" SG_ 491 PTS_DBD 16;
BA_ "FlexKomSigName" SG_ 491 PTS_DBD "PTS_DBD";
BA_ "FlexKomSigLaenge" SG_ 491 PTS_DBD 1;
BA_ "FlexKomSID" SG_ 491 PTS_DBD 1949;
BA_ "FlexKomIsMotorola" SG_ 491 PTS_DBD 1;
BA_ "FlexKomComment" SG_ 491 PTS_DBD "Park assist system disabled; System_Disabled = [1]";
BA_ "RID" SG_ 502 PTS_CFG_STAT "1181";
BA_ "GenSigTimeout_IC" SG_ 502 PTS_CFG_STAT 5250;
BA_ "GenSigTimeout_CBC" SG_ 502 PTS_CFG_STAT 5250;
BA_ "GenSigSNA" SG_ 502 PTS_CFG_STAT "3h";
BA_ "GenSigSendType" SG_ 502 PTS_CFG_STAT 5;
BA_ "GenSigCycleTime" SG_ 502 PTS_CFG_STAT 500;
BA_ "FlexKomSigStartValue" SG_ 502 PTS_CFG_STAT "00h";
BA_ "FlexKomSigStartPos" SG_ 502 PTS_CFG_STAT 2;
BA_ "FlexKomSigName" SG_ 502 PTS_CFG_STAT "PTS_CFG_STAT";
BA_ "FlexKomSigLaenge" SG_ 502 PTS_CFG_STAT 2;
BA_ "FlexKomSID" SG_ 502 PTS_CFG_STAT 1114;
BA_ "FlexKomIsMotorola" SG_ 502 PTS_CFG_STAT 1;
BA_ "FlexKomComment" SG_ 502 PTS_CFG_STAT "Park assist configuration status";
BA_ "GenSigTimeout_IC" SG_ 502 PTS_FT_NA 5250;
BA_ "GenSigSNA" SG_ 502 PTS_FT_NA "0h";
BA_ "GenSigSendType" SG_ 502 PTS_FT_NA 5;
BA_ "GenSigCycleTime" SG_ 502 PTS_FT_NA 500;
BA_ "FlexKomSigStartValue" SG_ 502 PTS_FT_NA "00h";
BA_ "FlexKomSigStartPos" SG_ 502 PTS_FT_NA 3;
BA_ "FlexKomSigName" SG_ 502 PTS_FT_NA "PTS_FT_NA";
BA_ "FlexKomSigLaenge" SG_ 502 PTS_FT_NA 1;
BA_ "FlexKomSID" SG_ 502 PTS_FT_NA 1314;
BA_ "FlexKomIsMotorola" SG_ 502 PTS_FT_NA 1;
BA_ "FlexKomComment" SG_ 502 PTS_FT_NA "Front park assist not available - blinded sensor; ";
BA_ "GenSigTimeout_IC" SG_ 502 PTS_RR_NA 5250;
BA_ "GenSigSNA" SG_ 502 PTS_RR_NA "0h";
BA_ "GenSigSendType" SG_ 502 PTS_RR_NA 5;
BA_ "GenSigCycleTime" SG_ 502 PTS_RR_NA 500;
BA_ "FlexKomSigStartValue" SG_ 502 PTS_RR_NA "00h";
BA_ "FlexKomSigStartPos" SG_ 502 PTS_RR_NA 4;
BA_ "FlexKomSigName" SG_ 502 PTS_RR_NA "PTS_RR_NA";
BA_ "FlexKomSigLaenge" SG_ 502 PTS_RR_NA 1;
BA_ "FlexKomSID" SG_ 502 PTS_RR_NA 1315;
BA_ "FlexKomIsMotorola" SG_ 502 PTS_RR_NA 1;
BA_ "FlexKomComment" SG_ 502 PTS_RR_NA "Rear park assist not available - blinded sensor; T";
BA_ "GenSigTimeout_IC" SG_ 502 PTS_SRV_RQ 5250;
BA_ "GenSigSNA" SG_ 502 PTS_SRV_RQ "0h";
BA_ "GenSigSendType" SG_ 502 PTS_SRV_RQ 5;
BA_ "GenSigCycleTime" SG_ 502 PTS_SRV_RQ 500;
BA_ "FlexKomSigStartValue" SG_ 502 PTS_SRV_RQ "00h";
BA_ "FlexKomSigStartPos" SG_ 502 PTS_SRV_RQ 5;
BA_ "FlexKomSigName" SG_ 502 PTS_SRV_RQ "PTS_SRV_RQ";
BA_ "FlexKomSigLaenge" SG_ 502 PTS_SRV_RQ 1;
BA_ "FlexKomSID" SG_ 502 PTS_SRV_RQ 54;
BA_ "FlexKomIsMotorola" SG_ 502 PTS_SRV_RQ 1;
BA_ "FlexKomComment" SG_ 502 PTS_SRV_RQ "PTS service warning request; True = [1]";
BA_ "RID" SG_ 502 PTS_AlrFL "2104";
BA_ "GenSigTimeout_IC" SG_ 502 PTS_AlrFL 5250;
BA_ "GenSigTimeout_CBC" SG_ 502 PTS_AlrFL 5250;
BA_ "GenSigSNA" SG_ 502 PTS_AlrFL "Fh";
BA_ "GenSigSendType" SG_ 502 PTS_AlrFL 5;
BA_ "GenSigCycleTime" SG_ 502 PTS_AlrFL 500;
BA_ "FlexKomSigStartValue" SG_ 502 PTS_AlrFL "F0h";
BA_ "FlexKomSigStartPos" SG_ 502 PTS_AlrFL 15;
BA_ "FlexKomSigName" SG_ 502 PTS_AlrFL "PTS_FL";
BA_ "FlexKomSigLaenge" SG_ 502 PTS_AlrFL 8;
BA_ "FlexKomSID" SG_ 502 PTS_AlrFL 1117;
BA_ "FlexKomIsMotorola" SG_ 502 PTS_AlrFL 1;
BA_ "FlexKomComment" SG_ 502 PTS_AlrFL "Park assist front left warnings";
BA_ "GenSigTimeout_IC" SG_ 502 PTS_GraphicFL 5250;
BA_ "GenSigStartValue" SG_ 502 PTS_GraphicFL 3;
BA_ "GenSigSNA" SG_ 502 PTS_GraphicFL "3h";
BA_ "GenSigSendType" SG_ 502 PTS_GraphicFL 5;
BA_ "GenSigCycleTime" SG_ 502 PTS_GraphicFL 500;
BA_ "FlexKomSigStartValue" SG_ 502 PTS_GraphicFL "F0h";
BA_ "FlexKomSigStartPos" SG_ 502 PTS_GraphicFL 15;
BA_ "FlexKomSigName" SG_ 502 PTS_GraphicFL "PTS_FL";
BA_ "FlexKomSigLaenge" SG_ 502 PTS_GraphicFL 8;
BA_ "FlexKomSID" SG_ 502 PTS_GraphicFL 1117;
BA_ "FlexKomIsMotorola" SG_ 502 PTS_GraphicFL 1;
BA_ "FlexKomComment" SG_ 502 PTS_GraphicFL "Park assist front left warnings";
BA_ "RID" SG_ 502 PTS_AlrFR "2100";
BA_ "GenSigTimeout_IC" SG_ 502 PTS_AlrFR 5250;
BA_ "GenSigTimeout_CBC" SG_ 502 PTS_AlrFR 5250;
BA_ "GenSigSNA" SG_ 502 PTS_AlrFR "Fh";
BA_ "GenSigSendType" SG_ 502 PTS_AlrFR 5;
BA_ "GenSigCycleTime" SG_ 502 PTS_AlrFR 500;
BA_ "FlexKomSigStartValue" SG_ 502 PTS_AlrFR "F0h";
BA_ "FlexKomSigStartPos" SG_ 502 PTS_AlrFR 23;
BA_ "FlexKomSigName" SG_ 502 PTS_AlrFR "PTS_FR";
BA_ "FlexKomSigLaenge" SG_ 502 PTS_AlrFR 8;
BA_ "FlexKomSID" SG_ 502 PTS_AlrFR 1118;
BA_ "FlexKomIsMotorola" SG_ 502 PTS_AlrFR 1;
BA_ "FlexKomComment" SG_ 502 PTS_AlrFR "Park assist front right warnings";
BA_ "GenSigTimeout_IC" SG_ 502 PTS_GraphicFR 5250;
BA_ "GenSigStartValue" SG_ 502 PTS_GraphicFR 3;
BA_ "GenSigSNA" SG_ 502 PTS_GraphicFR "3h";
BA_ "GenSigSendType" SG_ 502 PTS_GraphicFR 5;
BA_ "GenSigCycleTime" SG_ 502 PTS_GraphicFR 500;
BA_ "FlexKomSigStartValue" SG_ 502 PTS_GraphicFR "F0h";
BA_ "FlexKomSigStartPos" SG_ 502 PTS_GraphicFR 23;
BA_ "FlexKomSigName" SG_ 502 PTS_GraphicFR "PTS_FR";
BA_ "FlexKomSigLaenge" SG_ 502 PTS_GraphicFR 8;
BA_ "FlexKomSID" SG_ 502 PTS_GraphicFR 1118;
BA_ "FlexKomIsMotorola" SG_ 502 PTS_GraphicFR 1;
BA_ "FlexKomComment" SG_ 502 PTS_GraphicFR "Park assist front right warnings";
BA_ "RID" SG_ 502 PTS_AlrRL "1009 2101";
BA_ "GenSigTimeout_IC" SG_ 502 PTS_AlrRL 5250;
BA_ "GenSigTimeout_CBC" SG_ 502 PTS_AlrRL 5250;
BA_ "GenSigSNA" SG_ 502 PTS_AlrRL "Fh";
BA_ "GenSigSendType" SG_ 502 PTS_AlrRL 5;
BA_ "GenSigCycleTime" SG_ 502 PTS_AlrRL 500;
BA_ "FlexKomSigStartValue" SG_ 502 PTS_AlrRL "F0h";
BA_ "FlexKomSigStartPos" SG_ 502 PTS_AlrRL 31;
BA_ "FlexKomSigName" SG_ 502 PTS_AlrRL "PTS_RL";
BA_ "FlexKomSigLaenge" SG_ 502 PTS_AlrRL 8;
BA_ "FlexKomSID" SG_ 502 PTS_AlrRL 1119;
BA_ "FlexKomIsMotorola" SG_ 502 PTS_AlrRL 1;
BA_ "FlexKomComment" SG_ 502 PTS_AlrRL "Park assist rear left warnings";
BA_ "GenSigTimeout_IC" SG_ 502 PTS_GraphicRL 5250;
BA_ "GenSigStartValue" SG_ 502 PTS_GraphicRL 3;
BA_ "GenSigSNA" SG_ 502 PTS_GraphicRL "3h";
BA_ "GenSigSendType" SG_ 502 PTS_GraphicRL 5;
BA_ "GenSigCycleTime" SG_ 502 PTS_GraphicRL 500;
BA_ "FlexKomSigStartValue" SG_ 502 PTS_GraphicRL "F0h";
BA_ "FlexKomSigStartPos" SG_ 502 PTS_GraphicRL 31;
BA_ "FlexKomSigName" SG_ 502 PTS_GraphicRL "PTS_RL";
BA_ "FlexKomSigLaenge" SG_ 502 PTS_GraphicRL 8;
BA_ "FlexKomSID" SG_ 502 PTS_GraphicRL 1119;
BA_ "FlexKomIsMotorola" SG_ 502 PTS_GraphicRL 1;
BA_ "FlexKomComment" SG_ 502 PTS_GraphicRL "Park assist rear left warnings";
BA_ "RID" SG_ 502 PTS_AlrRR "1005 2099";
BA_ "GenSigTimeout_IC" SG_ 502 PTS_AlrRR 5250;
BA_ "GenSigTimeout_CBC" SG_ 502 PTS_AlrRR 5250;
BA_ "GenSigSNA" SG_ 502 PTS_AlrRR "Fh";
BA_ "GenSigSendType" SG_ 502 PTS_AlrRR 5;
BA_ "GenSigCycleTime" SG_ 502 PTS_AlrRR 500;
BA_ "FlexKomSigStartValue" SG_ 502 PTS_AlrRR "F0h";
BA_ "FlexKomSigStartPos" SG_ 502 PTS_AlrRR 39;
BA_ "FlexKomSigName" SG_ 502 PTS_AlrRR "PTS_RR";
BA_ "FlexKomSigLaenge" SG_ 502 PTS_AlrRR 8;
BA_ "FlexKomSID" SG_ 502 PTS_AlrRR 1120;
BA_ "FlexKomIsMotorola" SG_ 502 PTS_AlrRR 1;
BA_ "FlexKomComment" SG_ 502 PTS_AlrRR "Park assist rear right warnings";
BA_ "GenSigTimeout_IC" SG_ 502 PTS_GraphicRR 5250;
BA_ "GenSigStartValue" SG_ 502 PTS_GraphicRR 3;
BA_ "GenSigSNA" SG_ 502 PTS_GraphicRR "3h";
BA_ "GenSigSendType" SG_ 502 PTS_GraphicRR 5;
BA_ "GenSigCycleTime" SG_ 502 PTS_GraphicRR 500;
BA_ "FlexKomSigStartValue" SG_ 502 PTS_GraphicRR "F0h";
BA_ "FlexKomSigStartPos" SG_ 502 PTS_GraphicRR 39;
BA_ "FlexKomSigName" SG_ 502 PTS_GraphicRR "PTS_RR";
BA_ "FlexKomSigLaenge" SG_ 502 PTS_GraphicRR 8;
BA_ "FlexKomSID" SG_ 502 PTS_GraphicRR 1120;
BA_ "FlexKomIsMotorola" SG_ 502 PTS_GraphicRR 1;
BA_ "FlexKomComment" SG_ 502 PTS_GraphicRR "Park assist rear right warnings";
BA_ "RID" SG_ 502 PTS_AlrFC "2103";
BA_ "GenSigTimeout_IC" SG_ 502 PTS_AlrFC 5250;
BA_ "GenSigTimeout_CBC" SG_ 502 PTS_AlrFC 5250;
BA_ "GenSigSNA" SG_ 502 PTS_AlrFC "Fh";
BA_ "GenSigSendType" SG_ 502 PTS_AlrFC 5;
BA_ "GenSigCycleTime" SG_ 502 PTS_AlrFC 500;
BA_ "FlexKomSigStartValue" SG_ 502 PTS_AlrFC "F0h";
BA_ "FlexKomSigStartPos" SG_ 502 PTS_AlrFC 47;
BA_ "FlexKomSigName" SG_ 502 PTS_AlrFC "PTS_FC";
BA_ "FlexKomSigLaenge" SG_ 502 PTS_AlrFC 8;
BA_ "FlexKomSID" SG_ 502 PTS_AlrFC 1121;
BA_ "FlexKomIsMotorola" SG_ 502 PTS_AlrFC 1;
BA_ "FlexKomComment" SG_ 502 PTS_AlrFC "Park assist front center warnings";
BA_ "GenSigTimeout_IC" SG_ 502 PTS_GraphicFC 5250;
BA_ "GenSigStartValue" SG_ 502 PTS_GraphicFC 3;
BA_ "GenSigSNA" SG_ 502 PTS_GraphicFC "3h";
BA_ "GenSigSendType" SG_ 502 PTS_GraphicFC 5;
BA_ "GenSigCycleTime" SG_ 502 PTS_GraphicFC 500;
BA_ "FlexKomSigStartValue" SG_ 502 PTS_GraphicFC "F0h";
BA_ "FlexKomSigStartPos" SG_ 502 PTS_GraphicFC 47;
BA_ "FlexKomSigName" SG_ 502 PTS_GraphicFC "PTS_FC";
BA_ "FlexKomSigLaenge" SG_ 502 PTS_GraphicFC 8;
BA_ "FlexKomSID" SG_ 502 PTS_GraphicFC 1121;
BA_ "FlexKomIsMotorola" SG_ 502 PTS_GraphicFC 1;
BA_ "FlexKomComment" SG_ 502 PTS_GraphicFC "Park assist front center warnings";
BA_ "RID" SG_ 502 PTS_AlrRC "1026 2098";
BA_ "GenSigTimeout_IC" SG_ 502 PTS_AlrRC 5250;
BA_ "GenSigTimeout_CBC" SG_ 502 PTS_AlrRC 5250;
BA_ "GenSigSNA" SG_ 502 PTS_AlrRC "Fh";
BA_ "GenSigSendType" SG_ 502 PTS_AlrRC 5;
BA_ "GenSigCycleTime" SG_ 502 PTS_AlrRC 500;
BA_ "FlexKomSigStartValue" SG_ 502 PTS_AlrRC "F0h";
BA_ "FlexKomSigStartPos" SG_ 502 PTS_AlrRC 55;
BA_ "FlexKomSigName" SG_ 502 PTS_AlrRC "PTS_RC";
BA_ "FlexKomSigLaenge" SG_ 502 PTS_AlrRC 8;
BA_ "FlexKomSID" SG_ 502 PTS_AlrRC 1123;
BA_ "FlexKomIsMotorola" SG_ 502 PTS_AlrRC 1;
BA_ "FlexKomComment" SG_ 502 PTS_AlrRC "Park assist rear center warnings";
BA_ "GenSigTimeout_IC" SG_ 502 PTS_GraphicRC 5250;
BA_ "GenSigStartValue" SG_ 502 PTS_GraphicRC 3;
BA_ "GenSigSNA" SG_ 502 PTS_GraphicRC "3h";
BA_ "GenSigSendType" SG_ 502 PTS_GraphicRC 5;
BA_ "GenSigCycleTime" SG_ 502 PTS_GraphicRC 500;
BA_ "FlexKomSigStartValue" SG_ 502 PTS_GraphicRC "F0h";
BA_ "FlexKomSigStartPos" SG_ 502 PTS_GraphicRC 55;
BA_ "FlexKomSigName" SG_ 502 PTS_GraphicRC "PTS_RC";
BA_ "FlexKomSigLaenge" SG_ 502 PTS_GraphicRC 8;
BA_ "FlexKomSID" SG_ 502 PTS_GraphicRC 1123;
BA_ "FlexKomIsMotorola" SG_ 502 PTS_GraphicRC 1;
BA_ "FlexKomComment" SG_ 502 PTS_GraphicRC "Park assist rear center warnings";
BA_ "GenSigTimeout_IC" SG_ 502 PTS_FT_SRV 5250;
BA_ "GenSigSNA" SG_ 502 PTS_FT_SRV "0h";
BA_ "GenSigSendType" SG_ 502 PTS_FT_SRV 5;
BA_ "GenSigCycleTime" SG_ 502 PTS_FT_SRV 500;
BA_ "FlexKomSigStartValue" SG_ 502 PTS_FT_SRV "00h";
BA_ "FlexKomSigStartPos" SG_ 502 PTS_FT_SRV 58;
BA_ "FlexKomSigName" SG_ 502 PTS_FT_SRV "PTS_FT_SRV";
BA_ "FlexKomSigLaenge" SG_ 502 PTS_FT_SRV 1;
BA_ "FlexKomSID" SG_ 502 PTS_FT_SRV 1354;
BA_ "FlexKomIsMotorola" SG_ 502 PTS_FT_SRV 1;
BA_ "FlexKomComment" SG_ 502 PTS_FT_SRV "Front PTS sensor service request; True = [1]";
BA_ "GenSigTimeout_IC" SG_ 502 PTS_RR_SRV 5250;
BA_ "GenSigSNA" SG_ 502 PTS_RR_SRV "0h";
BA_ "GenSigSendType" SG_ 502 PTS_RR_SRV 5;
BA_ "GenSigCycleTime" SG_ 502 PTS_RR_SRV 500;
BA_ "FlexKomSigStartValue" SG_ 502 PTS_RR_SRV "00h";
BA_ "FlexKomSigStartPos" SG_ 502 PTS_RR_SRV 59;
BA_ "FlexKomSigName" SG_ 502 PTS_RR_SRV "PTS_RR_SRV";
BA_ "FlexKomSigLaenge" SG_ 502 PTS_RR_SRV 1;
BA_ "FlexKomSID" SG_ 502 PTS_RR_SRV 1353;
BA_ "FlexKomIsMotorola" SG_ 502 PTS_RR_SRV 1;
BA_ "FlexKomComment" SG_ 502 PTS_RR_SRV "Rear PTS sensor service request; True = [1]";
BA_ "RID" SG_ 502 PTS_STAT "1877 1939 5117";
BA_ "GenSigTimeout_CBC" SG_ 502 PTS_STAT 5250;
BA_ "GenSigSNA" SG_ 502 PTS_STAT "3h";
BA_ "GenSigSendType" SG_ 502 PTS_STAT 5;
BA_ "GenSigCycleTime" SG_ 502 PTS_STAT 500;
BA_ "FlexKomSigStartValue" SG_ 502 PTS_STAT "00h";
BA_ "FlexKomSigStartPos" SG_ 502 PTS_STAT 61;
BA_ "FlexKomSigName" SG_ 502 PTS_STAT "PTS_STAT";
BA_ "FlexKomSigLaenge" SG_ 502 PTS_STAT 2;
BA_ "FlexKomSID" SG_ 502 PTS_STAT 1862;
BA_ "FlexKomIsMotorola" SG_ 502 PTS_STAT 1;
BA_ "FlexKomComment" SG_ 502 PTS_STAT "Park Assist System - LED control status";
BA_ "GenSigTimeout_ETM" SG_ 503 xtended_AvgFuelLvl 5250;
BA_ "GenSigTimeout_CBC" SG_ 503 xtended_AvgFuelLvl 5250;
BA_ "GenSigStartValue" SG_ 503 xtended_AvgFuelLvl 4095;
BA_ "GenSigSNA" SG_ 503 xtended_AvgFuelLvl "FFFh";
BA_ "GenSigCycleTime" SG_ 503 xtended_AvgFuelLvl 500;
BA_ "FlexKomSigStartValue" SG_ 503 xtended_AvgFuelLvl "0FFFh";
BA_ "FlexKomSigStartPos" SG_ 503 xtended_AvgFuelLvl 23;
BA_ "FlexKomSigName" SG_ 503 xtended_AvgFuelLvl "xtended_AvgFuelLvl";
BA_ "FlexKomSigLaenge" SG_ 503 xtended_AvgFuelLvl 16;
BA_ "FlexKomSID" SG_ 503 xtended_AvgFuelLvl 2440;
BA_ "FlexKomIsMotorola" SG_ 503 xtended_AvgFuelLvl 1;
BA_ "FlexKomComment" SG_ 503 xtended_AvgFuelLvl "Epanded average filtered fuel level in liters";
BA_ "RID" SG_ 503 Est_Range_Disp "6522";
BA_ "GenSigTimeout_ETM" SG_ 503 Est_Range_Disp 5250;
BA_ "GenSigTimeout_CBC" SG_ 503 Est_Range_Disp 5250;
BA_ "GenSigSNA" SG_ 503 Est_Range_Disp "FFh";
BA_ "GenSigCycleTime" SG_ 503 Est_Range_Disp 500;
BA_ "FlexKomSigStartValue" SG_ 503 Est_Range_Disp "00h";
BA_ "FlexKomSigStartPos" SG_ 503 Est_Range_Disp 39;
BA_ "FlexKomSigName" SG_ 503 Est_Range_Disp "Est_Range_Disp";
BA_ "FlexKomSigLaenge" SG_ 503 Est_Range_Disp 8;
BA_ "FlexKomSID" SG_ 503 Est_Range_Disp 2543;
BA_ "FlexKomIsMotorola" SG_ 503 Est_Range_Disp 1;
BA_ "FlexKomComment" SG_ 503 Est_Range_Disp "Estimated electric range for display";
BA_ "RID" SG_ 503 VehSpd_MPH "1330";
BA_ "GenSigSNA" SG_ 503 VehSpd_MPH "0h";
BA_ "GenSigCycleTime" SG_ 503 VehSpd_MPH 500;
BA_ "FlexKomSigStartValue" SG_ 503 VehSpd_MPH "00h";
BA_ "FlexKomSigStartPos" SG_ 503 VehSpd_MPH 47;
BA_ "FlexKomSigName" SG_ 503 VehSpd_MPH "VehSpd_MPH";
BA_ "FlexKomSigLaenge" SG_ 503 VehSpd_MPH 1;
BA_ "FlexKomSID" SG_ 503 VehSpd_MPH 1585;
BA_ "FlexKomIsMotorola" SG_ 503 VehSpd_MPH 1;
BA_ "FlexKomComment" SG_ 503 VehSpd_MPH "Vehicle speed signal is in miles per hour format";
BA_ "RID" SG_ 503 VehSpdDisp "1057";
BA_ "GenSigTimeout_CBC" SG_ 503 VehSpdDisp 5250;
BA_ "GenSigStartValue" SG_ 503 VehSpdDisp 65535;
BA_ "GenSigSNA" SG_ 503 VehSpdDisp "FFFFh";
BA_ "GenSigCycleTime" SG_ 503 VehSpdDisp 500;
BA_ "FlexKomSigStartValue" SG_ 503 VehSpdDisp "FFFFh";
BA_ "FlexKomSigStartPos" SG_ 503 VehSpdDisp 55;
BA_ "FlexKomSigName" SG_ 503 VehSpdDisp "VehSpdDisp";
BA_ "FlexKomSigLaenge" SG_ 503 VehSpdDisp 16;
BA_ "FlexKomSID" SG_ 503 VehSpdDisp 1430;
BA_ "FlexKomIsMotorola" SG_ 503 VehSpdDisp 1;
BA_ "FlexKomComment" SG_ 503 VehSpdDisp "Vehicle speed - displayed";
BA_ "GenSigSNA" SG_ 505 MtrPwrUsageDisp "0h";
BA_ "GenSigCycleTime" SG_ 505 MtrPwrUsageDisp 500;
BA_ "FlexKomSigStartValue" SG_ 505 MtrPwrUsageDisp "0000000000000000h";
BA_ "FlexKomSigStartPos" SG_ 505 MtrPwrUsageDisp 7;
BA_ "FlexKomSigName" SG_ 505 MtrPwrUsageDisp "HCP_DISP";
BA_ "FlexKomSigLaenge" SG_ 505 MtrPwrUsageDisp 64;
BA_ "FlexKomSID" SG_ 505 MtrPwrUsageDisp 2549;
BA_ "FlexKomIsMotorola" SG_ 505 MtrPwrUsageDisp 1;
BA_ "FlexKomComment" SG_ 505 MtrPwrUsageDisp "HCP Info for Display";
BA_ "RID" SG_ 505 BatPwrUsageDisp "6520";
BA_ "GenSigTimeout_CBC" SG_ 505 BatPwrUsageDisp 10500;
BA_ "GenSigSNA" SG_ 505 BatPwrUsageDisp "0h";
BA_ "GenSigCycleTime" SG_ 505 BatPwrUsageDisp 500;
BA_ "FlexKomSigStartValue" SG_ 505 BatPwrUsageDisp "0000000000000000h";
BA_ "FlexKomSigStartPos" SG_ 505 BatPwrUsageDisp 7;
BA_ "FlexKomSigName" SG_ 505 BatPwrUsageDisp "HCP_DISP";
BA_ "FlexKomSigLaenge" SG_ 505 BatPwrUsageDisp 64;
BA_ "FlexKomSID" SG_ 505 BatPwrUsageDisp 2549;
BA_ "FlexKomIsMotorola" SG_ 505 BatPwrUsageDisp 1;
BA_ "FlexKomComment" SG_ 505 BatPwrUsageDisp "HCP Info for Display";
BA_ "RID" SG_ 505 MtrAPwrUsageDisp "6556";
BA_ "GenSigSNA" SG_ 505 MtrAPwrUsageDisp "0h";
BA_ "GenSigCycleTime" SG_ 505 MtrAPwrUsageDisp 500;
BA_ "FlexKomSigStartValue" SG_ 505 MtrAPwrUsageDisp "0000000000000000h";
BA_ "FlexKomSigStartPos" SG_ 505 MtrAPwrUsageDisp 7;
BA_ "FlexKomSigName" SG_ 505 MtrAPwrUsageDisp "HCP_DISP";
BA_ "FlexKomSigLaenge" SG_ 505 MtrAPwrUsageDisp 64;
BA_ "FlexKomSID" SG_ 505 MtrAPwrUsageDisp 2549;
BA_ "FlexKomIsMotorola" SG_ 505 MtrAPwrUsageDisp 1;
BA_ "FlexKomComment" SG_ 505 MtrAPwrUsageDisp "HCP Info for Display";
BA_ "RID" SG_ 505 HVACPwrUsageDisp "6516";
BA_ "GenSigTimeout_CBC" SG_ 505 HVACPwrUsageDisp 10500;
BA_ "GenSigSNA" SG_ 505 HVACPwrUsageDisp "0h";
BA_ "GenSigCycleTime" SG_ 505 HVACPwrUsageDisp 500;
BA_ "FlexKomSigStartValue" SG_ 505 HVACPwrUsageDisp "0000000000000000h";
BA_ "FlexKomSigStartPos" SG_ 505 HVACPwrUsageDisp 7;
BA_ "FlexKomSigName" SG_ 505 HVACPwrUsageDisp "HCP_DISP";
BA_ "FlexKomSigLaenge" SG_ 505 HVACPwrUsageDisp 64;
BA_ "FlexKomSID" SG_ 505 HVACPwrUsageDisp 2549;
BA_ "FlexKomIsMotorola" SG_ 505 HVACPwrUsageDisp 1;
BA_ "FlexKomComment" SG_ 505 HVACPwrUsageDisp "HCP Info for Display";
BA_ "RID" SG_ 505 MtrAPwrUsageDispV "6557";
BA_ "GenSigSNA" SG_ 505 MtrAPwrUsageDispV "0h";
BA_ "GenSigCycleTime" SG_ 505 MtrAPwrUsageDispV 500;
BA_ "FlexKomSigStartValue" SG_ 505 MtrAPwrUsageDispV "0000000000000000h";
BA_ "FlexKomSigStartPos" SG_ 505 MtrAPwrUsageDispV 7;
BA_ "FlexKomSigName" SG_ 505 MtrAPwrUsageDispV "HCP_DISP";
BA_ "FlexKomSigLaenge" SG_ 505 MtrAPwrUsageDispV 64;
BA_ "FlexKomSID" SG_ 505 MtrAPwrUsageDispV 2549;
BA_ "FlexKomIsMotorola" SG_ 505 MtrAPwrUsageDispV 1;
BA_ "FlexKomComment" SG_ 505 MtrAPwrUsageDispV "HCP Info for Display";
BA_ "RID" SG_ 505 HVBatSOC_HCP "6519";
BA_ "GenSigTimeout_CBC" SG_ 505 HVBatSOC_HCP 10500;
BA_ "GenSigSNA" SG_ 505 HVBatSOC_HCP "0h";
BA_ "GenSigCycleTime" SG_ 505 HVBatSOC_HCP 500;
BA_ "FlexKomSigStartValue" SG_ 505 HVBatSOC_HCP "0000000000000000h";
BA_ "FlexKomSigStartPos" SG_ 505 HVBatSOC_HCP 7;
BA_ "FlexKomSigName" SG_ 505 HVBatSOC_HCP "HCP_DISP";
BA_ "FlexKomSigLaenge" SG_ 505 HVBatSOC_HCP 64;
BA_ "FlexKomSID" SG_ 505 HVBatSOC_HCP 2549;
BA_ "FlexKomIsMotorola" SG_ 505 HVBatSOC_HCP 1;
BA_ "FlexKomComment" SG_ 505 HVBatSOC_HCP "HCP Info for Display";
BA_ "RID" SG_ 505 MtrBPwrUsageDisp "6555";
BA_ "GenSigSNA" SG_ 505 MtrBPwrUsageDisp "0h";
BA_ "GenSigCycleTime" SG_ 505 MtrBPwrUsageDisp 500;
BA_ "FlexKomSigStartValue" SG_ 505 MtrBPwrUsageDisp "0000000000000000h";
BA_ "FlexKomSigStartPos" SG_ 505 MtrBPwrUsageDisp 7;
BA_ "FlexKomSigName" SG_ 505 MtrBPwrUsageDisp "HCP_DISP";
BA_ "FlexKomSigLaenge" SG_ 505 MtrBPwrUsageDisp 64;
BA_ "FlexKomSID" SG_ 505 MtrBPwrUsageDisp 2549;
BA_ "FlexKomIsMotorola" SG_ 505 MtrBPwrUsageDisp 1;
BA_ "FlexKomComment" SG_ 505 MtrBPwrUsageDisp "HCP Info for Display";
BA_ "GenSigSNA" SG_ 505 MtrPwrUsageDisp_V "0h";
BA_ "GenSigCycleTime" SG_ 505 MtrPwrUsageDisp_V 500;
BA_ "FlexKomSigStartValue" SG_ 505 MtrPwrUsageDisp_V "0000000000000000h";
BA_ "FlexKomSigStartPos" SG_ 505 MtrPwrUsageDisp_V 7;
BA_ "FlexKomSigName" SG_ 505 MtrPwrUsageDisp_V "HCP_DISP";
BA_ "FlexKomSigLaenge" SG_ 505 MtrPwrUsageDisp_V 64;
BA_ "FlexKomSID" SG_ 505 MtrPwrUsageDisp_V 2549;
BA_ "FlexKomIsMotorola" SG_ 505 MtrPwrUsageDisp_V 1;
BA_ "FlexKomComment" SG_ 505 MtrPwrUsageDisp_V "HCP Info for Display";
BA_ "RID" SG_ 505 BatPwrUsageDisp_V "6509";
BA_ "GenSigTimeout_CBC" SG_ 505 BatPwrUsageDisp_V 10500;
BA_ "GenSigSNA" SG_ 505 BatPwrUsageDisp_V "0h";
BA_ "GenSigCycleTime" SG_ 505 BatPwrUsageDisp_V 500;
BA_ "FlexKomSigStartValue" SG_ 505 BatPwrUsageDisp_V "0000000000000000h";
BA_ "FlexKomSigStartPos" SG_ 505 BatPwrUsageDisp_V 7;
BA_ "FlexKomSigName" SG_ 505 BatPwrUsageDisp_V "HCP_DISP";
BA_ "FlexKomSigLaenge" SG_ 505 BatPwrUsageDisp_V 64;
BA_ "FlexKomSID" SG_ 505 BatPwrUsageDisp_V 2549;
BA_ "FlexKomIsMotorola" SG_ 505 BatPwrUsageDisp_V 1;
BA_ "FlexKomComment" SG_ 505 BatPwrUsageDisp_V "HCP Info for Display";
BA_ "RID" SG_ 505 EngPwrUsageDisp_V "6512";
BA_ "GenSigTimeout_CBC" SG_ 505 EngPwrUsageDisp_V 10500;
BA_ "GenSigSNA" SG_ 505 EngPwrUsageDisp_V "0h";
BA_ "GenSigCycleTime" SG_ 505 EngPwrUsageDisp_V 500;
BA_ "FlexKomSigStartValue" SG_ 505 EngPwrUsageDisp_V "0000000000000000h";
BA_ "FlexKomSigStartPos" SG_ 505 EngPwrUsageDisp_V 7;
BA_ "FlexKomSigName" SG_ 505 EngPwrUsageDisp_V "HCP_DISP";
BA_ "FlexKomSigLaenge" SG_ 505 EngPwrUsageDisp_V 64;
BA_ "FlexKomSID" SG_ 505 EngPwrUsageDisp_V 2549;
BA_ "FlexKomIsMotorola" SG_ 505 EngPwrUsageDisp_V 1;
BA_ "FlexKomComment" SG_ 505 EngPwrUsageDisp_V "HCP Info for Display";
BA_ "RID" SG_ 505 HVACPwrUsageDisp_V "6513";
BA_ "GenSigTimeout_CBC" SG_ 505 HVACPwrUsageDisp_V 10500;
BA_ "GenSigSNA" SG_ 505 HVACPwrUsageDisp_V "0h";
BA_ "GenSigCycleTime" SG_ 505 HVACPwrUsageDisp_V 500;
BA_ "FlexKomSigStartValue" SG_ 505 HVACPwrUsageDisp_V "0000000000000000h";
BA_ "FlexKomSigStartPos" SG_ 505 HVACPwrUsageDisp_V 7;
BA_ "FlexKomSigName" SG_ 505 HVACPwrUsageDisp_V "HCP_DISP";
BA_ "FlexKomSigLaenge" SG_ 505 HVACPwrUsageDisp_V 64;
BA_ "FlexKomSID" SG_ 505 HVACPwrUsageDisp_V 2549;
BA_ "FlexKomIsMotorola" SG_ 505 HVACPwrUsageDisp_V 1;
BA_ "FlexKomComment" SG_ 505 HVACPwrUsageDisp_V "HCP Info for Display";
BA_ "RID" SG_ 505 HVBatSOCV_HCP "6514";
BA_ "GenSigTimeout_CBC" SG_ 505 HVBatSOCV_HCP 10500;
BA_ "GenSigSNA" SG_ 505 HVBatSOCV_HCP "0h";
BA_ "GenSigCycleTime" SG_ 505 HVBatSOCV_HCP 500;
BA_ "FlexKomSigStartValue" SG_ 505 HVBatSOCV_HCP "0000000000000000h";
BA_ "FlexKomSigStartPos" SG_ 505 HVBatSOCV_HCP 7;
BA_ "FlexKomSigName" SG_ 505 HVBatSOCV_HCP "HCP_DISP";
BA_ "FlexKomSigLaenge" SG_ 505 HVBatSOCV_HCP 64;
BA_ "FlexKomSID" SG_ 505 HVBatSOCV_HCP 2549;
BA_ "FlexKomIsMotorola" SG_ 505 HVBatSOCV_HCP 1;
BA_ "FlexKomComment" SG_ 505 HVBatSOCV_HCP "HCP Info for Display";
BA_ "RID" SG_ 505 MtrBPwrUsageDispV "6554";
BA_ "GenSigSNA" SG_ 505 MtrBPwrUsageDispV "0h";
BA_ "GenSigCycleTime" SG_ 505 MtrBPwrUsageDispV 500;
BA_ "FlexKomSigStartValue" SG_ 505 MtrBPwrUsageDispV "0000000000000000h";
BA_ "FlexKomSigStartPos" SG_ 505 MtrBPwrUsageDispV 7;
BA_ "FlexKomSigName" SG_ 505 MtrBPwrUsageDispV "HCP_DISP";
BA_ "FlexKomSigLaenge" SG_ 505 MtrBPwrUsageDispV 64;
BA_ "FlexKomSID" SG_ 505 MtrBPwrUsageDispV 2549;
BA_ "FlexKomIsMotorola" SG_ 505 MtrBPwrUsageDispV 1;
BA_ "FlexKomComment" SG_ 505 MtrBPwrUsageDispV "HCP Info for Display";
BA_ "RID" SG_ 505 EngPwrUsageDisp "6506";
BA_ "GenSigTimeout_CBC" SG_ 505 EngPwrUsageDisp 10500;
BA_ "GenSigSNA" SG_ 505 EngPwrUsageDisp "0h";
BA_ "GenSigCycleTime" SG_ 505 EngPwrUsageDisp 500;
BA_ "FlexKomSigStartValue" SG_ 505 EngPwrUsageDisp "0000000000000000h";
BA_ "FlexKomSigStartPos" SG_ 505 EngPwrUsageDisp 7;
BA_ "FlexKomSigName" SG_ 505 EngPwrUsageDisp "HCP_DISP";
BA_ "FlexKomSigLaenge" SG_ 505 EngPwrUsageDisp 64;
BA_ "FlexKomSID" SG_ 505 EngPwrUsageDisp 2549;
BA_ "FlexKomIsMotorola" SG_ 505 EngPwrUsageDisp 1;
BA_ "FlexKomComment" SG_ 505 EngPwrUsageDisp "HCP Info for Display";
BA_ "GenSigSNA" SG_ 515 ControlEncodingRq "0h";
BA_ "GenSigSendType" SG_ 515 ControlEncodingRq 1;
BA_ "FlexKomSigStartValue" SG_ 515 ControlEncodingRq "00000000000000h";
BA_ "FlexKomSigStartPos" SG_ 515 ControlEncodingRq 7;
BA_ "FlexKomSigName" SG_ 515 ControlEncodingRq "IMMO_CODE_REQUEST_HCP";
BA_ "FlexKomSigLaenge" SG_ 515 ControlEncodingRq 56;
BA_ "FlexKomSID" SG_ 515 ControlEncodingRq 2516;
BA_ "FlexKomIsMotorola" SG_ 515 ControlEncodingRq 1;
BA_ "FlexKomComment" SG_ 515 ControlEncodingRq "Immobilizer code request packet";
BA_ "GenSigSNA" SG_ 515 rnd_01 "0h";
BA_ "GenSigSendType" SG_ 515 rnd_01 1;
BA_ "FlexKomSigStartValue" SG_ 515 rnd_01 "00000000000000h";
BA_ "FlexKomSigStartPos" SG_ 515 rnd_01 7;
BA_ "FlexKomSigName" SG_ 515 rnd_01 "IMMO_CODE_REQUEST_HCP";
BA_ "FlexKomSigLaenge" SG_ 515 rnd_01 56;
BA_ "FlexKomSID" SG_ 515 rnd_01 2516;
BA_ "FlexKomIsMotorola" SG_ 515 rnd_01 1;
BA_ "FlexKomComment" SG_ 515 rnd_01 "Immobilizer code request packet";
BA_ "GenSigSNA" SG_ 515 rnd_02 "0h";
BA_ "GenSigSendType" SG_ 515 rnd_02 1;
BA_ "FlexKomSigStartValue" SG_ 515 rnd_02 "00000000000000h";
BA_ "FlexKomSigStartPos" SG_ 515 rnd_02 7;
BA_ "FlexKomSigName" SG_ 515 rnd_02 "IMMO_CODE_REQUEST_HCP";
BA_ "FlexKomSigLaenge" SG_ 515 rnd_02 56;
BA_ "FlexKomSID" SG_ 515 rnd_02 2516;
BA_ "FlexKomIsMotorola" SG_ 515 rnd_02 1;
BA_ "FlexKomComment" SG_ 515 rnd_02 "Immobilizer code request packet";
BA_ "GenSigSNA" SG_ 515 rnd_03 "0h";
BA_ "GenSigSendType" SG_ 515 rnd_03 1;
BA_ "FlexKomSigStartValue" SG_ 515 rnd_03 "00000000000000h";
BA_ "FlexKomSigStartPos" SG_ 515 rnd_03 7;
BA_ "FlexKomSigName" SG_ 515 rnd_03 "IMMO_CODE_REQUEST_HCP";
BA_ "FlexKomSigLaenge" SG_ 515 rnd_03 56;
BA_ "FlexKomSID" SG_ 515 rnd_03 2516;
BA_ "FlexKomIsMotorola" SG_ 515 rnd_03 1;
BA_ "FlexKomComment" SG_ 515 rnd_03 "Immobilizer code request packet";
BA_ "GenSigSNA" SG_ 515 rnd_04 "0h";
BA_ "GenSigSendType" SG_ 515 rnd_04 1;
BA_ "FlexKomSigStartValue" SG_ 515 rnd_04 "00000000000000h";
BA_ "FlexKomSigStartPos" SG_ 515 rnd_04 7;
BA_ "FlexKomSigName" SG_ 515 rnd_04 "IMMO_CODE_REQUEST_HCP";
BA_ "FlexKomSigLaenge" SG_ 515 rnd_04 56;
BA_ "FlexKomSID" SG_ 515 rnd_04 2516;
BA_ "FlexKomIsMotorola" SG_ 515 rnd_04 1;
BA_ "FlexKomComment" SG_ 515 rnd_04 "Immobilizer code request packet";
BA_ "GenSigSNA" SG_ 515 f1_01 "0h";
BA_ "GenSigSendType" SG_ 515 f1_01 1;
BA_ "FlexKomSigStartValue" SG_ 515 f1_01 "00000000000000h";
BA_ "FlexKomSigStartPos" SG_ 515 f1_01 7;
BA_ "FlexKomSigName" SG_ 515 f1_01 "IMMO_CODE_REQUEST_HCP";
BA_ "FlexKomSigLaenge" SG_ 515 f1_01 56;
BA_ "FlexKomSID" SG_ 515 f1_01 2516;
BA_ "FlexKomIsMotorola" SG_ 515 f1_01 1;
BA_ "FlexKomComment" SG_ 515 f1_01 "Immobilizer code request packet";
BA_ "GenSigSNA" SG_ 515 f1_02 "0h";
BA_ "GenSigSendType" SG_ 515 f1_02 1;
BA_ "FlexKomSigStartValue" SG_ 515 f1_02 "00000000000000h";
BA_ "FlexKomSigStartPos" SG_ 515 f1_02 7;
BA_ "FlexKomSigName" SG_ 515 f1_02 "IMMO_CODE_REQUEST_HCP";
BA_ "FlexKomSigLaenge" SG_ 515 f1_02 56;
BA_ "FlexKomSID" SG_ 515 f1_02 2516;
BA_ "FlexKomIsMotorola" SG_ 515 f1_02 1;
BA_ "FlexKomComment" SG_ 515 f1_02 "Immobilizer code request packet";
BA_ "GenSigSNA" SG_ 516 ControlEncodingRsp "0h";
BA_ "GenSigSendType" SG_ 516 ControlEncodingRsp 1;
BA_ "FlexKomSigStartValue" SG_ 516 ControlEncodingRsp "00000000000000h";
BA_ "FlexKomSigStartPos" SG_ 516 ControlEncodingRsp 7;
BA_ "FlexKomSigName" SG_ 516 ControlEncodingRsp "IMMO_CODE_RESPONSE";
BA_ "FlexKomSigLaenge" SG_ 516 ControlEncodingRsp 56;
BA_ "FlexKomSID" SG_ 516 ControlEncodingRsp 2110;
BA_ "FlexKomIsMotorola" SG_ 516 ControlEncodingRsp 1;
BA_ "FlexKomComment" SG_ 516 ControlEncodingRsp "Immobilizer code response packet";
BA_ "GenSigSNA" SG_ 516 MKKey1org21 "0h";
BA_ "GenSigSendType" SG_ 516 MKKey1org21 1;
BA_ "FlexKomSigStartValue" SG_ 516 MKKey1org21 "00000000000000h";
BA_ "FlexKomSigStartPos" SG_ 516 MKKey1org21 7;
BA_ "FlexKomSigName" SG_ 516 MKKey1org21 "IMMO_CODE_RESPONSE";
BA_ "FlexKomSigLaenge" SG_ 516 MKKey1org21 56;
BA_ "FlexKomSID" SG_ 516 MKKey1org21 2110;
BA_ "FlexKomIsMotorola" SG_ 516 MKKey1org21 1;
BA_ "FlexKomComment" SG_ 516 MKKey1org21 "Immobilizer code response packet";
BA_ "GenSigSNA" SG_ 516 MKKey2org22 "0h";
BA_ "GenSigSendType" SG_ 516 MKKey2org22 1;
BA_ "FlexKomSigStartValue" SG_ 516 MKKey2org22 "00000000000000h";
BA_ "FlexKomSigStartPos" SG_ 516 MKKey2org22 7;
BA_ "FlexKomSigName" SG_ 516 MKKey2org22 "IMMO_CODE_RESPONSE";
BA_ "FlexKomSigLaenge" SG_ 516 MKKey2org22 56;
BA_ "FlexKomSID" SG_ 516 MKKey2org22 2110;
BA_ "FlexKomIsMotorola" SG_ 516 MKKey2org22 1;
BA_ "FlexKomComment" SG_ 516 MKKey2org22 "Immobilizer code response packet";
BA_ "GenSigSNA" SG_ 516 MKKey_3 "0h";
BA_ "GenSigSendType" SG_ 516 MKKey_3 1;
BA_ "FlexKomSigStartValue" SG_ 516 MKKey_3 "00000000000000h";
BA_ "FlexKomSigStartPos" SG_ 516 MKKey_3 7;
BA_ "FlexKomSigName" SG_ 516 MKKey_3 "IMMO_CODE_RESPONSE";
BA_ "FlexKomSigLaenge" SG_ 516 MKKey_3 56;
BA_ "FlexKomSID" SG_ 516 MKKey_3 2110;
BA_ "FlexKomIsMotorola" SG_ 516 MKKey_3 1;
BA_ "FlexKomComment" SG_ 516 MKKey_3 "Immobilizer code response packet";
BA_ "GenSigSNA" SG_ 516 MKKey_4 "0h";
BA_ "GenSigSendType" SG_ 516 MKKey_4 1;
BA_ "FlexKomSigStartValue" SG_ 516 MKKey_4 "00000000000000h";
BA_ "FlexKomSigStartPos" SG_ 516 MKKey_4 7;
BA_ "FlexKomSigName" SG_ 516 MKKey_4 "IMMO_CODE_RESPONSE";
BA_ "FlexKomSigLaenge" SG_ 516 MKKey_4 56;
BA_ "FlexKomSID" SG_ 516 MKKey_4 2110;
BA_ "FlexKomIsMotorola" SG_ 516 MKKey_4 1;
BA_ "FlexKomComment" SG_ 516 MKKey_4 "Immobilizer code response packet";
BA_ "GenSigSNA" SG_ 516 MKKey_5 "0h";
BA_ "GenSigSendType" SG_ 516 MKKey_5 1;
BA_ "FlexKomSigStartValue" SG_ 516 MKKey_5 "00000000000000h";
BA_ "FlexKomSigStartPos" SG_ 516 MKKey_5 7;
BA_ "FlexKomSigName" SG_ 516 MKKey_5 "IMMO_CODE_RESPONSE";
BA_ "FlexKomSigLaenge" SG_ 516 MKKey_5 56;
BA_ "FlexKomSID" SG_ 516 MKKey_5 2110;
BA_ "FlexKomIsMotorola" SG_ 516 MKKey_5 1;
BA_ "FlexKomComment" SG_ 516 MKKey_5 "Immobilizer code response packet";
BA_ "GenSigSNA" SG_ 516 MKKey_6 "0h";
BA_ "GenSigSendType" SG_ 516 MKKey_6 1;
BA_ "FlexKomSigStartValue" SG_ 516 MKKey_6 "00000000000000h";
BA_ "FlexKomSigStartPos" SG_ 516 MKKey_6 7;
BA_ "FlexKomSigName" SG_ 516 MKKey_6 "IMMO_CODE_RESPONSE";
BA_ "FlexKomSigLaenge" SG_ 516 MKKey_6 56;
BA_ "FlexKomSID" SG_ 516 MKKey_6 2110;
BA_ "FlexKomIsMotorola" SG_ 516 MKKey_6 1;
BA_ "FlexKomComment" SG_ 516 MKKey_6 "Immobilizer code response packet";
BA_ "GenSigSNA" SG_ 517 ControlEncodingRq "0h";
BA_ "GenSigSendType" SG_ 517 ControlEncodingRq 1;
BA_ "FlexKomSigStartValue" SG_ 517 ControlEncodingRq "00000000000000h";
BA_ "FlexKomSigStartPos" SG_ 517 ControlEncodingRq 7;
BA_ "FlexKomSigName" SG_ 517 ControlEncodingRq "IMMO_CODE_REQUEST";
BA_ "FlexKomSigLaenge" SG_ 517 ControlEncodingRq 56;
BA_ "FlexKomSID" SG_ 517 ControlEncodingRq 2111;
BA_ "FlexKomIsMotorola" SG_ 517 ControlEncodingRq 1;
BA_ "FlexKomComment" SG_ 517 ControlEncodingRq "Immobilizer code request packet";
BA_ "GenSigSNA" SG_ 517 rnd_1 "0h";
BA_ "GenSigSendType" SG_ 517 rnd_1 1;
BA_ "FlexKomSigStartValue" SG_ 517 rnd_1 "00000000000000h";
BA_ "FlexKomSigStartPos" SG_ 517 rnd_1 7;
BA_ "FlexKomSigName" SG_ 517 rnd_1 "IMMO_CODE_REQUEST";
BA_ "FlexKomSigLaenge" SG_ 517 rnd_1 56;
BA_ "FlexKomSID" SG_ 517 rnd_1 2111;
BA_ "FlexKomIsMotorola" SG_ 517 rnd_1 1;
BA_ "FlexKomComment" SG_ 517 rnd_1 "Immobilizer code request packet";
BA_ "GenSigSNA" SG_ 517 rnd_2 "0h";
BA_ "GenSigSendType" SG_ 517 rnd_2 1;
BA_ "FlexKomSigStartValue" SG_ 517 rnd_2 "00000000000000h";
BA_ "FlexKomSigStartPos" SG_ 517 rnd_2 7;
BA_ "FlexKomSigName" SG_ 517 rnd_2 "IMMO_CODE_REQUEST";
BA_ "FlexKomSigLaenge" SG_ 517 rnd_2 56;
BA_ "FlexKomSID" SG_ 517 rnd_2 2111;
BA_ "FlexKomIsMotorola" SG_ 517 rnd_2 1;
BA_ "FlexKomComment" SG_ 517 rnd_2 "Immobilizer code request packet";
BA_ "GenSigSNA" SG_ 517 rnd_3 "0h";
BA_ "GenSigSendType" SG_ 517 rnd_3 1;
BA_ "FlexKomSigStartValue" SG_ 517 rnd_3 "00000000000000h";
BA_ "FlexKomSigStartPos" SG_ 517 rnd_3 7;
BA_ "FlexKomSigName" SG_ 517 rnd_3 "IMMO_CODE_REQUEST";
BA_ "FlexKomSigLaenge" SG_ 517 rnd_3 56;
BA_ "FlexKomSID" SG_ 517 rnd_3 2111;
BA_ "FlexKomIsMotorola" SG_ 517 rnd_3 1;
BA_ "FlexKomComment" SG_ 517 rnd_3 "Immobilizer code request packet";
BA_ "GenSigSNA" SG_ 517 rnd_4 "0h";
BA_ "GenSigSendType" SG_ 517 rnd_4 1;
BA_ "FlexKomSigStartValue" SG_ 517 rnd_4 "00000000000000h";
BA_ "FlexKomSigStartPos" SG_ 517 rnd_4 7;
BA_ "FlexKomSigName" SG_ 517 rnd_4 "IMMO_CODE_REQUEST";
BA_ "FlexKomSigLaenge" SG_ 517 rnd_4 56;
BA_ "FlexKomSID" SG_ 517 rnd_4 2111;
BA_ "FlexKomIsMotorola" SG_ 517 rnd_4 1;
BA_ "FlexKomComment" SG_ 517 rnd_4 "Immobilizer code request packet";
BA_ "GenSigSNA" SG_ 517 f1_1 "0h";
BA_ "GenSigSendType" SG_ 517 f1_1 1;
BA_ "FlexKomSigStartValue" SG_ 517 f1_1 "00000000000000h";
BA_ "FlexKomSigStartPos" SG_ 517 f1_1 7;
BA_ "FlexKomSigName" SG_ 517 f1_1 "IMMO_CODE_REQUEST";
BA_ "FlexKomSigLaenge" SG_ 517 f1_1 56;
BA_ "FlexKomSID" SG_ 517 f1_1 2111;
BA_ "FlexKomIsMotorola" SG_ 517 f1_1 1;
BA_ "FlexKomComment" SG_ 517 f1_1 "Immobilizer code request packet";
BA_ "GenSigSNA" SG_ 517 f1_2 "0h";
BA_ "GenSigSendType" SG_ 517 f1_2 1;
BA_ "FlexKomSigStartValue" SG_ 517 f1_2 "00000000000000h";
BA_ "FlexKomSigStartPos" SG_ 517 f1_2 7;
BA_ "FlexKomSigName" SG_ 517 f1_2 "IMMO_CODE_REQUEST";
BA_ "FlexKomSigLaenge" SG_ 517 f1_2 56;
BA_ "FlexKomSID" SG_ 517 f1_2 2111;
BA_ "FlexKomIsMotorola" SG_ 517 f1_2 1;
BA_ "FlexKomComment" SG_ 517 f1_2 "Immobilizer code request packet";
BA_ "GenSigSNA" SG_ 518 ControlEncoding_Rsp "0h";
BA_ "GenSigSendType" SG_ 518 ControlEncoding_Rsp 1;
BA_ "FlexKomSigStartValue" SG_ 518 ControlEncoding_Rsp "00000000000000h";
BA_ "FlexKomSigStartPos" SG_ 518 ControlEncoding_Rsp 7;
BA_ "FlexKomSigName" SG_ 518 ControlEncoding_Rsp "IMMO_CODE_RESPONSE_HCP";
BA_ "FlexKomSigLaenge" SG_ 518 ControlEncoding_Rsp 56;
BA_ "FlexKomSID" SG_ 518 ControlEncoding_Rsp 2515;
BA_ "FlexKomIsMotorola" SG_ 518 ControlEncoding_Rsp 1;
BA_ "FlexKomComment" SG_ 518 ControlEncoding_Rsp "Immobilizer code response packet";
BA_ "GenSigSNA" SG_ 518 MKKey01org21 "0h";
BA_ "GenSigSendType" SG_ 518 MKKey01org21 1;
BA_ "FlexKomSigStartValue" SG_ 518 MKKey01org21 "00000000000000h";
BA_ "FlexKomSigStartPos" SG_ 518 MKKey01org21 7;
BA_ "FlexKomSigName" SG_ 518 MKKey01org21 "IMMO_CODE_RESPONSE_HCP";
BA_ "FlexKomSigLaenge" SG_ 518 MKKey01org21 56;
BA_ "FlexKomSID" SG_ 518 MKKey01org21 2515;
BA_ "FlexKomIsMotorola" SG_ 518 MKKey01org21 1;
BA_ "FlexKomComment" SG_ 518 MKKey01org21 "Immobilizer code response packet";
BA_ "GenSigSNA" SG_ 518 MKKey02org22 "0h";
BA_ "GenSigSendType" SG_ 518 MKKey02org22 1;
BA_ "FlexKomSigStartValue" SG_ 518 MKKey02org22 "00000000000000h";
BA_ "FlexKomSigStartPos" SG_ 518 MKKey02org22 7;
BA_ "FlexKomSigName" SG_ 518 MKKey02org22 "IMMO_CODE_RESPONSE_HCP";
BA_ "FlexKomSigLaenge" SG_ 518 MKKey02org22 56;
BA_ "FlexKomSID" SG_ 518 MKKey02org22 2515;
BA_ "FlexKomIsMotorola" SG_ 518 MKKey02org22 1;
BA_ "FlexKomComment" SG_ 518 MKKey02org22 "Immobilizer code response packet";
BA_ "GenSigSNA" SG_ 518 MKKey_03 "0h";
BA_ "GenSigSendType" SG_ 518 MKKey_03 1;
BA_ "FlexKomSigStartValue" SG_ 518 MKKey_03 "00000000000000h";
BA_ "FlexKomSigStartPos" SG_ 518 MKKey_03 7;
BA_ "FlexKomSigName" SG_ 518 MKKey_03 "IMMO_CODE_RESPONSE_HCP";
BA_ "FlexKomSigLaenge" SG_ 518 MKKey_03 56;
BA_ "FlexKomSID" SG_ 518 MKKey_03 2515;
BA_ "FlexKomIsMotorola" SG_ 518 MKKey_03 1;
BA_ "FlexKomComment" SG_ 518 MKKey_03 "Immobilizer code response packet";
BA_ "GenSigSNA" SG_ 518 MKKey_04 "0h";
BA_ "GenSigSendType" SG_ 518 MKKey_04 1;
BA_ "FlexKomSigStartValue" SG_ 518 MKKey_04 "00000000000000h";
BA_ "FlexKomSigStartPos" SG_ 518 MKKey_04 7;
BA_ "FlexKomSigName" SG_ 518 MKKey_04 "IMMO_CODE_RESPONSE_HCP";
BA_ "FlexKomSigLaenge" SG_ 518 MKKey_04 56;
BA_ "FlexKomSID" SG_ 518 MKKey_04 2515;
BA_ "FlexKomIsMotorola" SG_ 518 MKKey_04 1;
BA_ "FlexKomComment" SG_ 518 MKKey_04 "Immobilizer code response packet";
BA_ "GenSigSNA" SG_ 518 MKKey_05 "0h";
BA_ "GenSigSendType" SG_ 518 MKKey_05 1;
BA_ "FlexKomSigStartValue" SG_ 518 MKKey_05 "00000000000000h";
BA_ "FlexKomSigStartPos" SG_ 518 MKKey_05 7;
BA_ "FlexKomSigName" SG_ 518 MKKey_05 "IMMO_CODE_RESPONSE_HCP";
BA_ "FlexKomSigLaenge" SG_ 518 MKKey_05 56;
BA_ "FlexKomSID" SG_ 518 MKKey_05 2515;
BA_ "FlexKomIsMotorola" SG_ 518 MKKey_05 1;
BA_ "FlexKomComment" SG_ 518 MKKey_05 "Immobilizer code response packet";
BA_ "GenSigSNA" SG_ 518 MKKey_06 "0h";
BA_ "GenSigSendType" SG_ 518 MKKey_06 1;
BA_ "FlexKomSigStartValue" SG_ 518 MKKey_06 "00000000000000h";
BA_ "FlexKomSigStartPos" SG_ 518 MKKey_06 7;
BA_ "FlexKomSigName" SG_ 518 MKKey_06 "IMMO_CODE_RESPONSE_HCP";
BA_ "FlexKomSigLaenge" SG_ 518 MKKey_06 56;
BA_ "FlexKomSID" SG_ 518 MKKey_06 2515;
BA_ "FlexKomIsMotorola" SG_ 518 MKKey_06 1;
BA_ "FlexKomComment" SG_ 518 MKKey_06 "Immobilizer code response packet";
BA_ "GenSigSNA" SG_ 523 ControlEncodingESL "0h";
BA_ "GenSigSendType" SG_ 523 ControlEncodingESL 1;
BA_ "FlexKomSigStartValue" SG_ 523 ControlEncodingESL "0000000000000000h";
BA_ "FlexKomSigStartPos" SG_ 523 ControlEncodingESL 7;
BA_ "FlexKomSigName" SG_ 523 ControlEncodingESL "Code_ESL_RqPkt";
BA_ "FlexKomSigLaenge" SG_ 523 ControlEncodingESL 64;
BA_ "FlexKomSID" SG_ 523 ControlEncodingESL 2345;
BA_ "FlexKomIsMotorola" SG_ 523 ControlEncodingESL 1;
BA_ "FlexKomComment" SG_ 523 ControlEncodingESL "Code steering lock request packet";
BA_ "GenSigSNA" SG_ 523 MiniCryptFCodeESL "0h";
BA_ "GenSigSendType" SG_ 523 MiniCryptFCodeESL 1;
BA_ "FlexKomSigStartValue" SG_ 523 MiniCryptFCodeESL "0000000000000000h";
BA_ "FlexKomSigStartPos" SG_ 523 MiniCryptFCodeESL 7;
BA_ "FlexKomSigName" SG_ 523 MiniCryptFCodeESL "Code_ESL_RqPkt";
BA_ "FlexKomSigLaenge" SG_ 523 MiniCryptFCodeESL 64;
BA_ "FlexKomSID" SG_ 523 MiniCryptFCodeESL 2345;
BA_ "FlexKomIsMotorola" SG_ 523 MiniCryptFCodeESL 1;
BA_ "FlexKomComment" SG_ 523 MiniCryptFCodeESL "Code steering lock request packet";
BA_ "GenSigSNA" SG_ 523 MiniCrypt_RndESL "0h";
BA_ "GenSigSendType" SG_ 523 MiniCrypt_RndESL 1;
BA_ "FlexKomSigStartValue" SG_ 523 MiniCrypt_RndESL "0000000000000000h";
BA_ "FlexKomSigStartPos" SG_ 523 MiniCrypt_RndESL 7;
BA_ "FlexKomSigName" SG_ 523 MiniCrypt_RndESL "Code_ESL_RqPkt";
BA_ "FlexKomSigLaenge" SG_ 523 MiniCrypt_RndESL 64;
BA_ "FlexKomSID" SG_ 523 MiniCrypt_RndESL 2345;
BA_ "FlexKomIsMotorola" SG_ 523 MiniCrypt_RndESL 1;
BA_ "FlexKomComment" SG_ 523 MiniCrypt_RndESL "Code steering lock request packet";
BA_ "GenSigSNA" SG_ 523 ESLLockUnlockReq "0h";
BA_ "GenSigSendType" SG_ 523 ESLLockUnlockReq 1;
BA_ "FlexKomSigStartValue" SG_ 523 ESLLockUnlockReq "0000000000000000h";
BA_ "FlexKomSigStartPos" SG_ 523 ESLLockUnlockReq 7;
BA_ "FlexKomSigName" SG_ 523 ESLLockUnlockReq "Code_ESL_RqPkt";
BA_ "FlexKomSigLaenge" SG_ 523 ESLLockUnlockReq 64;
BA_ "FlexKomSID" SG_ 523 ESLLockUnlockReq 2345;
BA_ "FlexKomIsMotorola" SG_ 523 ESLLockUnlockReq 1;
BA_ "FlexKomComment" SG_ 523 ESLLockUnlockReq "Code steering lock request packet";
BA_ "GenSigSNA" SG_ 524 ControlEncodingBCM "0h";
BA_ "GenSigSendType" SG_ 524 ControlEncodingBCM 1;
BA_ "FlexKomSigStartValue" SG_ 524 ControlEncodingBCM "0000000000000000h";
BA_ "FlexKomSigStartPos" SG_ 524 ControlEncodingBCM 7;
BA_ "FlexKomSigName" SG_ 524 ControlEncodingBCM "Code_TRM_RqPkt";
BA_ "FlexKomSigLaenge" SG_ 524 ControlEncodingBCM 64;
BA_ "FlexKomSID" SG_ 524 ControlEncodingBCM 2331;
BA_ "FlexKomIsMotorola" SG_ 524 ControlEncodingBCM 1;
BA_ "FlexKomComment" SG_ 524 ControlEncodingBCM "Code transponder request packet";
BA_ "GenSigSNA" SG_ 524 MiniCryptFCode "0h";
BA_ "GenSigSendType" SG_ 524 MiniCryptFCode 1;
BA_ "FlexKomSigStartValue" SG_ 524 MiniCryptFCode "0000000000000000h";
BA_ "FlexKomSigStartPos" SG_ 524 MiniCryptFCode 7;
BA_ "FlexKomSigName" SG_ 524 MiniCryptFCode "Code_TRM_RqPkt";
BA_ "FlexKomSigLaenge" SG_ 524 MiniCryptFCode 64;
BA_ "FlexKomSID" SG_ 524 MiniCryptFCode 2331;
BA_ "FlexKomIsMotorola" SG_ 524 MiniCryptFCode 1;
BA_ "FlexKomComment" SG_ 524 MiniCryptFCode "Code transponder request packet";
BA_ "GenSigSNA" SG_ 524 MiniCrypt_Rnd "0h";
BA_ "GenSigSendType" SG_ 524 MiniCrypt_Rnd 1;
BA_ "FlexKomSigStartValue" SG_ 524 MiniCrypt_Rnd "0000000000000000h";
BA_ "FlexKomSigStartPos" SG_ 524 MiniCrypt_Rnd 7;
BA_ "FlexKomSigName" SG_ 524 MiniCrypt_Rnd "Code_TRM_RqPkt";
BA_ "FlexKomSigLaenge" SG_ 524 MiniCrypt_Rnd 64;
BA_ "FlexKomSID" SG_ 524 MiniCrypt_Rnd 2331;
BA_ "FlexKomIsMotorola" SG_ 524 MiniCrypt_Rnd 1;
BA_ "FlexKomComment" SG_ 524 MiniCrypt_Rnd "Code transponder request packet";
BA_ "GenSigSNA" SG_ 524 TxpReadRequest "0h";
BA_ "GenSigSendType" SG_ 524 TxpReadRequest 1;
BA_ "FlexKomSigStartValue" SG_ 524 TxpReadRequest "0000000000000000h";
BA_ "FlexKomSigStartPos" SG_ 524 TxpReadRequest 7;
BA_ "FlexKomSigName" SG_ 524 TxpReadRequest "Code_TRM_RqPkt";
BA_ "FlexKomSigLaenge" SG_ 524 TxpReadRequest 64;
BA_ "FlexKomSID" SG_ 524 TxpReadRequest 2331;
BA_ "FlexKomIsMotorola" SG_ 524 TxpReadRequest 1;
BA_ "FlexKomComment" SG_ 524 TxpReadRequest "Code transponder request packet";
BA_ "GenSigSNA" SG_ 524 TxpAuthRequest "0h";
BA_ "GenSigSendType" SG_ 524 TxpAuthRequest 1;
BA_ "FlexKomSigStartValue" SG_ 524 TxpAuthRequest "0000000000000000h";
BA_ "FlexKomSigStartPos" SG_ 524 TxpAuthRequest 7;
BA_ "FlexKomSigName" SG_ 524 TxpAuthRequest "Code_TRM_RqPkt";
BA_ "FlexKomSigLaenge" SG_ 524 TxpAuthRequest 64;
BA_ "FlexKomSID" SG_ 524 TxpAuthRequest 2331;
BA_ "FlexKomIsMotorola" SG_ 524 TxpAuthRequest 1;
BA_ "FlexKomComment" SG_ 524 TxpAuthRequest "Code transponder request packet";
BA_ "GenSigSNA" SG_ 525 MinicryptReceptionSts "0h";
BA_ "GenSigSendType" SG_ 525 MinicryptReceptionSts 1;
BA_ "FlexKomSigStartValue" SG_ 525 MinicryptReceptionSts "00h";
BA_ "FlexKomSigStartPos" SG_ 525 MinicryptReceptionSts 7;
BA_ "FlexKomSigName" SG_ 525 MinicryptReceptionSts "Minicrypt_AckPkt";
BA_ "FlexKomSigLaenge" SG_ 525 MinicryptReceptionSts 8;
BA_ "FlexKomSID" SG_ 525 MinicryptReceptionSts 2332;
BA_ "FlexKomIsMotorola" SG_ 525 MinicryptReceptionSts 1;
BA_ "FlexKomComment" SG_ 525 MinicryptReceptionSts "Minicrypt acknowledge packet";
BA_ "GenSigSNA" SG_ 526 ControlEncoding "0h";
BA_ "GenSigSendType" SG_ 526 ControlEncoding 1;
BA_ "FlexKomSigStartValue" SG_ 526 ControlEncoding "000000800000h";
BA_ "FlexKomSigStartPos" SG_ 526 ControlEncoding 7;
BA_ "FlexKomSigName" SG_ 526 ControlEncoding "TRM_CodePkt";
BA_ "FlexKomSigLaenge" SG_ 526 ControlEncoding 48;
BA_ "FlexKomSID" SG_ 526 ControlEncoding 2329;
BA_ "FlexKomIsMotorola" SG_ 526 ControlEncoding 1;
BA_ "FlexKomComment" SG_ 526 ControlEncoding "Transponder code packet";
BA_ "GenSigSNA" SG_ 526 MiniCryptGCode "0h";
BA_ "GenSigSendType" SG_ 526 MiniCryptGCode 1;
BA_ "FlexKomSigStartValue" SG_ 526 MiniCryptGCode "000000800000h";
BA_ "FlexKomSigStartPos" SG_ 526 MiniCryptGCode 7;
BA_ "FlexKomSigName" SG_ 526 MiniCryptGCode "TRM_CodePkt";
BA_ "FlexKomSigLaenge" SG_ 526 MiniCryptGCode 48;
BA_ "FlexKomSID" SG_ 526 MiniCryptGCode 2329;
BA_ "FlexKomIsMotorola" SG_ 526 MiniCryptGCode 1;
BA_ "FlexKomComment" SG_ 526 MiniCryptGCode "Transponder code packet";
BA_ "GenSigSNA" SG_ 526 CodeCheckSts "0h";
BA_ "GenSigSendType" SG_ 526 CodeCheckSts 1;
BA_ "FlexKomSigStartValue" SG_ 526 CodeCheckSts "000000800000h";
BA_ "FlexKomSigStartPos" SG_ 526 CodeCheckSts 7;
BA_ "FlexKomSigName" SG_ 526 CodeCheckSts "TRM_CodePkt";
BA_ "FlexKomSigLaenge" SG_ 526 CodeCheckSts 48;
BA_ "FlexKomSID" SG_ 526 CodeCheckSts 2329;
BA_ "FlexKomIsMotorola" SG_ 526 CodeCheckSts 1;
BA_ "FlexKomComment" SG_ 526 CodeCheckSts "Transponder code packet";
BA_ "GenSigSNA" SG_ 526 ProgrammedSts "0h";
BA_ "GenSigSendType" SG_ 526 ProgrammedSts 1;
BA_ "FlexKomSigStartValue" SG_ 526 ProgrammedSts "000000800000h";
BA_ "FlexKomSigStartPos" SG_ 526 ProgrammedSts 7;
BA_ "FlexKomSigName" SG_ 526 ProgrammedSts "TRM_CodePkt";
BA_ "FlexKomSigLaenge" SG_ 526 ProgrammedSts 48;
BA_ "FlexKomSID" SG_ 526 ProgrammedSts 2329;
BA_ "FlexKomIsMotorola" SG_ 526 ProgrammedSts 1;
BA_ "FlexKomComment" SG_ 526 ProgrammedSts "Transponder code packet";
BA_ "GenSigSNA" SG_ 526 TxpID "0h";
BA_ "GenSigSendType" SG_ 526 TxpID 1;
BA_ "FlexKomSigStartValue" SG_ 526 TxpID "000000800000h";
BA_ "FlexKomSigStartPos" SG_ 526 TxpID 7;
BA_ "FlexKomSigName" SG_ 526 TxpID "TRM_CodePkt";
BA_ "FlexKomSigLaenge" SG_ 526 TxpID 48;
BA_ "FlexKomSID" SG_ 526 TxpID 2329;
BA_ "FlexKomIsMotorola" SG_ 526 TxpID 1;
BA_ "FlexKomComment" SG_ 526 TxpID "Transponder code packet";
BA_ "GenSigStartValue" SG_ 526 TxpFound 1;
BA_ "GenSigSNA" SG_ 526 TxpFound "1h";
BA_ "GenSigSendType" SG_ 526 TxpFound 1;
BA_ "FlexKomSigStartValue" SG_ 526 TxpFound "000000800000h";
BA_ "FlexKomSigStartPos" SG_ 526 TxpFound 7;
BA_ "FlexKomSigName" SG_ 526 TxpFound "TRM_CodePkt";
BA_ "FlexKomSigLaenge" SG_ 526 TxpFound 48;
BA_ "FlexKomSID" SG_ 526 TxpFound 2329;
BA_ "FlexKomIsMotorola" SG_ 526 TxpFound 1;
BA_ "FlexKomComment" SG_ 526 TxpFound "Transponder code packet";
BA_ "GenSigSNA" SG_ 527 FrameNumber "0h";
BA_ "GenSigSendType" SG_ 527 FrameNumber 1;
BA_ "FlexKomSigStartValue" SG_ 527 FrameNumber "0000000000000000h";
BA_ "FlexKomSigStartPos" SG_ 527 FrameNumber 7;
BA_ "FlexKomSigName" SG_ 527 FrameNumber "TRM_KeyPkt";
BA_ "FlexKomSigLaenge" SG_ 527 FrameNumber 64;
BA_ "FlexKomSID" SG_ 527 FrameNumber 2330;
BA_ "FlexKomIsMotorola" SG_ 527 FrameNumber 1;
BA_ "FlexKomComment" SG_ 527 FrameNumber "Transponder key packet";
BA_ "GenSigSNA" SG_ 527 TotalFrameNumber "0h";
BA_ "GenSigSendType" SG_ 527 TotalFrameNumber 1;
BA_ "FlexKomSigStartValue" SG_ 527 TotalFrameNumber "0000000000000000h";
BA_ "FlexKomSigStartPos" SG_ 527 TotalFrameNumber 7;
BA_ "FlexKomSigName" SG_ 527 TotalFrameNumber "TRM_KeyPkt";
BA_ "FlexKomSigLaenge" SG_ 527 TotalFrameNumber 64;
BA_ "FlexKomSID" SG_ 527 TotalFrameNumber 2330;
BA_ "FlexKomIsMotorola" SG_ 527 TotalFrameNumber 1;
BA_ "FlexKomComment" SG_ 527 TotalFrameNumber "Transponder key packet";
BA_ "GenSigSNA" SG_ 527 DATA1 "0h";
BA_ "GenSigSendType" SG_ 527 DATA1 1;
BA_ "FlexKomSigStartValue" SG_ 527 DATA1 "0000000000000000h";
BA_ "FlexKomSigStartPos" SG_ 527 DATA1 7;
BA_ "FlexKomSigName" SG_ 527 DATA1 "TRM_KeyPkt";
BA_ "FlexKomSigLaenge" SG_ 527 DATA1 64;
BA_ "FlexKomSID" SG_ 527 DATA1 2330;
BA_ "FlexKomIsMotorola" SG_ 527 DATA1 1;
BA_ "FlexKomComment" SG_ 527 DATA1 "Transponder key packet";
BA_ "GenSigSNA" SG_ 527 DATA2 "0h";
BA_ "GenSigSendType" SG_ 527 DATA2 1;
BA_ "FlexKomSigStartValue" SG_ 527 DATA2 "0000000000000000h";
BA_ "FlexKomSigStartPos" SG_ 527 DATA2 7;
BA_ "FlexKomSigName" SG_ 527 DATA2 "TRM_KeyPkt";
BA_ "FlexKomSigLaenge" SG_ 527 DATA2 64;
BA_ "FlexKomSID" SG_ 527 DATA2 2330;
BA_ "FlexKomIsMotorola" SG_ 527 DATA2 1;
BA_ "FlexKomComment" SG_ 527 DATA2 "Transponder key packet";
BA_ "GenSigSNA" SG_ 527 DATA3 "0h";
BA_ "GenSigSendType" SG_ 527 DATA3 1;
BA_ "FlexKomSigStartValue" SG_ 527 DATA3 "0000000000000000h";
BA_ "FlexKomSigStartPos" SG_ 527 DATA3 7;
BA_ "FlexKomSigName" SG_ 527 DATA3 "TRM_KeyPkt";
BA_ "FlexKomSigLaenge" SG_ 527 DATA3 64;
BA_ "FlexKomSID" SG_ 527 DATA3 2330;
BA_ "FlexKomIsMotorola" SG_ 527 DATA3 1;
BA_ "FlexKomComment" SG_ 527 DATA3 "Transponder key packet";
BA_ "GenSigSNA" SG_ 527 DATA4 "0h";
BA_ "GenSigSendType" SG_ 527 DATA4 1;
BA_ "FlexKomSigStartValue" SG_ 527 DATA4 "0000000000000000h";
BA_ "FlexKomSigStartPos" SG_ 527 DATA4 7;
BA_ "FlexKomSigName" SG_ 527 DATA4 "TRM_KeyPkt";
BA_ "FlexKomSigLaenge" SG_ 527 DATA4 64;
BA_ "FlexKomSID" SG_ 527 DATA4 2330;
BA_ "FlexKomIsMotorola" SG_ 527 DATA4 1;
BA_ "FlexKomComment" SG_ 527 DATA4 "Transponder key packet";
BA_ "GenSigSNA" SG_ 527 DATA5 "0h";
BA_ "GenSigSendType" SG_ 527 DATA5 1;
BA_ "FlexKomSigStartValue" SG_ 527 DATA5 "0000000000000000h";
BA_ "FlexKomSigStartPos" SG_ 527 DATA5 7;
BA_ "FlexKomSigName" SG_ 527 DATA5 "TRM_KeyPkt";
BA_ "FlexKomSigLaenge" SG_ 527 DATA5 64;
BA_ "FlexKomSID" SG_ 527 DATA5 2330;
BA_ "FlexKomIsMotorola" SG_ 527 DATA5 1;
BA_ "FlexKomComment" SG_ 527 DATA5 "Transponder key packet";
BA_ "GenSigSNA" SG_ 527 DATA6 "0h";
BA_ "GenSigSendType" SG_ 527 DATA6 1;
BA_ "FlexKomSigStartValue" SG_ 527 DATA6 "0000000000000000h";
BA_ "FlexKomSigStartPos" SG_ 527 DATA6 7;
BA_ "FlexKomSigName" SG_ 527 DATA6 "TRM_KeyPkt";
BA_ "FlexKomSigLaenge" SG_ 527 DATA6 64;
BA_ "FlexKomSID" SG_ 527 DATA6 2330;
BA_ "FlexKomIsMotorola" SG_ 527 DATA6 1;
BA_ "FlexKomComment" SG_ 527 DATA6 "Transponder key packet";
BA_ "GenSigSNA" SG_ 527 DATA7 "0h";
BA_ "GenSigSendType" SG_ 527 DATA7 1;
BA_ "FlexKomSigStartValue" SG_ 527 DATA7 "0000000000000000h";
BA_ "FlexKomSigStartPos" SG_ 527 DATA7 7;
BA_ "FlexKomSigName" SG_ 527 DATA7 "TRM_KeyPkt";
BA_ "FlexKomSigLaenge" SG_ 527 DATA7 64;
BA_ "FlexKomSID" SG_ 527 DATA7 2330;
BA_ "FlexKomIsMotorola" SG_ 527 DATA7 1;
BA_ "FlexKomComment" SG_ 527 DATA7 "Transponder key packet";
BA_ "RID" SG_ 557 Command_01 "1848";
BA_ "GenSigTimeout_IC" SG_ 557 Command_01 10500;
BA_ "GenSigSNA" SG_ 557 Command_01 "3h";
BA_ "GenSigSendType" SG_ 557 Command_01 5;
BA_ "GenSigCycleTime" SG_ 557 Command_01 1000;
BA_ "FlexKomSigStartValue" SG_ 557 Command_01 "FF0000000000FF00h";
BA_ "FlexKomSigStartPos" SG_ 557 Command_01 7;
BA_ "FlexKomSigName" SG_ 557 Command_01 "SWS8_Pkt";
BA_ "FlexKomSigLaenge" SG_ 557 Command_01 64;
BA_ "FlexKomSID" SG_ 557 Command_01 1811;
BA_ "FlexKomIsMotorola" SG_ 557 Command_01 1;
BA_ "FlexKomComment" SG_ 557 Command_01 "Steering wheel switch packet";
BA_ "RID" SG_ 557 Command_02 "1870";
BA_ "GenSigTimeout_IC" SG_ 557 Command_02 10500;
BA_ "GenSigSNA" SG_ 557 Command_02 "3h";
BA_ "GenSigSendType" SG_ 557 Command_02 5;
BA_ "GenSigCycleTime" SG_ 557 Command_02 1000;
BA_ "FlexKomSigStartValue" SG_ 557 Command_02 "FF0000000000FF00h";
BA_ "FlexKomSigStartPos" SG_ 557 Command_02 7;
BA_ "FlexKomSigName" SG_ 557 Command_02 "SWS8_Pkt";
BA_ "FlexKomSigLaenge" SG_ 557 Command_02 64;
BA_ "FlexKomSID" SG_ 557 Command_02 1811;
BA_ "FlexKomIsMotorola" SG_ 557 Command_02 1;
BA_ "FlexKomComment" SG_ 557 Command_02 "Steering wheel switch packet";
BA_ "RID" SG_ 557 Command_03 "1856";
BA_ "GenSigTimeout_IC" SG_ 557 Command_03 10500;
BA_ "GenSigSNA" SG_ 557 Command_03 "3h";
BA_ "GenSigSendType" SG_ 557 Command_03 5;
BA_ "GenSigCycleTime" SG_ 557 Command_03 1000;
BA_ "FlexKomSigStartValue" SG_ 557 Command_03 "FF0000000000FF00h";
BA_ "FlexKomSigStartPos" SG_ 557 Command_03 7;
BA_ "FlexKomSigName" SG_ 557 Command_03 "SWS8_Pkt";
BA_ "FlexKomSigLaenge" SG_ 557 Command_03 64;
BA_ "FlexKomSID" SG_ 557 Command_03 1811;
BA_ "FlexKomIsMotorola" SG_ 557 Command_03 1;
BA_ "FlexKomComment" SG_ 557 Command_03 "Steering wheel switch packet";
BA_ "RID" SG_ 557 Command_04 "1867";
BA_ "GenSigTimeout_IC" SG_ 557 Command_04 10500;
BA_ "GenSigSNA" SG_ 557 Command_04 "3h";
BA_ "GenSigSendType" SG_ 557 Command_04 5;
BA_ "GenSigCycleTime" SG_ 557 Command_04 1000;
BA_ "FlexKomSigStartValue" SG_ 557 Command_04 "FF0000000000FF00h";
BA_ "FlexKomSigStartPos" SG_ 557 Command_04 7;
BA_ "FlexKomSigName" SG_ 557 Command_04 "SWS8_Pkt";
BA_ "FlexKomSigLaenge" SG_ 557 Command_04 64;
BA_ "FlexKomSID" SG_ 557 Command_04 1811;
BA_ "FlexKomIsMotorola" SG_ 557 Command_04 1;
BA_ "FlexKomComment" SG_ 557 Command_04 "Steering wheel switch packet";
BA_ "RID" SG_ 557 Command_05 "1862";
BA_ "GenSigTimeout_IC" SG_ 557 Command_05 10500;
BA_ "GenSigSNA" SG_ 557 Command_05 "3h";
BA_ "GenSigSendType" SG_ 557 Command_05 5;
BA_ "GenSigCycleTime" SG_ 557 Command_05 1000;
BA_ "FlexKomSigStartValue" SG_ 557 Command_05 "FF0000000000FF00h";
BA_ "FlexKomSigStartPos" SG_ 557 Command_05 7;
BA_ "FlexKomSigName" SG_ 557 Command_05 "SWS8_Pkt";
BA_ "FlexKomSigLaenge" SG_ 557 Command_05 64;
BA_ "FlexKomSID" SG_ 557 Command_05 1811;
BA_ "FlexKomIsMotorola" SG_ 557 Command_05 1;
BA_ "FlexKomComment" SG_ 557 Command_05 "Steering wheel switch packet";
BA_ "RID" SG_ 557 Command_07 "1847";
BA_ "GenSigTimeout_IC" SG_ 557 Command_07 10500;
BA_ "GenSigSNA" SG_ 557 Command_07 "3h";
BA_ "GenSigSendType" SG_ 557 Command_07 5;
BA_ "GenSigCycleTime" SG_ 557 Command_07 1000;
BA_ "FlexKomSigStartValue" SG_ 557 Command_07 "FF0000000000FF00h";
BA_ "FlexKomSigStartPos" SG_ 557 Command_07 7;
BA_ "FlexKomSigName" SG_ 557 Command_07 "SWS8_Pkt";
BA_ "FlexKomSigLaenge" SG_ 557 Command_07 64;
BA_ "FlexKomSID" SG_ 557 Command_07 1811;
BA_ "FlexKomIsMotorola" SG_ 557 Command_07 1;
BA_ "FlexKomComment" SG_ 557 Command_07 "Steering wheel switch packet";
BA_ "RID" SG_ 557 Command_08 "1861";
BA_ "GenSigTimeout_IC" SG_ 557 Command_08 10500;
BA_ "GenSigSNA" SG_ 557 Command_08 "3h";
BA_ "GenSigSendType" SG_ 557 Command_08 5;
BA_ "GenSigCycleTime" SG_ 557 Command_08 1000;
BA_ "FlexKomSigStartValue" SG_ 557 Command_08 "FF0000000000FF00h";
BA_ "FlexKomSigStartPos" SG_ 557 Command_08 7;
BA_ "FlexKomSigName" SG_ 557 Command_08 "SWS8_Pkt";
BA_ "FlexKomSigLaenge" SG_ 557 Command_08 64;
BA_ "FlexKomSID" SG_ 557 Command_08 1811;
BA_ "FlexKomIsMotorola" SG_ 557 Command_08 1;
BA_ "FlexKomComment" SG_ 557 Command_08 "Steering wheel switch packet";
BA_ "RID" SG_ 557 Command_09 "1871";
BA_ "GenSigTimeout_IC" SG_ 557 Command_09 10500;
BA_ "GenSigSNA" SG_ 557 Command_09 "3h";
BA_ "GenSigSendType" SG_ 557 Command_09 5;
BA_ "GenSigCycleTime" SG_ 557 Command_09 1000;
BA_ "FlexKomSigStartValue" SG_ 557 Command_09 "FF0000000000FF00h";
BA_ "FlexKomSigStartPos" SG_ 557 Command_09 7;
BA_ "FlexKomSigName" SG_ 557 Command_09 "SWS8_Pkt";
BA_ "FlexKomSigLaenge" SG_ 557 Command_09 64;
BA_ "FlexKomSID" SG_ 557 Command_09 1811;
BA_ "FlexKomIsMotorola" SG_ 557 Command_09 1;
BA_ "FlexKomComment" SG_ 557 Command_09 "Steering wheel switch packet";
BA_ "RID" SG_ 557 Command_10 "1850";
BA_ "GenSigTimeout_IC" SG_ 557 Command_10 10500;
BA_ "GenSigSNA" SG_ 557 Command_10 "3h";
BA_ "GenSigSendType" SG_ 557 Command_10 5;
BA_ "GenSigCycleTime" SG_ 557 Command_10 1000;
BA_ "FlexKomSigStartValue" SG_ 557 Command_10 "FF0000000000FF00h";
BA_ "FlexKomSigStartPos" SG_ 557 Command_10 7;
BA_ "FlexKomSigName" SG_ 557 Command_10 "SWS8_Pkt";
BA_ "FlexKomSigLaenge" SG_ 557 Command_10 64;
BA_ "FlexKomSID" SG_ 557 Command_10 1811;
BA_ "FlexKomIsMotorola" SG_ 557 Command_10 1;
BA_ "FlexKomComment" SG_ 557 Command_10 "Steering wheel switch packet";
BA_ "RID" SG_ 557 Command_11 "1849";
BA_ "GenSigTimeout_IC" SG_ 557 Command_11 10500;
BA_ "GenSigSNA" SG_ 557 Command_11 "3h";
BA_ "GenSigSendType" SG_ 557 Command_11 5;
BA_ "GenSigCycleTime" SG_ 557 Command_11 1000;
BA_ "FlexKomSigStartValue" SG_ 557 Command_11 "FF0000000000FF00h";
BA_ "FlexKomSigStartPos" SG_ 557 Command_11 7;
BA_ "FlexKomSigName" SG_ 557 Command_11 "SWS8_Pkt";
BA_ "FlexKomSigLaenge" SG_ 557 Command_11 64;
BA_ "FlexKomSID" SG_ 557 Command_11 1811;
BA_ "FlexKomIsMotorola" SG_ 557 Command_11 1;
BA_ "FlexKomComment" SG_ 557 Command_11 "Steering wheel switch packet";
BA_ "RID" SG_ 557 Command_12 "1855";
BA_ "GenSigTimeout_IC" SG_ 557 Command_12 10500;
BA_ "GenSigSNA" SG_ 557 Command_12 "3h";
BA_ "GenSigSendType" SG_ 557 Command_12 5;
BA_ "GenSigCycleTime" SG_ 557 Command_12 1000;
BA_ "FlexKomSigStartValue" SG_ 557 Command_12 "FF0000000000FF00h";
BA_ "FlexKomSigStartPos" SG_ 557 Command_12 7;
BA_ "FlexKomSigName" SG_ 557 Command_12 "SWS8_Pkt";
BA_ "FlexKomSigLaenge" SG_ 557 Command_12 64;
BA_ "FlexKomSID" SG_ 557 Command_12 1811;
BA_ "FlexKomIsMotorola" SG_ 557 Command_12 1;
BA_ "FlexKomComment" SG_ 557 Command_12 "Steering wheel switch packet";
BA_ "RID" SG_ 557 Command_13 "1863";
BA_ "GenSigTimeout_IC" SG_ 557 Command_13 10500;
BA_ "GenSigSNA" SG_ 557 Command_13 "3h";
BA_ "GenSigSendType" SG_ 557 Command_13 5;
BA_ "GenSigCycleTime" SG_ 557 Command_13 1000;
BA_ "FlexKomSigStartValue" SG_ 557 Command_13 "FF0000000000FF00h";
BA_ "FlexKomSigStartPos" SG_ 557 Command_13 7;
BA_ "FlexKomSigName" SG_ 557 Command_13 "SWS8_Pkt";
BA_ "FlexKomSigLaenge" SG_ 557 Command_13 64;
BA_ "FlexKomSID" SG_ 557 Command_13 1811;
BA_ "FlexKomIsMotorola" SG_ 557 Command_13 1;
BA_ "FlexKomComment" SG_ 557 Command_13 "Steering wheel switch packet";
BA_ "RID" SG_ 557 Command_14 "1873";
BA_ "GenSigTimeout_IC" SG_ 557 Command_14 10500;
BA_ "GenSigSNA" SG_ 557 Command_14 "3h";
BA_ "GenSigSendType" SG_ 557 Command_14 5;
BA_ "GenSigCycleTime" SG_ 557 Command_14 1000;
BA_ "FlexKomSigStartValue" SG_ 557 Command_14 "FF0000000000FF00h";
BA_ "FlexKomSigStartPos" SG_ 557 Command_14 7;
BA_ "FlexKomSigName" SG_ 557 Command_14 "SWS8_Pkt";
BA_ "FlexKomSigLaenge" SG_ 557 Command_14 64;
BA_ "FlexKomSID" SG_ 557 Command_14 1811;
BA_ "FlexKomIsMotorola" SG_ 557 Command_14 1;
BA_ "FlexKomComment" SG_ 557 Command_14 "Steering wheel switch packet";
BA_ "RID" SG_ 557 Command_15 "1860";
BA_ "GenSigTimeout_IC" SG_ 557 Command_15 10500;
BA_ "GenSigSNA" SG_ 557 Command_15 "3h";
BA_ "GenSigSendType" SG_ 557 Command_15 5;
BA_ "GenSigCycleTime" SG_ 557 Command_15 1000;
BA_ "FlexKomSigStartValue" SG_ 557 Command_15 "FF0000000000FF00h";
BA_ "FlexKomSigStartPos" SG_ 557 Command_15 7;
BA_ "FlexKomSigName" SG_ 557 Command_15 "SWS8_Pkt";
BA_ "FlexKomSigLaenge" SG_ 557 Command_15 64;
BA_ "FlexKomSID" SG_ 557 Command_15 1811;
BA_ "FlexKomIsMotorola" SG_ 557 Command_15 1;
BA_ "FlexKomComment" SG_ 557 Command_15 "Steering wheel switch packet";
BA_ "RID" SG_ 560 AC_RQ "1237";
BA_ "GenSigSNA" SG_ 560 AC_RQ "0h";
BA_ "GenSigSendType" SG_ 560 AC_RQ 5;
BA_ "GenSigCycleTime" SG_ 560 AC_RQ 500;
BA_ "FlexKomSigStartValue" SG_ 560 AC_RQ "00h";
BA_ "FlexKomSigName" SG_ 560 AC_RQ "AC_RQ";
BA_ "FlexKomSigLaenge" SG_ 560 AC_RQ 1;
BA_ "FlexKomSID" SG_ 560 AC_RQ 27;
BA_ "FlexKomIsMotorola" SG_ 560 AC_RQ 1;
BA_ "FlexKomComment" SG_ 560 AC_RQ "A/C clutch request; [1] = A/C Clutch requested; 0 ";
BA_ "RID" SG_ 560 AC_SEL "1154";
BA_ "GenSigSNA" SG_ 560 AC_SEL "0h";
BA_ "GenSigSendType" SG_ 560 AC_SEL 5;
BA_ "GenSigCycleTime" SG_ 560 AC_SEL 500;
BA_ "FlexKomSigStartValue" SG_ 560 AC_SEL "00h";
BA_ "FlexKomSigStartPos" SG_ 560 AC_SEL 1;
BA_ "FlexKomSigName" SG_ 560 AC_SEL "AC_SEL";
BA_ "FlexKomSigLaenge" SG_ 560 AC_SEL 1;
BA_ "FlexKomSID" SG_ 560 AC_SEL 31;
BA_ "FlexKomIsMotorola" SG_ 560 AC_SEL 1;
BA_ "FlexKomComment" SG_ 560 AC_SEL "Customer has selected A/C; [1] = A/C selected; 0 =";
BA_ "RID" SG_ 560 DEFROST_SEL "1103";
BA_ "GenSigSNA" SG_ 560 DEFROST_SEL "0h";
BA_ "GenSigSendType" SG_ 560 DEFROST_SEL 5;
BA_ "GenSigCycleTime" SG_ 560 DEFROST_SEL 500;
BA_ "FlexKomSigStartValue" SG_ 560 DEFROST_SEL "00h";
BA_ "FlexKomSigStartPos" SG_ 560 DEFROST_SEL 2;
BA_ "FlexKomSigName" SG_ 560 DEFROST_SEL "DEFROST_SEL";
BA_ "FlexKomSigLaenge" SG_ 560 DEFROST_SEL 1;
BA_ "FlexKomSID" SG_ 560 DEFROST_SEL 28;
BA_ "FlexKomIsMotorola" SG_ 560 DEFROST_SEL 1;
BA_ "FlexKomComment" SG_ 560 DEFROST_SEL "Defrost select switch";
BA_ "RID" SG_ 560 PTC_Enbl "1098";
BA_ "GenSigStartValue" SG_ 560 PTC_Enbl 1;
BA_ "GenSigSNA" SG_ 560 PTC_Enbl "1h";
BA_ "GenSigSendType" SG_ 560 PTC_Enbl 5;
BA_ "GenSigCycleTime" SG_ 560 PTC_Enbl 500;
BA_ "FlexKomSigStartValue" SG_ 560 PTC_Enbl "01h";
BA_ "FlexKomSigStartPos" SG_ 560 PTC_Enbl 3;
BA_ "FlexKomSigName" SG_ 560 PTC_Enbl "PTC_Enbl";
BA_ "FlexKomSigLaenge" SG_ 560 PTC_Enbl 1;
BA_ "FlexKomSID" SG_ 560 PTC_Enbl 33;
BA_ "FlexKomIsMotorola" SG_ 560 PTC_Enbl 1;
BA_ "FlexKomComment" SG_ 560 PTC_Enbl "PTC heater enable; [1] = enable";
BA_ "RID" SG_ 560 AC_PT_Demand "1916";
BA_ "GenSigSNA" SG_ 560 AC_PT_Demand "0h";
BA_ "GenSigSendType" SG_ 560 AC_PT_Demand 5;
BA_ "GenSigCycleTime" SG_ 560 AC_PT_Demand 500;
BA_ "FlexKomSigStartValue" SG_ 560 AC_PT_Demand "00h";
BA_ "FlexKomSigStartPos" SG_ 560 AC_PT_Demand 5;
BA_ "FlexKomSigName" SG_ 560 AC_PT_Demand "AC_PT_Demand";
BA_ "FlexKomSigLaenge" SG_ 560 AC_PT_Demand 1;
BA_ "FlexKomSID" SG_ 560 AC_PT_Demand 1945;
BA_ "FlexKomIsMotorola" SG_ 560 AC_PT_Demand 1;
BA_ "FlexKomComment" SG_ 560 AC_PT_Demand "Maximum A/C demand to powertrain";
BA_ "GenSigSNA" SG_ 560 SCCActv "0h";
BA_ "GenSigSendType" SG_ 560 SCCActv 5;
BA_ "GenSigCycleTime" SG_ 560 SCCActv 500;
BA_ "FlexKomSigStartValue" SG_ 560 SCCActv "00000000h";
BA_ "FlexKomSigStartPos" SG_ 560 SCCActv 39;
BA_ "FlexKomSigName" SG_ 560 SCCActv "HVAC_A2_PDU";
BA_ "FlexKomSigLaenge" SG_ 560 SCCActv 32;
BA_ "FlexKomSID" SG_ 560 SCCActv 2867;
BA_ "FlexKomIsMotorola" SG_ 560 SCCActv 1;
BA_ "FlexKomComment" SG_ 560 SCCActv "PDU for HVAC_A2";
BA_ "GenSigSNA" SG_ 560 SCC_Inhibit "FFh";
BA_ "GenSigSendType" SG_ 560 SCC_Inhibit 5;
BA_ "GenSigCycleTime" SG_ 560 SCC_Inhibit 500;
BA_ "FlexKomSigStartValue" SG_ 560 SCC_Inhibit "00000000h";
BA_ "FlexKomSigStartPos" SG_ 560 SCC_Inhibit 39;
BA_ "FlexKomSigName" SG_ 560 SCC_Inhibit "HVAC_A2_PDU";
BA_ "FlexKomSigLaenge" SG_ 560 SCC_Inhibit 32;
BA_ "FlexKomSID" SG_ 560 SCC_Inhibit 2867;
BA_ "FlexKomIsMotorola" SG_ 560 SCC_Inhibit 1;
BA_ "FlexKomComment" SG_ 560 SCC_Inhibit "PDU for HVAC_A2";
BA_ "RID" SG_ 560 EVAP_TEMP "1096";
BA_ "GenSigSNA" SG_ 560 EVAP_TEMP "FFh";
BA_ "GenSigSendType" SG_ 560 EVAP_TEMP 5;
BA_ "GenSigCycleTime" SG_ 560 EVAP_TEMP 500;
BA_ "FlexKomSigStartValue" SG_ 560 EVAP_TEMP "00h";
BA_ "FlexKomSigStartPos" SG_ 560 EVAP_TEMP 15;
BA_ "FlexKomSigName" SG_ 560 EVAP_TEMP "EVAP_TEMP";
BA_ "FlexKomSigLaenge" SG_ 560 EVAP_TEMP 8;
BA_ "FlexKomSID" SG_ 560 EVAP_TEMP 29;
BA_ "FlexKomIsMotorola" SG_ 560 EVAP_TEMP 1;
BA_ "FlexKomComment" SG_ 560 EVAP_TEMP "AC evaporator temperature";
BA_ "RID" SG_ 560 EvapTempTar "1247";
BA_ "GenSigSNA" SG_ 560 EvapTempTar "FFh";
BA_ "GenSigSendType" SG_ 560 EvapTempTar 5;
BA_ "GenSigCycleTime" SG_ 560 EvapTempTar 500;
BA_ "FlexKomSigStartValue" SG_ 560 EvapTempTar "00h";
BA_ "FlexKomSigStartPos" SG_ 560 EvapTempTar 23;
BA_ "FlexKomSigName" SG_ 560 EvapTempTar "EvapTempTar";
BA_ "FlexKomSigLaenge" SG_ 560 EvapTempTar 8;
BA_ "FlexKomSID" SG_ 560 EvapTempTar 30;
BA_ "FlexKomIsMotorola" SG_ 560 EvapTempTar 1;
BA_ "FlexKomComment" SG_ 560 EvapTempTar "Evaporator temperature target";
BA_ "RID" SG_ 560 SpSt_DsblHVAC "1127";
BA_ "GenSigSNA" SG_ 560 SpSt_DsblHVAC "7h";
BA_ "GenSigSendType" SG_ 560 SpSt_DsblHVAC 5;
BA_ "GenSigCycleTime" SG_ 560 SpSt_DsblHVAC 500;
BA_ "FlexKomSigStartValue" SG_ 560 SpSt_DsblHVAC "00h";
BA_ "FlexKomSigStartPos" SG_ 560 SpSt_DsblHVAC 26;
BA_ "FlexKomSigName" SG_ 560 SpSt_DsblHVAC "SpSt_DsblHVAC";
BA_ "FlexKomSigLaenge" SG_ 560 SpSt_DsblHVAC 3;
BA_ "FlexKomSID" SG_ 560 SpSt_DsblHVAC 1555;
BA_ "FlexKomIsMotorola" SG_ 560 SpSt_DsblHVAC 1;
BA_ "FlexKomComment" SG_ 560 SpSt_DsblHVAC "Stop start disable from HVAC";
BA_ "RID" SG_ 560 SmrtAlt_HVAC_Disabled "3588";
BA_ "GenSigSNA" SG_ 560 SmrtAlt_HVAC_Disabled "3h";
BA_ "GenSigSendType" SG_ 560 SmrtAlt_HVAC_Disabled 5;
BA_ "GenSigCycleTime" SG_ 560 SmrtAlt_HVAC_Disabled 500;
BA_ "FlexKomSigStartValue" SG_ 560 SmrtAlt_HVAC_Disabled "00h";
BA_ "FlexKomSigStartPos" SG_ 560 SmrtAlt_HVAC_Disabled 28;
BA_ "FlexKomSigName" SG_ 560 SmrtAlt_HVAC_Disabled "SmrtAlt_HVAC_Disabled";
BA_ "FlexKomSigLaenge" SG_ 560 SmrtAlt_HVAC_Disabled 2;
BA_ "FlexKomSID" SG_ 560 SmrtAlt_HVAC_Disabled 2552;
BA_ "FlexKomIsMotorola" SG_ 560 SmrtAlt_HVAC_Disabled 1;
BA_ "FlexKomComment" SG_ 560 SmrtAlt_HVAC_Disabled "Disable the smart alternator";
BA_ "GenSigSNA" SG_ 560 EVAP_TEMP_P1C "7FFh";
BA_ "GenSigCycleTime" SG_ 560 EVAP_TEMP_P1C 500;
BA_ "FlexKomSigStartValue" SG_ 560 EVAP_TEMP_P1C "00000000h";
BA_ "FlexKomSigStartPos" SG_ 560 EVAP_TEMP_P1C 39;
BA_ "FlexKomSigName" SG_ 560 EVAP_TEMP_P1C "HVAC_A2_PDU";
BA_ "FlexKomSigLaenge" SG_ 560 EVAP_TEMP_P1C 32;
BA_ "FlexKomSID" SG_ 560 EVAP_TEMP_P1C 2867;
BA_ "FlexKomIsMotorola" SG_ 560 EVAP_TEMP_P1C 1;
BA_ "FlexKomComment" SG_ 560 EVAP_TEMP_P1C "PDU for HVAC_A2";
BA_ "GenSigTimeout_IC" SG_ 584 PN14_LS_Actv 5250;
BA_ "GenSigSNA" SG_ 584 PN14_LS_Actv "0h";
BA_ "GenSigSendType" SG_ 584 PN14_LS_Actv 5;
BA_ "GenSigCycleTime" SG_ 584 PN14_LS_Actv 500;
BA_ "FlexKomSigStartValue" SG_ 584 PN14_LS_Actv "0000FFFFFF03FFFFh";
BA_ "FlexKomSigStartPos" SG_ 584 PN14_LS_Actv 7;
BA_ "FlexKomSigName" SG_ 584 PN14_LS_Actv "PN14_LHC_Stat";
BA_ "FlexKomSigLaenge" SG_ 584 PN14_LS_Actv 64;
BA_ "FlexKomSID" SG_ 584 PN14_LS_Actv 1092;
BA_ "FlexKomIsMotorola" SG_ 584 PN14_LS_Actv 1;
BA_ "FlexKomComment" SG_ 584 PN14_LS_Actv "14 V powernet limp-home cutoff state";
BA_ "GenSigSNA" SG_ 584 Batt_ST_Crit "0h";
BA_ "GenSigSendType" SG_ 584 Batt_ST_Crit 5;
BA_ "GenSigCycleTime" SG_ 584 Batt_ST_Crit 500;
BA_ "FlexKomSigStartValue" SG_ 584 Batt_ST_Crit "0000FFFFFF03FFFFh";
BA_ "FlexKomSigStartPos" SG_ 584 Batt_ST_Crit 7;
BA_ "FlexKomSigName" SG_ 584 Batt_ST_Crit "PN14_LHC_Stat";
BA_ "FlexKomSigLaenge" SG_ 584 Batt_ST_Crit 64;
BA_ "FlexKomSID" SG_ 584 Batt_ST_Crit 1092;
BA_ "FlexKomIsMotorola" SG_ 584 Batt_ST_Crit 1;
BA_ "FlexKomComment" SG_ 584 Batt_ST_Crit "14 V powernet limp-home cutoff state";
VAL_ 315 DriveMdstat 0 "Drive_Mode_Unavailable" 1 "Hybrid" 2 "Sport" 4 "ESave" 8 "Electric" 15 "SNA" ;
VAL_ 315 DrvMode_PopUpRqst 0 "TM0" 1 "TM1" 2 "TM2" 3 "TM3" 4 "TM4" 5 "TM5" 6 "TM6" 7 "TM7" 8 "TM8" 9 "TM9" 10 "TM10" 11 "TM11" 12 "TM12" 13 "TM13" 14 "TM14" 15 "SNA" ;
VAL_ 315 GrShiftIndication 0 "NONE" 1 "UP" 2 "DOWN" 3 "SNA" ;
VAL_ 315 HCPPopUpMessage12 0 "MaxRegen_Off" 1 "MaxRegen_ON" 2 "MaxRegen_Unavailable" 3 "Not_Defined" ;
VAL_ 315 MaxRegenTelltale 0 "Off" 1 "White" 2 "Green" 3 "Not_Defined" ;
VAL_ 317 ETC_IND_LMP 0 "OFF" 1 "ON" 2 "ON_Flashing" 3 "SNA" ;
VAL_ 317 EngOilIndLmp_On_Rq 1 "SNA" ;
VAL_ 317 OIL_TEMP_IND_RQ 0 "IND_LMP_OFF" 1 "IND_LMP_ON" 2 "IND_LMP_FLASH" 3 "SNA" ;
VAL_ 317 OIL_TEMP_CHM_RQ 0 "NO_CHM" 1 "1_CHM" 2 "SLOW_CHM" 3 "FAST_CHM" ;
VAL_ 317 OIL_PRESS 255 "SNA" ;
VAL_ 317 EngOilTemp 255 "SNA" ;
VAL_ 317 FuelCons 65535 "SNA" ;
VAL_ 317 DefFuelEcon 255 "SNA" ;
VAL_ 317 EngRun_Stat 0 "STOP" 1 "START" 2 "IDLE_UNSTBL" 3 "IDLE_STBL" 4 "UNLIMITED" 5 "LIMITED" 6 "NDEF6" 7 "SNA" ;
VAL_ 319 Pitch_Angle 255 "SNA" ;
VAL_ 319 Roll_Angle 255 "SNA" ;
VAL_ 319 IBS3_Ibatt 65535 "SNA" ;
VAL_ 319 IBS3_Vbatt 511 "SNA" ;
VAL_ 319 CurrBattFailStatus 0 "Fail_not_present" 1 "Fail_present" ;
VAL_ 319 VoltBattFailStatus 0 "Fail_not_present" 1 "Fail_present" ;
VAL_ 319 IBS3_Error_Internal 0 "NO_ERROR" 1 "ERROR" ;
VAL_ 319 RsErrIBS3 0 "NO_ERROR" 1 "ERROR" ;
VAL_ 319 CBCSAMFailSts 0 "Fail_not_present" 1 "Fail_present" ;
VAL_ 321 HEV_LMP_RQ 0 "OFF" 1 "ON" 2 "BLINK" 3 "SNA" ;
VAL_ 321 BatPwrUsage_V 0 "Valid" 1 "Not_Valid" ;
VAL_ 321 Est_Range 255 "SNA" ;
VAL_ 321 MaxRegenLedCmd 0 "OFF" 1 "Cont" 2 "Blink" 3 "SNA" ;
VAL_ 321 R134a_PressSts 511 "SNA" ;
VAL_ 321 Echarge_Type_Cnfm 0 "Battery_Save" 1 "Battery_Charge" ;
VAL_ 321 Echarge_SOCRange_Cnfm 0 "40_Percent" 1 "60_Percent" 2 "80_Percent" 3 "Empty_Space" ;
VAL_ 321 HVBatSOH 255 "SNA" ;
VAL_ 321 EM_OverHeated_VehSpdLimited 0 "False" 1 "True" ;
VAL_ 323 PCPM_PumpSpeedAct 127 "SNA" ;
VAL_ 333 VVT_ExhCam1Pos 0 "SNA" ;
VAL_ 333 VVT_ExhCam2Pos 0 "SNA" ;
VAL_ 333 VVT_IntCam1Pos 0 "SNA" ;
VAL_ 333 VVT_IntCam2Pos 0 "SNA" ;
VAL_ 333 GF_Charge 65535 "SNA" ;
VAL_ 333 RelativeThrtPct 255 "SNA" ;
VAL_ 334 RawPVS1 255 "SNA" ;
VAL_ 334 RawPVS2 255 "SNA" ;
VAL_ 334 RawTPS1 255 "SNA" ;
VAL_ 334 RawTPS2 255 "SNA" ;
VAL_ 334 RelativePdl 255 "SNA" ;
VAL_ 334 RelativeThrt 255 "SNA" ;
VAL_ 334 MAP 255 "SNA" ;
VAL_ 343 LeakCheckTimerValue 511 "SNA" ;
VAL_ 343 RefuelEvent 0 "NONE" 1 "PEND" 2 "TRUE" 3 "COMP" 4 "FAULT" ;
VAL_ 343 StartProtectionInhibit 0 "Default" 2 "Crank_Inhibit" 3 "SNA" ;
VAL_ 343 LeakTestSts 0 "NONE" 1 "PEND" 2 "COMPLETE" 3 "DELAY" ;
VAL_ 343 RefuelIndication 0 "NONE" 1 "WAIT" 2 "PARK" 3 "OK" 4 "DOOR" 5 "BLOCKAGE" 6 "SERVICE" ;
VAL_ 343 SAMInfo 0 "SAMOFF" 1 "Engine_OFF" 2 "Cranking_management" 3 "ColdEngineManagement" 4 "PassiveBoost" 5 "Steady_State" 6 "RegenerativeBraking" 7 "QuickCharge" 8 "Auto_Shut_OFF" 9 "Shut_OFF" 10 "SAM_recovery" 11 "Battery_Regeneration" 15 "SNA" ;
VAL_ 343 StarterProtectionTime 255 "SNA" ;
VAL_ 347 RevOilLifeRst 65535 "SNA" ;
VAL_ 423 ESLSts 0 "Undefined_Position" 3 "Lock" 5 "Unlock" 7 "SNA" ;
VAL_ 448 MsgCrankInGear 0 "MSG_DEFAULT" 1 "MSG_ACTIVE" 3 "SNA" ;
VAL_ 448 RFFuncReq 0 "NO_BASIC_REQUEST" 1 "LOCK_REQUEST" 2 "RELOCK_REQUEST" 3 "DRIVER_UNLOCK_REQUEST" 4 "ALL_UNLOCK_REQUEST" 5 "TRUNK_PLG_TOGGLE_REQUEST" 6 "LEFT_SLIDER_TOGGLE_REQUEST" 7 "RIGHT_SLIDER_TOGGLE_REQUEST" 8 "FLIPPER_GLASS_REQUEST" 9 "REMOTE_START_ON" 10 "REMOTE_START_OFF" 11 "GLOBAL_WINDOW_DOWN_REQUEST" 12 "OPEN_CONVERTIBLE_TOP" 13 "CLOSE_CONVERTIBLE_TOP" 14 "PANIC_TOGGLE_REQUEST" 15 "DRIVER_TOGGLE_REQUEST" 16 "PASSENGER_TOGGLE_REQUEST" 17 "ExtLightReq" 18 "AirSuspReq" 19 "AirSuspCancel" 20 "GLBL_WIN_UP_RQ" 21 "CAR_FINDER_REQUEST" 22 "TRUNK_PLG_BTN_PRESSED" 23 "TRUNK_PLG_STOP_REQUEST" 24 "TRUNK_PLG_OPEN_REQUEST" 25 "TRUNK_PLG_CLOSE_REQUEST" 26 "VTA_RQ" 27 "RAP_UNLOCK_REQUEST" 28 "ABORT_CRANKING_ON_REQUEST" 29 "ABORT_CRANKING_OFF_REQUEST" 30 "HEADLIGHTS_OFF_DELAY" 31 "SNA" ;
VAL_ 448 RFReq 0 "REQUESTOR_DEFAULT" 1 "REQUESTOR_RKE" 2 "REQUESTOR_PE" 3 "REQUESTOR_REMOTESTART" 4 "REQUESTOR_UCONNECT" 5 "REQUESTOR_PE_HANDSFREE" 7 "SNA" ;
VAL_ 448 RFCfgReq 0 "DEFAULT" 1 "HORN_CHIRP_TOGGLE" 2 "OPTICAL_CHIRP_TOGGLE" 3 "DRIVER_UNLOCK_FIRST_TOGGLE" 7 "SNA" ;
VAL_ 448 RFFobNum 0 "FOB_DEFAULT" 1 "FOB_1" 2 "FOB_2" 3 "FOB_3" 4 "FOB_4" 5 "FOB_5" 6 "FOB_6" 7 "FOB_7" 8 "FOB_8" 15 "SNA" ;
VAL_ 456 VTA_STAT 0 "VTA_DISARM" 1 "VTA_PREARM" 2 "VTA_ARM" 3 "VTA_LGT" 4 "VTA_LGT_HORN" 5 "VTA_TAMP" 6 "VTA_ITM_Alarm" 7 "SNA" ;
VAL_ 456 FOA_Msg_Req 0 "No_Msg" 1 "FOA_TURNED_OFF_ALERT" 2 "FOA_FAULTED" 3 "FOA_ARMED_ALERT" 4 "FOA_LEVEL1_ALERT" 5 "FOA_LEVEL2_ALERT" 6 "FOA_LEVEL2_ALERT_CONNECTIVITY" 7 "SNA" ;
VAL_ 463 CodeCheckStsESL 0 "No_Code" 1 "CodeCheck_OK" 2 "CodeCheck_Fault" ;
VAL_ 463 ESLFeedbackCmd 0 "Undefined_Position" 3 "Lock" 5 "Unlock" 7 "SNA" ;
VAL_ 464 SRS_IndLmp_Rq 0 "OFF" 1 "CONT" 2 "BLINK" 3 "SNA" ;
VAL_ 464 DrvSbltUnFltr 0 "BUCKLED" 1 "UNBUCKLED" 2 "LOW" 3 "HIGH" 7 "SNA" ;
VAL_ 464 DRV_SEATBELT 0 "DRV_SEATBELT_OK" 1 "DRV_SEATBELT_NOK" 2 "SEATBELT_FAIL" 3 "SNA" ;
VAL_ 464 PSG_SEATBELT 0 "PSG_SEATBELT_OK" 1 "PSG_SEATBELT_NOK" 2 "SEATBELT_FAIL" 3 "SNA" ;
VAL_ 464 PsngrBagChargeSts 0 "Active" 1 "Not_Active" 2 "Not_Present" 3 "SNA" ;
VAL_ 464 PSG_ODS_STAT 0 "ODS_STAT_NOCC" 1 "ODS_STAT_OCC" 2 "ODS_FAULT" 3 "SNA" ;
VAL_ 489 PTS_PopUpRqst 0 "TM0" 1 "TM1" 2 "TM2" 3 "TM3" 4 "TM4" 5 "TM5" 6 "TM6" 7 "TM7" 8 "TM8" 9 "TM9" 10 "TM10" 11 "TM11" 12 "TM12" 13 "TM13" 14 "TM14" 15 "TM15" 16 "TM16" 17 "TM17" 18 "TM18" 19 "TM19" 20 "TM20" 21 "TM21" 22 "TM22" 23 "TM23" 24 "TM24" 25 "TM25" 26 "TM26" 27 "TM27" 28 "TM28" 29 "TM29" 30 "TM30" 31 "TM31" 32 "TM32" 33 "TM33" 34 "TM34" 35 "TM35" 36 "TM36" 37 "TM37" 38 "TM38" 39 "TM39" 40 "TM40" 41 "TM41" 42 "TM42" 43 "TM43" 44 "TM44" 45 "TM45" 46 "TM46" 47 "TM47" 48 "TM48" 49 "TM49" 50 "TM50" 51 "TM51" 52 "TM52" 53 "TM53" 54 "TM54" 55 "TM55" 56 "TM56" 57 "TM57" 58 "TM58" 59 "TM59" 60 "TM60" 61 "TM61" 62 "TM62" 63 "TM63" 64 "TM64" 65 "TM65" 66 "TM66" 67 "TM67" 68 "TM68" 69 "TM69" 70 "TM70" 71 "TM71" 72 "TM72" 73 "TM73" 74 "TM74" 75 "TM75" 76 "TM76" 77 "TM77" 78 "TM78" 79 "TM79" 80 "TM80" 81 "TM81" 82 "TM82" 83 "TM83" 84 "TM84" 85 "TM85" 86 "TM86" 87 "TM87" 88 "TM88" 89 "TM89" 90 "TM90" 91 "TM91" 92 "TM92" 93 "TM93" 94 "TM94" 95 "TM95" 96 "TM96" 97 "TM97" 98 "TM98" 99 "TM99" 100 "TM100" 255 "SNA" ;
VAL_ 502 PTS_CFG_STAT 0 "OFF" 1 "SND" 2 "SND_DISP" 3 "SNA" ;
VAL_ 502 PTS_AlrFL 0 "PTS_ALR_NOD" 1 "ARC1" 2 "ARC2" 3 "ARC3" 4 "ARC4" 5 "ARC5" 6 "ARC6" 7 "ARC7" 8 "ARC8" 15 "SNA" ;
VAL_ 502 PTS_GraphicFL 0 "SLOW_FLS_RQ" 1 "FAST_FLS_RQ" 2 "CONT_FLS_RQ" 3 "None" ;
VAL_ 502 PTS_AlrFR 0 "PTS_ALR_NOD" 1 "ARC1" 2 "ARC2" 3 "ARC3" 4 "ARC4" 5 "ARC5" 6 "ARC6" 7 "ARC7" 8 "ARC8" 15 "SNA" ;
VAL_ 502 PTS_GraphicFR 0 "SLOW_FLS_RQ" 1 "FAST_FLS_RQ" 2 "CONT_FLS_RQ" 3 "None" ;
VAL_ 502 PTS_AlrRL 0 "PTS_ALR_NOD" 1 "ARC1" 2 "ARC2" 3 "ARC3" 4 "ARC4" 5 "ARC5" 6 "ARC6" 7 "ARC7" 8 "ARC8" 15 "SNA" ;
VAL_ 502 PTS_GraphicRL 0 "SLOW_FLS_RQ" 1 "FAST_FLS_RQ" 2 "CONT_FLS_RQ" 3 "None" ;
VAL_ 502 PTS_AlrRR 0 "PTS_ALR_NOD" 1 "ARC1" 2 "ARC2" 3 "ARC3" 4 "ARC4" 5 "ARC5" 6 "ARC6" 7 "ARC7" 8 "ARC8" 15 "SNA" ;
VAL_ 502 PTS_GraphicRR 0 "SLOW_FLS_RQ" 1 "FAST_FLS_RQ" 2 "CONT_FLS_RQ" 3 "None" ;
VAL_ 502 PTS_AlrFC 0 "PTS_ALR_NOD" 1 "ARC1" 2 "ARC2" 3 "ARC3" 4 "ARC4" 5 "ARC5" 6 "ARC6" 7 "ARC7" 8 "ARC8" 15 "SNA" ;
VAL_ 502 PTS_GraphicFC 0 "SLOW_FLS_RQ" 1 "FAST_FLS_RQ" 2 "CONT_FLS_RQ" 3 "None" ;
VAL_ 502 PTS_AlrRC 0 "PTS_ALR_NOD" 1 "ARC1" 2 "ARC2" 3 "ARC3" 4 "ARC4" 5 "ARC5" 6 "ARC6" 7 "ARC7" 8 "ARC8" 15 "SNA" ;
VAL_ 502 PTS_GraphicRC 0 "SLOW_FLS_RQ" 1 "FAST_FLS_RQ" 2 "CONT_FLS_RQ" 3 "None" ;
VAL_ 502 PTS_STAT 0 "OFF" 1 "CONT" 2 "BLINK" 3 "SNA" ;
VAL_ 503 xtended_AvgFuelLvl 4095 "SNA" ;
VAL_ 503 Est_Range_Disp 255 "SNA" ;
VAL_ 503 VehSpdDisp 65535 "SNA" ;
VAL_ 515 ControlEncodingRq 5 "ControlEncoding_ENQ" 6 "ControlEncoding_ACK" 21 "ControlEncoding_NACK" 129 "ControlEncoding_NACKp" 132 "ControlEncoding_EOTp" 133 "ControlEncoding_ENQp" 134 "ControlEncoding_ACK1p" 135 "ControlEncoding_ACK2p" ;
VAL_ 516 ControlEncodingRsp 16 "ControlEncoding_TEN" 153 "ControlEncoding_UC" 170 "ControlEncoding_PRA" 171 "ControlEncoding_PVA" ;
VAL_ 517 ControlEncodingRq 5 "ControlEncoding_ENQ" 6 "ControlEncoding_ACK" 21 "ControlEncoding_NACK" 129 "ControlEncoding_NACKp" 132 "ControlEncoding_EOTp" 133 "ControlEncoding_ENQp" 134 "ControlEncoding_ACK1p" 135 "ControlEncoding_ACK2p" ;
VAL_ 518 ControlEncoding_Rsp 16 "ControlEncoding_TEN" 153 "ControlEncoding_UC" 170 "ControlEncoding_PRA" 171 "ControlEncoding_PVA" ;
VAL_ 523 ESLLockUnlockReq 0 "Not_Request" 1 "Unlock" 2 "Lock" ;
VAL_ 526 CodeCheckSts 0 "No_Code" 1 "CodeCheck_OK" 2 "CodeCheck_Fault" ;
VAL_ 526 TxpID 0 "Transponder_Not_Authenticated" 1 "Transponder_1_Authenticated" 2 "Transponder_2_Authenticated" 3 "Transponder_3_Authenticated" 4 "Transponder_4_Authenticated" 5 "Transponder_5_Authenticated" 6 "Transponder_6_Authenticated" 7 "Transponder_7_Authenticated" 8 "Transponder_8_Authenticated" 9 "Transponder_9_Authenticated" 10 "Transponder_10_Authenticated" 11 "Transponder_11_Authenticated" 12 "Transponder_12_Authenticated" 13 "Transponder_13_Authenticated" 14 "Transponder_14_Authenticated" 15 "Transponder_15_Authenticated" ;
VAL_ 527 FrameNumber 0 "Frame_1" 1 "Frame_2" 2 "Frame_3" 3 "Frame_4" 4 "Frame_5" 5 "Frame_6" 6 "Frame_7" 7 "Frame_8" 8 "Frame_9" 9 "Frame_10" 10 "Frame_11" 11 "Frame_12" 12 "Frame_13" 13 "Frame_14" 14 "Frame_15" 15 "Frame_16" ;
VAL_ 527 TotalFrameNumber 0 "One_Frame" 1 "Two_Frames" 2 "Three_Frames" 3 "Four_Frames" 4 "Five_Frames" 5 "Six_Frames" 6 "Seven_Frames" 7 "Eight_Frame" 8 "Nine_Frames" 9 "Ten_Frames" 10 "Eleven_Frames" 11 "Twelve_Frames" 12 "Thirteen_Frames" 13 "Fourteen_Frames" 14 "Fifteen_Frames" 15 "Sixteen_Frames" ;
VAL_ 557 Command_01 0 "NOT_PSD" 1 "PSD" 3 "SNA" ;
VAL_ 557 Command_02 0 "NOT_PSD" 1 "PSD" 3 "SNA" ;
VAL_ 557 Command_03 0 "NOT_PSD" 1 "PSD" 3 "SNA" ;
VAL_ 557 Command_04 0 "NOT_PSD" 1 "PSD" 3 "SNA" ;
VAL_ 557 Command_05 0 "NOT_PSD" 1 "PSD" 3 "SNA" ;
VAL_ 557 Command_07 0 "NOT_PSD" 1 "PSD" 3 "SNA" ;
VAL_ 557 Command_08 0 "NOT_PSD" 1 "PSD" 3 "SNA" ;
VAL_ 557 Command_09 0 "NOT_PSD" 1 "PSD" 3 "SNA" ;
VAL_ 557 Command_10 0 "NOT_PSD" 1 "PSD" 3 "SNA" ;
VAL_ 557 Command_11 0 "NOT_PSD" 1 "PSD" 3 "SNA" ;
VAL_ 557 Command_12 0 "NOT_PSD" 1 "PSD" 3 "SNA" ;
VAL_ 557 Command_13 0 "NOT_PSD" 1 "PSD" 3 "SNA" ;
VAL_ 557 Command_14 0 "NOT_PSD" 1 "PSD" 3 "SNA" ;
VAL_ 557 Command_15 0 "NOT_PSD" 1 "PSD" 3 "SNA" ;
VAL_ 560 PTC_Enbl 1 "SNA" ;
VAL_ 560 SCC_Inhibit 0 "INHIBIT_DEFAUILT" 1 "TIME_OUT_RUN" 2 "TIME_OUT_CUST_MODE" 3 "KEY_IN_RUN" 4 "DRV_DOOR_AJAR" 5 "PASS_DOOR_AJAR" 6 "LR_DOOR_AJAR" 7 "RR_DOOR_AJAR" 8 "START_COUNTER" 9 "FAIL_COUNTER" 10 "LOW_RPM_SHUTDOWN" 11 "KEY_IN_IGN" 12 "BRAKE_PRESSED" 13 "HAZARD_LAMP_ON" 14 "NOT_IN_PARK" 15 "VEH_SPEED_HIGH" 16 "HOOD_AJAR" 17 "TRUNK_LIFTGATE" 18 "VTA_ALARM" 19 "PANIC_MODE" 20 "BATT_VOLT_HIGH" 21 "BATT_VOLT_LOW" 22 "POWER_LOSS" 23 "MIL_ON" 24 "OIL_PRESSURE_LOW" 25 "COOLANT_TEMP_HIGH" 26 "RPM_HIGH" 27 "CRANK_NO_START" 28 "REMOTE_OFF_RQ" 29 "RS_DISABLED_PREV" 30 "NOT_CONFIGURED" 31 "NO_HOOD_SWITCH" 32 "NO_AUTO_TRANS" 33 "NOT_ENABLED" 34 "INVALID_SKIM_KEY" 35 "IGN_SNA" 36 "IGN_NOT_LOCK" 37 "GLOW_PLUG_TIMEOUT" 38 "LOW_FUEL" 39 "ETC_LAMP_ON" 40 "LOGISTIC_MODE" 41 "COLD_START_LAMP" 42 "ESL_NOT_UNLOCK" 43 "RFHUB_HS_FAIL" 44 "PSA_Not_Active" 45 "ABORT_CRANKING_ENABLE" 255 "SNA" ;
VAL_ 560 EVAP_TEMP 255 "SNA" ;
VAL_ 560 EvapTempTar 255 "SNA" ;
VAL_ 560 SpSt_DsblHVAC 0 "SPST_ON" 1 "CABIN_HI" 2 "CABIN_LO" 3 "MAX_AC" 4 "FT_DEFROST" 5 "EBL" 7 "SNA" ;
VAL_ 560 SmrtAlt_HVAC_Disabled 0 "DISABLED" 1 "ENABLED" 3 "SNA" ;
VAL_ 560 EVAP_TEMP_P1C 2047 "SNA" ;
